VERSION ""

NS_ :

BS_:
BU_: Turbocharger OnBoardDataLogger OffBoardDiagnosticTool2 OffBoardDiagnosticTool1 FileServer ParkingBrakeController SeatControl2 FanDriveController SteeringColumnUnit CommunicationUnitRadio CommunicationUnitSatellite CommunicationUnitCellular PropulsionBatteryCharger ChassisController2 ChassisController1 EngineValveControl AuxiliaryHeater2 AuxiliaryHeater1 ClutchUnit RampControl InformationSystem1 SuspensionSystemController2 OilSensor VehicleDynamicStability ExhaustEmissionController TransmissionDisplay2 TransmissionDisplay1 ClimateControl2 WaterPumpController RearAxleSteeringController LightingOperatorControl SeatController1 IgnitionController2 IgnitionController1 TirePressureController CabController2 CabController1 PneumaticSystemController SuspensionSystemController1 HydraulicPumpController EnduranceBrakingSystem RetarderExhaustEngine2 OnBoardDiagnosticUnit HeadwayController RetarderExhaustEngine1 CabDisplay1 ManagementComputer VirtualTerminal OffVehicleGateway PowerTakeOffFront HitchControl AuxiliaryValveControl BodyController TractorTrailerBridge1 StarterSystem ElectricalSystem VehicleSecurity VehicleNavigation AerodynamicControl ElectricalChargingSystem ClimateControl1 TripRecorder InstrumentCluster SuspensionDriveAxle2 SuspensionDriveAxle1 SuspensionSteerAxle SteeringController FuelSystem CruiseControl RetarderDriveline RetarderEngine BrakesDriveAxle2 BrakesDriveAxle1 BrakesSystemController BrakesSteerAxle AxleDrive2 AxleDrive1 AxleSteering PowerTakeOff ShiftConsoleSecondary ShiftConsolePrimary Transmission2 Transmission1 Engine2 Engine1 Guidance Unnamed9933
BO_ 2566896298 SteerEngage: 0 Vector__XXX
   SG_ TrailerWeight : 0|16@1+ (2,0) [0|128510] "kg" Vector__XXX
   SG_ ReferenceTirePressSetting : 0|8@1+ (8,0) [0|2000] "kPa" Vector__XXX
   SG_ ReferenceTirePress : 0|8@1+ (8,0) [0|2000] "kPa" Vector__XXX
   SG_ TirePressThresholdDetection : 0|3@1+ (1,0) [0|7] "" Vector__XXX
   SG_ TireAirLeakageRate : 0|16@1+ (0.1,0) [0|6425.5] "Pa/s" Vector__XXX
   SG_ CTIWheelEndElectricalFault : 0|2@1+ (1,0) [0|3] "" Vector__XXX
   SG_ CTITireStatus : 0|2@1+ (1,0) [0|3] "" Vector__XXX
   SG_ CTIWheelSensorStatus : 0|2@1+ (1,0) [0|3] "" Vector__XXX
   SG_ TireTemp : 0|16@1+ (0.03125,-273) [-273|1734.97] "deg C" Vector__XXX
   SG_ TirePress : 0|8@1+ (4,0) [0|1000] "kPa" Vector__XXX
   SG_ SteerEngaged : 0|1@0+ (1,0) [0|1] "" Vector__XXX
   SG_ SteerEngage : 0|16@1+ (1,0) [0|1] "" Vector__XXX

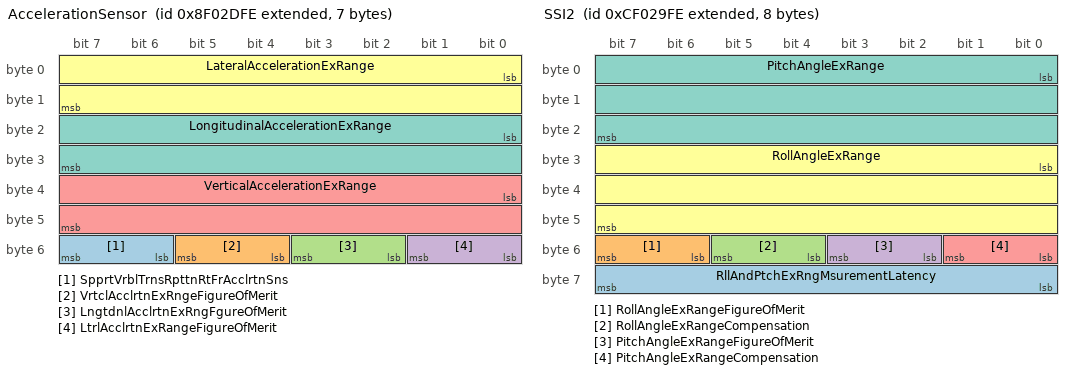
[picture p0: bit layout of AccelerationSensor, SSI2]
BO_ 2297441790 AccelerationSensor: 7 Vector__XXX
   SG_ SpprtVrblTrnsRpttnRtFrAcclrtnSns : 54|2@1+ (1,0) [0|3] "" Vector__XXX
   SG_ VrtclAcclrtnExRngeFigureOfMerit : 52|2@1+ (1,0) [0|3] "" Vector__XXX
   SG_ LngtdnlAcclrtnExRngFgureOfMerit : 50|2@1+ (1,0) [0|3] "" Vector__XXX
   SG_ LtrlAcclrtnExRangeFigureOfMerit : 48|2@1+ (1,0) [0|3] "" Vector__XXX
   SG_ VerticalAccelerationExRange : 32|16@1+ (0.01,-320) [-320|322.55] "m/s/s" Vector__XXX
   SG_ LateralAccelerationExRange : 0|16@1+ (0.01,-320) [-320|322.55] "m/s/s" Vector__XXX
   SG_ LongitudinalAccelerationExRange : 16|16@1+ (0.01,-320) [-320|322.55] "m/s/s" Vector__XXX

BO_ 2566712062 VEP4: 8 Vector__XXX
   SG_ HybrdBatteryPackRemainingCharge : 0|16@1+ (0.0025,0) [0|160.637] "%" Vector__XXX

BO_ 2364549630 SSI2: 8 Vector__XXX
   SG_ RllAndPtchExRngMsurementLatency : 56|8@1+ (0.5,0) [0|125] "ms" Vector__XXX
   SG_ RollAngleExRangeFigureOfMerit : 54|2@1+ (1,0) [0|3] "" Vector__XXX
   SG_ RollAngleExRangeCompensation : 52|2@1+ (1,0) [0|3] "" Vector__XXX
   SG_ PitchAngleExRangeFigureOfMerit : 50|2@1+ (1,0) [0|3] "" Vector__XXX
   SG_ PitchAngleExRangeCompensation : 48|2@1+ (1,0) [0|3] "" Vector__XXX
   SG_ RollAngleExRange : 24|24@1+ (3.05176e-05,-250) [-250|251] "deg" Vector__XXX
   SG_ PitchAngleExRange : 0|24@1+ (3.05176e-05,-250) [-250|251] "deg" Vector__XXX

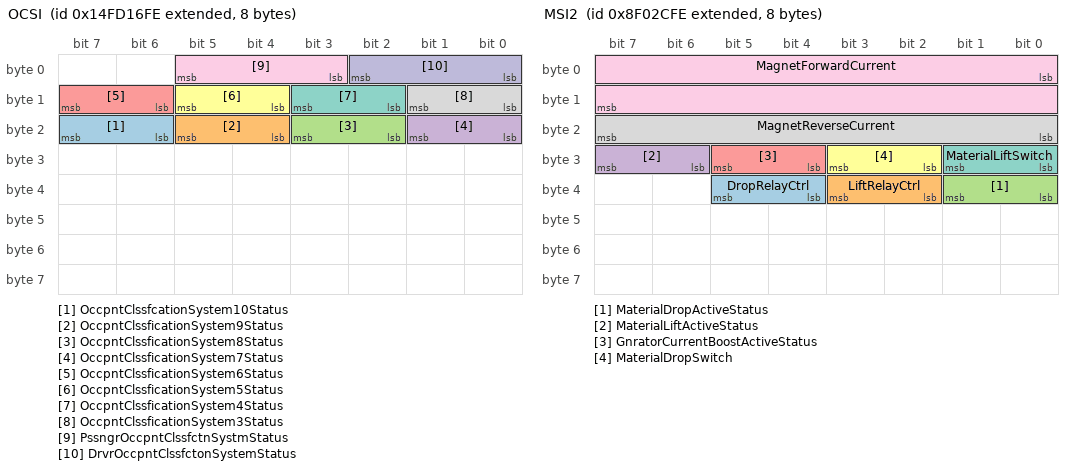
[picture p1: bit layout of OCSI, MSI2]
BO_ 2499614462 OCSI: 8 Vector__XXX
   SG_ OccpntClssfcationSystem10Status : 22|2@1+ (1,0) [0|3] "" Vector__XXX
   SG_ OccpntClssficationSystem9Status : 20|2@1+ (1,0) [0|3] "" Vector__XXX
   SG_ OccpntClssficationSystem8Status : 18|2@1+ (1,0) [0|3] "" Vector__XXX
   SG_ OccpntClssficationSystem7Status : 16|2@1+ (1,0) [0|3] "" Vector__XXX
   SG_ OccpntClssficationSystem6Status : 14|2@1+ (1,0) [0|3] "" Vector__XXX
   SG_ OccpntClssficationSystem5Status : 12|2@1+ (1,0) [0|3] "" Vector__XXX
   SG_ OccpntClssficationSystem4Status : 10|2@1+ (1,0) [0|3] "" Vector__XXX
   SG_ OccpntClssficationSystem3Status : 8|2@1+ (1,0) [0|3] "" Vector__XXX
   SG_ PssngrOccpntClssfctnSystmStatus : 3|3@1+ (1,0) [0|7] "" Vector__XXX
   SG_ DrvrOccpntClssfctonSystemStatus : 0|3@1+ (1,0) [0|7] "" Vector__XXX

BO_ 2560098046 NCS: 8 Vector__XXX
   SG_ CabNoiseCtrlTuningStatus : 2|4@1+ (1,0) [0|15] "" Vector__XXX
   SG_ CabNoiseCtrlStatus : 0|2@1+ (1,0) [0|3] "" Vector__XXX

BO_ 2560163582 NC1: 8 Vector__XXX
   SG_ CabNoiseCtrlTuningState : 2|3@1+ (1,0) [0|7] "" Vector__XXX
   SG_ CabNoiseCtrlState : 0|2@1+ (1,0) [0|3] "" Vector__XXX

BO_ 2297441534 MSI2: 8 Vector__XXX
   SG_ DropRelayCtrl : 36|2@1+ (1,0) [0|3] "" Vector__XXX
   SG_ LiftRelayCtrl : 34|2@1+ (1,0) [0|3] "" Vector__XXX
   SG_ MaterialDropActiveStatus : 32|2@1+ (1,0) [0|3] "" Vector__XXX
   SG_ MaterialLiftActiveStatus : 30|2@1+ (1,0) [0|3] "" Vector__XXX
   SG_ GnratorCurrentBoostActiveStatus : 28|2@1+ (1,0) [0|3] "" Vector__XXX
   SG_ MaterialDropSwitch : 26|2@1+ (1,0) [0|3] "" Vector__XXX
   SG_ MaterialLiftSwitch : 24|2@1+ (1,0) [0|3] "" Vector__XXX
   SG_ MagnetReverseCurrent : 16|8@1+ (1,0) [0|250] "A" Vector__XXX
   SG_ MagnetForwardCurrent : 0|16@1+ (1,0) [0|64255] "Amps" Vector__XXX

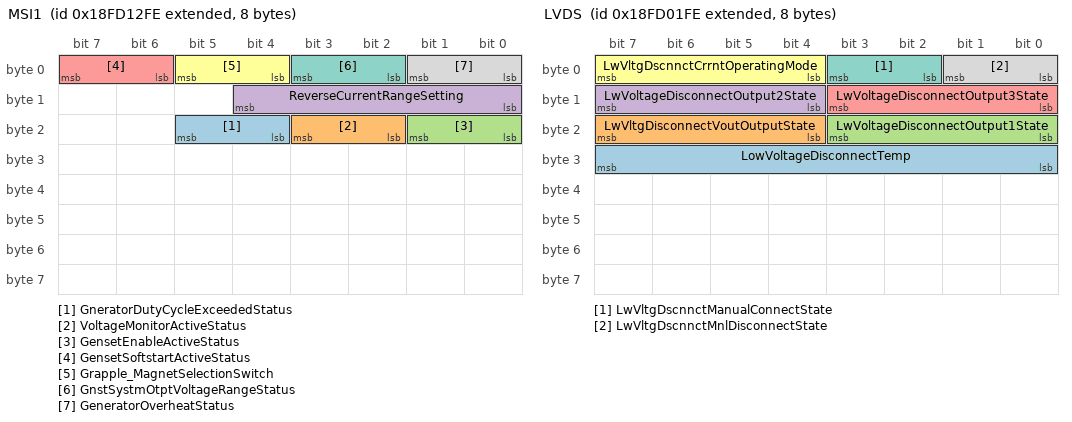
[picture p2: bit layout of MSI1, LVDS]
BO_ 2566722302 MSI1: 8 Vector__XXX
   SG_ GneratorDutyCycleExceededStatus : 20|2@1+ (1,0) [0|3] "" Vector__XXX
   SG_ VoltageMonitorActiveStatus : 18|2@1+ (1,0) [0|3] "" Vector__XXX
   SG_ GensetEnableActiveStatus : 16|2@1+ (1,0) [0|3] "" Vector__XXX
   SG_ ReverseCurrentRangeSetting : 8|5@1+ (1,0) [0|31] "" Vector__XXX
   SG_ GensetSoftstartActiveStatus : 6|2@1+ (1,0) [0|3] "" Vector__XXX
   SG_ Grapple_MagnetSelectionSwitch : 4|2@1+ (1,0) [0|3] "" Vector__XXX
   SG_ GnstSystmOtptVoltageRangeStatus : 2|2@1+ (1,0) [0|3] "" Vector__XXX
   SG_ GeneratorOverheatStatus : 0|2@1+ (1,0) [0|3] "" Vector__XXX

BO_ 2566722558 MSCI: 8 Vector__XXX
   SG_ MagnetRatedPower : 8|16@1+ (0.5,0) [0|32127.5] "kW" Vector__XXX
   SG_ MagnetBoostTime : 0|8@1+ (0.25,0) [0|62.5] "s" Vector__XXX

BO_ 2560032510 LVDSOM: 8 Vector__XXX
   SG_ LwVltgDscnnctDsredOperatingMode : 0|4@1+ (1,0) [0|15] "" Vector__XXX

BO_ 2566717950 LVDS: 8 Vector__XXX
   SG_ LowVoltageDisconnectTemp : 24|8@1+ (1,-40) [-40|210] "deg C" Vector__XXX
   SG_ LwVltgDisconnectVoutOutputState : 20|4@1+ (1,0) [0|15] "" Vector__XXX
   SG_ LwVoltageDisconnectOutput1State : 16|4@1+ (1,0) [0|15] "" Vector__XXX
   SG_ LwVoltageDisconnectOutput2State : 12|4@1+ (1,0) [0|15] "" Vector__XXX
   SG_ LwVoltageDisconnectOutput3State : 8|4@1+ (1,0) [0|15] "" Vector__XXX
   SG_ LwVltgDscnnctCrrntOperatingMode : 4|4@1+ (1,0) [0|15] "" Vector__XXX
   SG_ LwVltgDscnnctManualConnectState : 2|2@1+ (1,0) [0|3] "" Vector__XXX
   SG_ LwVltgDscnnctMnlDisconnectState : 0|2@1+ (1,0) [0|3] "" Vector__XXX

BO_ 2499604222 LLRE: 8 Vector__XXX
   SG_ BldRferenceElevationOffsetRight : 48|16@1+ (1,-32000) [-32000|32255] "mm" Vector__XXX
   SG_ BldReferenceElevationOffsetLeft : 32|16@1+ (1,-32000) [-32000|32255] "mm" Vector__XXX
   SG_ BladeElevationDeviationRight : 16|16@1+ (1,-32000) [-32000|32255] "mm" Vector__XXX
   SG_ BladeElevationDeviationLeft : 0|16@1+ (1,-32000) [-32000|32255] "mm" Vector__XXX

BO_ 2358902526 JLCM: 8 Vector__XXX
   SG_ Joystick3Lamp10Cmd : 58|2@1+ (1,0) [0|3] "" Vector__XXX
   SG_ Joystick3Lamp9Cmd : 56|2@1+ (1,0) [0|3] "" Vector__XXX
   SG_ Joystick3Lamp8Cmd : 54|2@1+ (1,0) [0|3] "" Vector__XXX
   SG_ Joystick3Lamp7Cmd : 52|2@1+ (1,0) [0|3] "" Vector__XXX
   SG_ Joystick3Lamp6Cmd : 50|2@1+ (1,0) [0|3] "" Vector__XXX
   SG_ Joystick3Lamp5Cmd : 48|2@1+ (1,0) [0|3] "" Vector__XXX
   SG_ Joystick3Lamp4Cmd : 46|2@1+ (1,0) [0|3] "" Vector__XXX
   SG_ Joystick3Lamp3Cmd : 44|2@1+ (1,0) [0|3] "" Vector__XXX
   SG_ Joystick3Lamp2Cmd : 42|2@1+ (1,0) [0|3] "" Vector__XXX
   SG_ Joystick3Lamp1Cmd : 40|2@1+ (1,0) [0|3] "" Vector__XXX
   SG_ Joystick2Lamp10Cmd : 38|2@1+ (1,0) [0|3] "" Vector__XXX
   SG_ Joystick2Lamp9Cmd : 36|2@1+ (1,0) [0|3] "" Vector__XXX
   SG_ Joystick2Lamp8Cmd : 34|2@1+ (1,0) [0|3] "" Vector__XXX
   SG_ Joystick2Lamp7Cmd : 32|2@1+ (1,0) [0|3] "" Vector__XXX
   SG_ Joystick2Lamp6Cmd : 30|2@1+ (1,0) [0|3] "" Vector__XXX
   SG_ Joystick2Lamp5Cmd : 28|2@1+ (1,0) [0|3] "" Vector__XXX
   SG_ Joystick2Lamp4Cmd : 26|2@1+ (1,0) [0|3] "" Vector__XXX
   SG_ Joystick2Lamp3Cmd : 24|2@1+ (1,0) [0|3] "" Vector__XXX
   SG_ Joystick2Lamp2Cmd : 22|2@1+ (1,0) [0|3] "" Vector__XXX
   SG_ Joystick2Lamp1Cmd : 20|2@1+ (1,0) [0|3] "" Vector__XXX
   SG_ Joystick1Lamp10Cmd : 18|2@1+ (1,0) [0|3] "" Vector__XXX
   SG_ Joystick1Lamp9Cmd : 16|2@1+ (1,0) [0|3] "" Vector__XXX
   SG_ Joystick1Lamp8Cmd : 14|2@1+ (1,0) [0|3] "" Vector__XXX
   SG_ Joystick1Lamp7Cmd : 12|2@1+ (1,0) [0|3] "" Vector__XXX
   SG_ Joystick1Lamp6Cmd : 10|2@1+ (1,0) [0|3] "" Vector__XXX
   SG_ Joystick1Lamp5Cmd : 8|2@1+ (1,0) [0|3] "" Vector__XXX
   SG_ Joystick1Lamp4Cmd : 6|2@1+ (1,0) [0|3] "" Vector__XXX
   SG_ Joystick1Lamp3Cmd : 4|2@1+ (1,0) [0|3] "" Vector__XXX
   SG_ Joystick1Lamp2Cmd : 2|2@1+ (1,0) [0|3] "" Vector__XXX
   SG_ Joystick1Lamp1Cmd : 0|2@1+ (1,0) [0|3] "" Vector__XXX

BO_ 2566711550 IVAC: 8 Vector__XXX
   SG_ IntkVlvActtnSystmOlPrss2SlndCtrl : 2|2@1+ (1,0) [0|3] "" Vector__XXX
   SG_ IntkVlvActtnSystmOlPrss1SlndCtrl : 0|2@1+ (1,0) [0|3] "" Vector__XXX

BO_ 2633832958 ILI: 200 Vector__XXX
   SG_ SpecialIgnitorLoop90Resistance : 1584|16@1+ (0.1,0) [0|6425.5] "ohm" Vector__XXX
   SG_ SpecialIgnitorLoop89Resistance : 1568|16@1+ (0.1,0) [0|6425.5] "ohm" Vector__XXX
   SG_ SpecialIgnitorLoop88Resistance : 1552|16@1+ (0.1,0) [0|6425.5] "ohm" Vector__XXX
   SG_ SpecialIgnitorLoop87Resistance : 1536|16@1+ (0.1,0) [0|6425.5] "ohm" Vector__XXX
   SG_ SpecialIgnitorLoop86Resistance : 1520|16@1+ (0.1,0) [0|6425.5] "ohm" Vector__XXX
   SG_ SpecialIgnitorLoop85Resistance : 1504|16@1+ (0.1,0) [0|6425.5] "ohm" Vector__XXX
   SG_ SpecialIgnitorLoop84Resistance : 1488|16@1+ (0.1,0) [0|6425.5] "ohm" Vector__XXX
   SG_ SpecialIgnitorLoop83Resistance : 1472|16@1+ (0.1,0) [0|6425.5] "ohm" Vector__XXX
   SG_ SpecialIgnitorLoop82Resistance : 1456|16@1+ (0.1,0) [0|6425.5] "ohm" Vector__XXX
   SG_ SpecialIgnitorLoop81Resistance : 1440|16@1+ (0.1,0) [0|6425.5] "ohm" Vector__XXX
   SG_ SpecialIgnitorLoop80Resistance : 1424|16@1+ (0.1,0) [0|6425.5] "ohm" Vector__XXX
   SG_ SpecialIgnitorLoop79Resistance : 1408|16@1+ (0.1,0) [0|6425.5] "ohm" Vector__XXX
   SG_ SpecialIgnitorLoop78Resistance : 1392|16@1+ (0.1,0) [0|6425.5] "ohm" Vector__XXX
   SG_ SpecialIgnitorLoop77Resistance : 1376|16@1+ (0.1,0) [0|6425.5] "ohm" Vector__XXX
   SG_ SpecialIgnitorLoop76Resistance : 1360|16@1+ (0.1,0) [0|6425.5] "ohm" Vector__XXX
   SG_ SpecialIgnitorLoop75Resistance : 1344|16@1+ (0.1,0) [0|6425.5] "ohm" Vector__XXX
   SG_ SpecialIgnitorLoop74Resistance : 1328|16@1+ (0.1,0) [0|6425.5] "ohm" Vector__XXX
   SG_ SpecialIgnitorLoop73Resistance : 1312|16@1+ (0.1,0) [0|6425.5] "ohm" Vector__XXX
   SG_ SpecialIgnitorLoop72Resistance : 1296|16@1+ (0.1,0) [0|6425.5] "ohm" Vector__XXX
   SG_ SpecialIgnitorLoop71Resistance : 1280|16@1+ (0.1,0) [0|6425.5] "ohm" Vector__XXX
   SG_ SpecialIgnitorLoop70Resistance : 1264|16@1+ (0.1,0) [0|6425.5] "ohm" Vector__XXX
   SG_ SpecialIgnitorLoop69Resistance : 1248|16@1+ (0.1,0) [0|6425.5] "ohm" Vector__XXX
   SG_ SpecialIgnitorLoop68Resistance : 1232|16@1+ (0.1,0) [0|6425.5] "ohm" Vector__XXX
   SG_ SpecialIgnitorLoop67Resistance : 1216|16@1+ (0.1,0) [0|6425.5] "ohm" Vector__XXX
   SG_ SpecialIgnitorLoop66Resistance : 1200|16@1+ (0.1,0) [0|6425.5] "ohm" Vector__XXX
   SG_ SpecialIgnitorLoop65Resistance : 1184|16@1+ (0.1,0) [0|6425.5] "ohm" Vector__XXX
   SG_ SpecialIgnitorLoop64Resistance : 1168|16@1+ (0.1,0) [0|6425.5] "ohm" Vector__XXX
   SG_ SpecialIgnitorLoop63Resistance : 1152|16@1+ (0.1,0) [0|6425.5] "ohm" Vector__XXX
   SG_ SpecialIgnitorLoop61Resistance : 1120|16@1+ (0.1,0) [0|6425.5] "ohm" Vector__XXX
   SG_ SpecialIgnitorLoop60Resistance : 1104|16@1+ (0.1,0) [0|6425.5] "ohm" Vector__XXX
   SG_ SpecialIgnitorLoop59Resistance : 1088|16@1+ (0.1,0) [0|6425.5] "ohm" Vector__XXX
   SG_ SpecialIgnitorLoop58Resistance : 1072|16@1+ (0.1,0) [0|6425.5] "ohm" Vector__XXX
   SG_ SpecialIgnitorLoop57Resistance : 1056|16@1+ (0.1,0) [0|6425.5] "ohm" Vector__XXX
   SG_ SpecialIgnitorLoop56Resistance : 1040|16@1+ (0.1,0) [0|6425.5] "ohm" Vector__XXX
   SG_ SpecialIgnitorLoop55Resistance : 1024|16@1+ (0.1,0) [0|6425.5] "ohm" Vector__XXX
   SG_ SpecialIgnitorLoop54Resistance : 1008|16@1+ (0.1,0) [0|6425.5] "ohm" Vector__XXX
   SG_ SpecialIgnitorLoop53Resistance : 992|16@1+ (0.1,0) [0|6425.5] "ohm" Vector__XXX
   SG_ SpecialIgnitorLoop52Resistance : 976|16@1+ (0.1,0) [0|6425.5] "ohm" Vector__XXX
   SG_ SpecialIgnitorLoop51Resistance : 960|16@1+ (0.1,0) [0|6425.5] "ohm" Vector__XXX
   SG_ SpecialIgnitorLoop50Resistance : 944|16@1+ (0.1,0) [0|6425.5] "ohm" Vector__XXX
   SG_ SpecialIgnitorLoop49Resistance : 928|16@1+ (0.1,0) [0|6425.5] "ohm" Vector__XXX
   SG_ SpecialIgnitorLoop48Resistance : 912|16@1+ (0.1,0) [0|6425.5] "ohm" Vector__XXX
   SG_ SpecialIgnitorLoop47Resistance : 896|16@1+ (0.1,0) [0|6425.5] "ohm" Vector__XXX
   SG_ SpecialIgnitorLoop46Resistance : 880|16@1+ (0.1,0) [0|6425.5] "ohm" Vector__XXX
   SG_ SpecialIgnitorLoop45Resistance : 864|16@1+ (0.1,0) [0|6425.5] "ohm" Vector__XXX
   SG_ SpecialIgnitorLoop44Resistance : 848|16@1+ (0.1,0) [0|6425.5] "ohm" Vector__XXX
   SG_ SpecialIgnitorLoop43Resistance : 832|16@1+ (0.1,0) [0|6425.5] "ohm" Vector__XXX
   SG_ SpecialIgnitorLoop42Resistance : 816|16@1+ (0.1,0) [0|6425.5] "ohm" Vector__XXX
   SG_ SpecialIgnitorLoop41Resistance : 800|16@1+ (0.1,0) [0|6425.5] "ohm" Vector__XXX
   SG_ SpecialIgnitorLoop40Resistance : 784|16@1+ (0.1,0) [0|6425.5] "ohm" Vector__XXX
   SG_ SpecialIgnitorLoop39Resistance : 768|16@1+ (0.1,0) [0|6425.5] "ohm" Vector__XXX
   SG_ SpecialIgnitorLoop38Resistance : 752|16@1+ (0.1,0) [0|6425.5] "ohm" Vector__XXX
   SG_ SpecialIgnitorLoop37Resistance : 736|16@1+ (0.1,0) [0|6425.5] "ohm" Vector__XXX
   SG_ SpecialIgnitorLoop36Resistance : 720|16@1+ (0.1,0) [0|6425.5] "ohm" Vector__XXX
   SG_ SpecialIgnitorLoop35Resistance : 704|16@1+ (0.1,0) [0|6425.5] "ohm" Vector__XXX
   SG_ SpecialIgnitorLoop34Resistance : 688|16@1+ (0.1,0) [0|6425.5] "ohm" Vector__XXX
   SG_ SpecialIgnitorLoop33Resistance : 672|16@1+ (0.1,0) [0|6425.5] "ohm" Vector__XXX
   SG_ SpecialIgnitorLoop32Resistance : 656|16@1+ (0.1,0) [0|6425.5] "ohm" Vector__XXX
   SG_ SpecialIgnitorLoop31Resistance : 640|16@1+ (0.1,0) [0|6425.5] "ohm" Vector__XXX
   SG_ SpecialIgnitorLoop30Resistance : 624|16@1+ (0.1,0) [0|6425.5] "ohm" Vector__XXX
   SG_ SpecialIgnitorLoop29Resistance : 608|16@1+ (0.1,0) [0|6425.5] "ohm" Vector__XXX
   SG_ SpecialIgnitorLoop28Resistance : 592|16@1+ (0.1,0) [0|6425.5] "ohm" Vector__XXX
   SG_ SpecialIgnitorLoop27Resistance : 576|16@1+ (0.1,0) [0|6425.5] "ohm" Vector__XXX
   SG_ SpecialIgnitorLoop26Resistance : 560|16@1+ (0.1,0) [0|6425.5] "ohm" Vector__XXX
   SG_ SpecialIgnitorLoop25Resistance : 544|16@1+ (0.1,0) [0|6425.5] "ohm" Vector__XXX
   SG_ SpecialIgnitorLoop24Resistance : 528|16@1+ (0.1,0) [0|6425.5] "ohm" Vector__XXX
   SG_ SpecialIgnitorLoop23Resistance : 512|16@1+ (0.1,0) [0|6425.5] "ohm" Vector__XXX
   SG_ SpecialIgnitorLoop22Resistance : 496|16@1+ (0.1,0) [0|6425.5] "ohm" Vector__XXX
   SG_ SpecialIgnitorLoop21Resistance : 480|16@1+ (0.1,0) [0|6425.5] "ohm" Vector__XXX
   SG_ SpecialIgnitorLoop20Resistance : 464|16@1+ (0.1,0) [0|6425.5] "ohm" Vector__XXX
   SG_ SpecialIgnitorLoop19Resistance : 448|16@1+ (0.1,0) [0|6425.5] "ohm" Vector__XXX
   SG_ SpecialIgnitorLoop18Resistance : 432|16@1+ (0.1,0) [0|6425.5] "ohm" Vector__XXX
   SG_ SpecialIgnitorLoop17Resistance : 416|16@1+ (0.1,0) [0|6425.5] "ohm" Vector__XXX
   SG_ SpecialIgnitorLoop16Resistance : 400|16@1+ (0.1,0) [0|6425.5] "ohm" Vector__XXX
   SG_ SpecialIgnitorLoop15Resistance : 384|16@1+ (0.1,0) [0|6425.5] "ohm" Vector__XXX
   SG_ SpecialIgnitorLoop14Resistance : 368|16@1+ (0.1,0) [0|6425.5] "ohm" Vector__XXX
   SG_ SpecialIgnitorLoop13Resistance : 352|16@1+ (0.1,0) [0|6425.5] "ohm" Vector__XXX
   SG_ SpecialIgnitorLoop12Resistance : 336|16@1+ (0.1,0) [0|6425.5] "ohm" Vector__XXX
   SG_ SpecialIgnitorLoop11Resistance : 320|16@1+ (0.1,0) [0|6425.5] "ohm" Vector__XXX
   SG_ SpecialIgnitorLoop10Resistance : 304|16@1+ (0.1,0) [0|6425.5] "ohm" Vector__XXX
   SG_ SpecialIgnitorLoop9Resistance : 288|16@1+ (0.1,0) [0|6425.5] "ohm" Vector__XXX
   SG_ SpecialIgnitorLoop8Resistance : 272|16@1+ (0.1,0) [0|6425.5] "ohm" Vector__XXX
   SG_ SpecialIgnitorLoop7Resistance : 256|16@1+ (0.1,0) [0|6425.5] "ohm" Vector__XXX
   SG_ SpecialIgnitorLoop6Resistance : 240|16@1+ (0.1,0) [0|6425.5] "ohm" Vector__XXX
   SG_ SpecialIgnitorLoop5Resistance : 224|16@1+ (0.1,0) [0|6425.5] "ohm" Vector__XXX
   SG_ SpecialIgnitorLoop4Resistance : 208|16@1+ (0.1,0) [0|6425.5] "ohm" Vector__XXX
   SG_ SpecialIgnitorLoop3Resistance : 192|16@1+ (0.1,0) [0|6425.5] "ohm" Vector__XXX
   SG_ SpecialIgnitorLoop2Resistance : 176|16@1+ (0.1,0) [0|6425.5] "ohm" Vector__XXX
   SG_ SpecialIgnitorLoop1Resistance : 160|16@1+ (0.1,0) [0|6425.5] "ohm" Vector__XXX
   SG_ SdBgIgnitorLoop2RightResistance : 144|16@1+ (0.1,0) [0|6425.5] "ohm" Vector__XXX
   SG_ SdBgIgnitorLoop1RightResistance : 128|16@1+ (0.1,0) [0|6425.5] "ohm" Vector__XXX
   SG_ SdBagIgnitorLoop2LeftResistance : 112|16@1+ (0.1,0) [0|6425.5] "ohm" Vector__XXX
   SG_ SdBagIgnitorLoop1LeftResistance : 96|16@1+ (0.1,0) [0|6425.5] "ohm" Vector__XXX
   SG_ PssngrBltTnsnrIgntrLpResistance : 80|16@1+ (0.1,0) [0|6425.5] "ohm" Vector__XXX
   SG_ DrvrBltTnsnrIgntrLoopResistance : 64|16@1+ (0.1,0) [0|6425.5] "ohm" Vector__XXX
   SG_ PssngrArbgIgntrLp2ndStgRsstance : 48|16@1+ (0.1,0) [0|6425.5] "ohm" Vector__XXX
   SG_ DrvrArbgIgntrLp2ndStgResistance : 32|16@1+ (0.1,0) [0|6425.5] "ohm" Vector__XXX
   SG_ PssngrArbgIgntrLp1stStgRsstance : 16|16@1+ (0.1,0) [0|6425.5] "ohm" Vector__XXX
   SG_ DrvrArbgIgntrLp1stStgResistance : 0|16@1+ (0.1,0) [0|6425.5] "ohm" Vector__XXX

BO_ 2566719998 HRLFC: 8 Vector__XXX
   SG_ HighResolutionEngTotalFuelUsed : 32|32@1+ (0.001,0) [0|4.21108e+06] "L" Vector__XXX
   SG_ HighResolutionEngTripFuel : 0|32@1+ (0.001,0) [0|4.21108e+06] "L" Vector__XXX

BO_ 2565877502 EngTrboWastegateActuatorCtrlCmd: 8 Vector__XXX
   SG_ EngTurboWastegateActuator2Cmd : 16|16@1+ (0.0025,0) [0|160.637] "%" Vector__XXX
   SG_ EngTurboWastegateActuator1Cmd : 0|16@1+ (0.0025,0) [0|160.637] "%" Vector__XXX

BO_ 2566713854 EngTrbWstgteActuatorInformation: 8 Vector__XXX
   SG_ EngTrbWstgtActtr2OprationStatus : 12|4@1+ (1,0) [0|15] "" Vector__XXX
   SG_ EngTrbWstgtActtr1OprationStatus : 8|4@1+ (1,0) [0|15] "" Vector__XXX
   SG_ EngTrbWstgteActuator2TempStatus : 5|3@1+ (1,0) [0|7] "" Vector__XXX
   SG_ EngTrbWstgtActtr2PreliminaryFMI : 0|5@1+ (1,0) [0|31] "" Vector__XXX

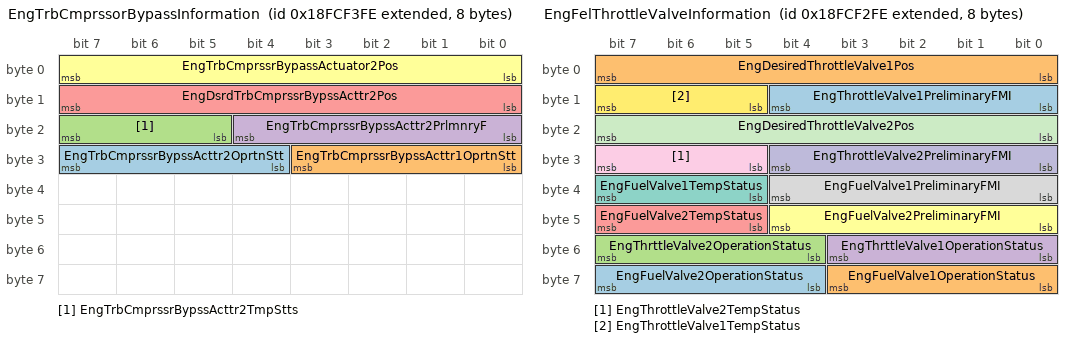
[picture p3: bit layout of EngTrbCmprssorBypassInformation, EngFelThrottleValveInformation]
BO_ 2566714366 EngTrbCmprssorBypassInformation: 8 Vector__XXX
   SG_ EngTrbCmprssrBypssActtr2OprtnStt : 28|4@1+ (1,0) [0|15] "" Vector__XXX
   SG_ EngTrbCmprssrBypssActtr1OprtnStt : 24|4@1+ (1,0) [0|15] "" Vector__XXX
   SG_ EngTrbCmprssrBypssActtr2TmpStts : 21|3@1+ (1,0) [0|7] "" Vector__XXX
   SG_ EngTrbCmprssrBypssActtr2PrlmnryF : 16|5@1+ (1,0) [0|31] "" Vector__XXX
   SG_ EngDsrdTrbCmprssrBypssActtr2Pos : 8|8@1+ (0.4,0) [0|100] "%" Vector__XXX
   SG_ EngTrbCmprssrBypassActuator2Pos : 0|8@1+ (0.4,0) [0|100] "%" Vector__XXX

BO_ 2566714110 EngFelThrottleValveInformation: 8 Vector__XXX
   SG_ EngFuelValve2OperationStatus : 60|4@1+ (1,0) [0|15] "" Vector__XXX
   SG_ EngFuelValve1OperationStatus : 56|4@1+ (1,0) [0|15] "" Vector__XXX
   SG_ EngThrttleValve2OperationStatus : 52|4@1+ (1,0) [0|15] "" Vector__XXX
   SG_ EngThrttleValve1OperationStatus : 48|4@1+ (1,0) [0|15] "" Vector__XXX
   SG_ EngFuelValve2TempStatus : 45|3@1+ (1,0) [0|7] "" Vector__XXX
   SG_ EngFuelValve2PreliminaryFMI : 40|5@1+ (1,0) [0|31] "" Vector__XXX
   SG_ EngFuelValve1TempStatus : 37|3@1+ (1,0) [0|7] "" Vector__XXX
   SG_ EngFuelValve1PreliminaryFMI : 32|5@1+ (1,0) [0|31] "" Vector__XXX
   SG_ EngThrottleValve2TempStatus : 29|3@1+ (1,0) [0|7] "" Vector__XXX
   SG_ EngThrottleValve2PreliminaryFMI : 24|5@1+ (1,0) [0|31] "" Vector__XXX
   SG_ EngDesiredThrottleValve2Pos : 16|8@1+ (0.4,0) [0|100] "%" Vector__XXX
   SG_ EngThrottleValve1TempStatus : 13|3@1+ (1,0) [0|7] "" Vector__XXX
   SG_ EngThrottleValve1PreliminaryFMI : 8|5@1+ (1,0) [0|31] "" Vector__XXX
   SG_ EngDesiredThrottleValve1Pos : 0|8@1+ (0.4,0) [0|100] "%" Vector__XXX

BO_ 2566717438 ET5: 8 Vector__XXX
   SG_ EngExhstGsRcrcltn2MxrIntakeTemp : 16|16@1+ (0.03125,-273) [-273|1734.97] "deg C" Vector__XXX
   SG_ EngExhaustGasRecirculation2Temp : 0|16@1+ (0.03125,-273) [-273|1734.97] "deg C" Vector__XXX

BO_ 2633828606 EOM: 8 Vector__XXX
   SG_ EngOilRelativeDielectricity : 32|16@1+ (0.00012207,0) [0|7.844] "" Vector__XXX
   SG_ EngOilDensity : 16|16@1+ (3.052e-05,0) [0|1.961] "g/cc" Vector__XXX
   SG_ EngOilViscosity : 0|16@1+ (0.015625,0) [0|1003.98] "Cp" Vector__XXX

BO_ 2499607550 EMAP: 8 Vector__XXX
   SG_ EngExhstMnfldBnk2FlwBlncVlvActtr : 16|16@1+ (0.0025,0) [0|160.637] "%" Vector__XXX
   SG_ EngExhstMnfldBnk1FlwBlncVlvActtr : 0|16@1+ (0.0025,0) [0|160.637] "%" Vector__XXX

BO_ 2633825534 EMAC: 8 Vector__XXX
   SG_ EngExhstMnfldBnk2FlwBlncVlv_0000 : 16|16@1+ (0.0025,0) [0|160.637] "%" Vector__XXX
   SG_ EngExhstMnfldBnk1FlwBlncVlv_0000 : 0|16@1+ (0.0025,0) [0|160.637] "%" Vector__XXX

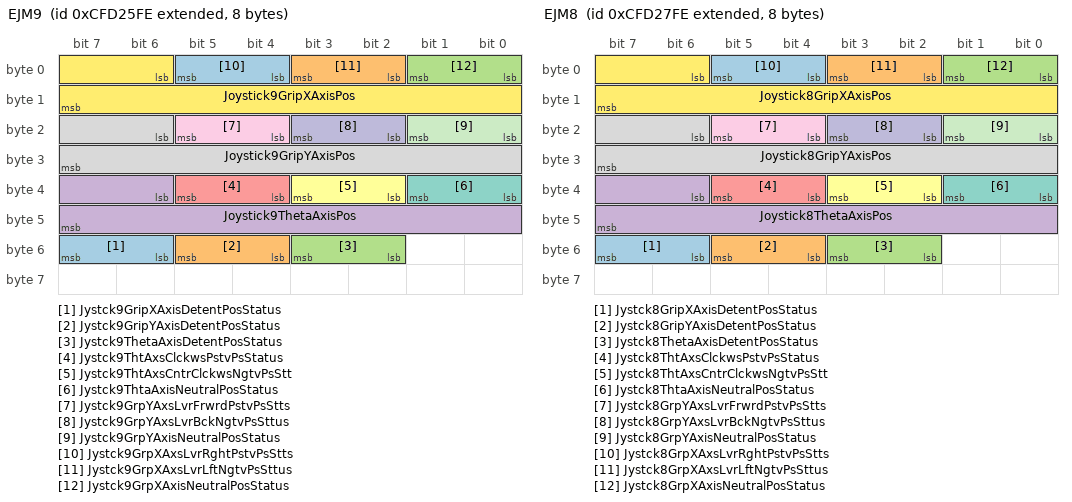
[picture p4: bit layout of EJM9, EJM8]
BO_ 2365400574 EJM9: 8 Vector__XXX
   SG_ Jystck9GripXAxisDetentPosStatus : 54|2@1+ (1,0) [0|3] "" Vector__XXX
   SG_ Jystck9GripYAxisDetentPosStatus : 52|2@1+ (1,0) [0|3] "" Vector__XXX
   SG_ Jystck9ThetaAxisDetentPosStatus : 50|2@1+ (1,0) [0|3] "" Vector__XXX
   SG_ Joystick9ThetaAxisPos : 38|10@1+ (0.1,0) [0|102] "%" Vector__XXX
   SG_ Jystck9ThtAxsClckwsPstvPsStatus : 36|2@1+ (1,0) [0|3] "" Vector__XXX
   SG_ Jystck9ThtAxsCntrClckwsNgtvPsStt : 34|2@1+ (1,0) [0|3] "" Vector__XXX
   SG_ Jystck9ThtaAxisNeutralPosStatus : 32|2@1+ (1,0) [0|3] "" Vector__XXX
   SG_ Joystick9GripYAxisPos : 22|10@1+ (0.1,0) [0|102] "%" Vector__XXX
   SG_ Jystck9GrpYAxsLvrFrwrdPstvPsStts : 20|2@1+ (1,0) [0|3] "" Vector__XXX
   SG_ Jystck9GrpYAxsLvrBckNgtvPsSttus : 18|2@1+ (1,0) [0|3] "" Vector__XXX
   SG_ Jystck9GrpYAxisNeutralPosStatus : 16|2@1+ (1,0) [0|3] "" Vector__XXX
   SG_ Joystick9GripXAxisPos : 6|10@1+ (0.1,0) [0|102] "%" Vector__XXX
   SG_ Jystck9GrpXAxsLvrRghtPstvPsStts : 4|2@1+ (1,0) [0|3] "" Vector__XXX
   SG_ Jystck9GrpXAxsLvrLftNgtvPsSttus : 2|2@1+ (1,0) [0|3] "" Vector__XXX
   SG_ Jystck9GrpXAxisNeutralPosStatus : 0|2@1+ (1,0) [0|3] "" Vector__XXX

BO_ 2365401086 EJM8: 8 Vector__XXX
   SG_ Jystck8GripXAxisDetentPosStatus : 54|2@1+ (1,0) [0|3] "" Vector__XXX
   SG_ Jystck8GripYAxisDetentPosStatus : 52|2@1+ (1,0) [0|3] "" Vector__XXX
   SG_ Jystck8ThetaAxisDetentPosStatus : 50|2@1+ (1,0) [0|3] "" Vector__XXX
   SG_ Joystick8ThetaAxisPos : 38|10@1+ (0.1,0) [0|102] "%" Vector__XXX
   SG_ Jystck8ThtAxsClckwsPstvPsStatus : 36|2@1+ (1,0) [0|3] "" Vector__XXX
   SG_ Jystck8ThtAxsCntrClckwsNgtvPsStt : 34|2@1+ (1,0) [0|3] "" Vector__XXX
   SG_ Jystck8ThtaAxisNeutralPosStatus : 32|2@1+ (1,0) [0|3] "" Vector__XXX
   SG_ Joystick8GripYAxisPos : 22|10@1+ (0.1,0) [0|102] "%" Vector__XXX
   SG_ Jystck8GrpYAxsLvrFrwrdPstvPsStts : 20|2@1+ (1,0) [0|3] "" Vector__XXX
   SG_ Jystck8GrpYAxsLvrBckNgtvPsSttus : 18|2@1+ (1,0) [0|3] "" Vector__XXX
   SG_ Jystck8GrpYAxisNeutralPosStatus : 16|2@1+ (1,0) [0|3] "" Vector__XXX
   SG_ Joystick8GripXAxisPos : 6|10@1+ (0.1,0) [0|102] "%" Vector__XXX
   SG_ Jystck8GrpXAxsLvrRghtPstvPsStts : 4|2@1+ (1,0) [0|3] "" Vector__XXX
   SG_ Jystck8GrpXAxsLvrLftNgtvPsSttus : 2|2@1+ (1,0) [0|3] "" Vector__XXX
   SG_ Jystck8GrpXAxisNeutralPosStatus : 0|2@1+ (1,0) [0|3] "" Vector__XXX

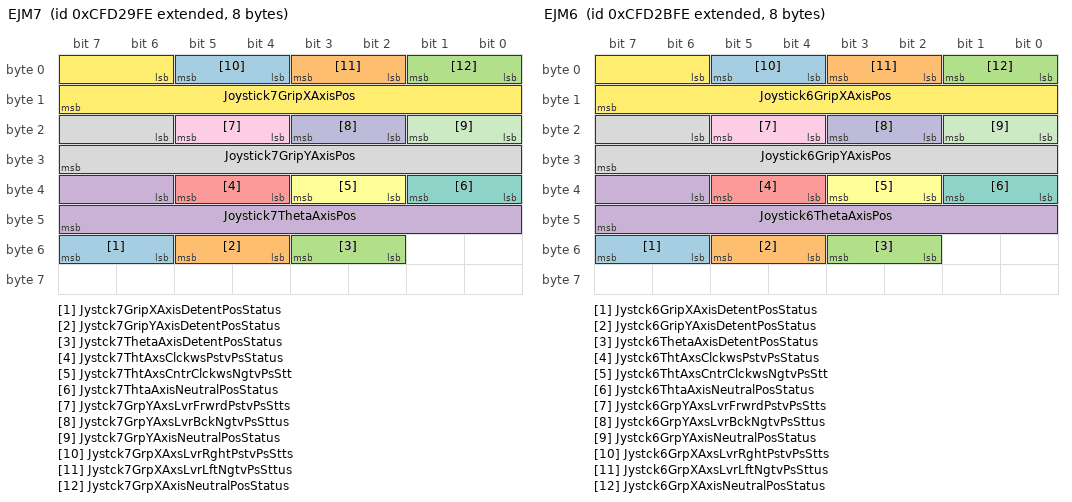
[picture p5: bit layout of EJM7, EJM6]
BO_ 2365401598 EJM7: 8 Vector__XXX
   SG_ Jystck7GripXAxisDetentPosStatus : 54|2@1+ (1,0) [0|3] "" Vector__XXX
   SG_ Jystck7GripYAxisDetentPosStatus : 52|2@1+ (1,0) [0|3] "" Vector__XXX
   SG_ Jystck7ThetaAxisDetentPosStatus : 50|2@1+ (1,0) [0|3] "" Vector__XXX
   SG_ Joystick7ThetaAxisPos : 38|10@1+ (0.1,0) [0|102] "%" Vector__XXX
   SG_ Jystck7ThtAxsClckwsPstvPsStatus : 36|2@1+ (1,0) [0|3] "" Vector__XXX
   SG_ Jystck7ThtAxsCntrClckwsNgtvPsStt : 34|2@1+ (1,0) [0|3] "" Vector__XXX
   SG_ Jystck7ThtaAxisNeutralPosStatus : 32|2@1+ (1,0) [0|3] "" Vector__XXX
   SG_ Joystick7GripYAxisPos : 22|10@1+ (0.1,0) [0|102] "%" Vector__XXX
   SG_ Jystck7GrpYAxsLvrFrwrdPstvPsStts : 20|2@1+ (1,0) [0|3] "" Vector__XXX
   SG_ Jystck7GrpYAxsLvrBckNgtvPsSttus : 18|2@1+ (1,0) [0|3] "" Vector__XXX
   SG_ Jystck7GrpYAxisNeutralPosStatus : 16|2@1+ (1,0) [0|3] "" Vector__XXX
   SG_ Joystick7GripXAxisPos : 6|10@1+ (0.1,0) [0|102] "%" Vector__XXX
   SG_ Jystck7GrpXAxsLvrRghtPstvPsStts : 4|2@1+ (1,0) [0|3] "" Vector__XXX
   SG_ Jystck7GrpXAxsLvrLftNgtvPsSttus : 2|2@1+ (1,0) [0|3] "" Vector__XXX
   SG_ Jystck7GrpXAxisNeutralPosStatus : 0|2@1+ (1,0) [0|3] "" Vector__XXX

BO_ 2365402110 EJM6: 8 Vector__XXX
   SG_ Jystck6GripXAxisDetentPosStatus : 54|2@1+ (1,0) [0|3] "" Vector__XXX
   SG_ Jystck6GripYAxisDetentPosStatus : 52|2@1+ (1,0) [0|3] "" Vector__XXX
   SG_ Jystck6ThetaAxisDetentPosStatus : 50|2@1+ (1,0) [0|3] "" Vector__XXX
   SG_ Joystick6ThetaAxisPos : 38|10@1+ (0.1,0) [0|102] "%" Vector__XXX
   SG_ Jystck6ThtAxsClckwsPstvPsStatus : 36|2@1+ (1,0) [0|3] "" Vector__XXX
   SG_ Jystck6ThtAxsCntrClckwsNgtvPsStt : 34|2@1+ (1,0) [0|3] "" Vector__XXX
   SG_ Jystck6ThtaAxisNeutralPosStatus : 32|2@1+ (1,0) [0|3] "" Vector__XXX
   SG_ Joystick6GripYAxisPos : 22|10@1+ (0.1,0) [0|102] "%" Vector__XXX
   SG_ Jystck6GrpYAxsLvrFrwrdPstvPsStts : 20|2@1+ (1,0) [0|3] "" Vector__XXX
   SG_ Jystck6GrpYAxsLvrBckNgtvPsSttus : 18|2@1+ (1,0) [0|3] "" Vector__XXX
   SG_ Jystck6GrpYAxisNeutralPosStatus : 16|2@1+ (1,0) [0|3] "" Vector__XXX
   SG_ Joystick6GripXAxisPos : 6|10@1+ (0.1,0) [0|102] "%" Vector__XXX
   SG_ Jystck6GrpXAxsLvrRghtPstvPsStts : 4|2@1+ (1,0) [0|3] "" Vector__XXX
   SG_ Jystck6GrpXAxsLvrLftNgtvPsSttus : 2|2@1+ (1,0) [0|3] "" Vector__XXX
   SG_ Jystck6GrpXAxisNeutralPosStatus : 0|2@1+ (1,0) [0|3] "" Vector__XXX

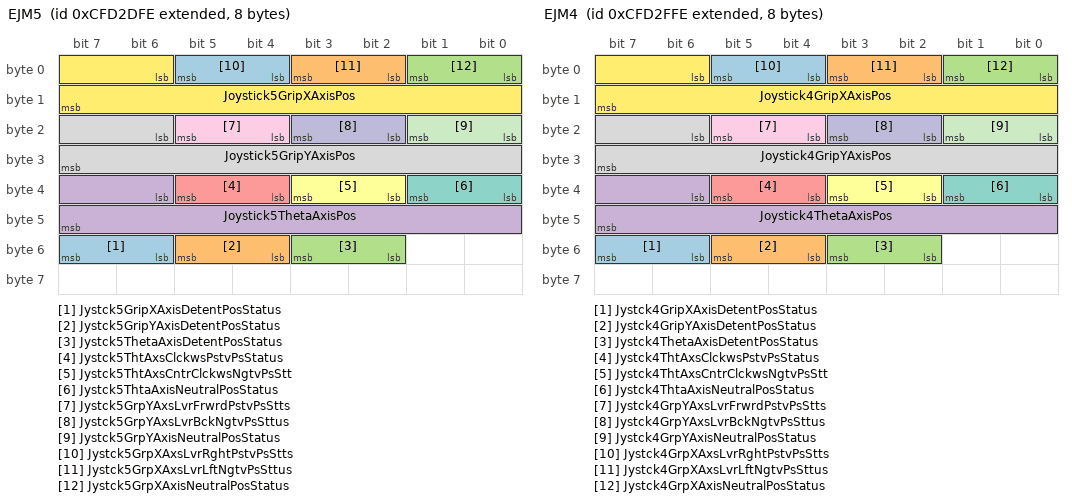
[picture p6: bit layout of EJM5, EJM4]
BO_ 2365402622 EJM5: 8 Vector__XXX
   SG_ Jystck5GripXAxisDetentPosStatus : 54|2@1+ (1,0) [0|3] "" Vector__XXX
   SG_ Jystck5GripYAxisDetentPosStatus : 52|2@1+ (1,0) [0|3] "" Vector__XXX
   SG_ Jystck5ThetaAxisDetentPosStatus : 50|2@1+ (1,0) [0|3] "" Vector__XXX
   SG_ Joystick5ThetaAxisPos : 38|10@1+ (0.1,0) [0|102] "%" Vector__XXX
   SG_ Jystck5ThtAxsClckwsPstvPsStatus : 36|2@1+ (1,0) [0|3] "" Vector__XXX
   SG_ Jystck5ThtAxsCntrClckwsNgtvPsStt : 34|2@1+ (1,0) [0|3] "" Vector__XXX
   SG_ Jystck5ThtaAxisNeutralPosStatus : 32|2@1+ (1,0) [0|3] "" Vector__XXX
   SG_ Joystick5GripYAxisPos : 22|10@1+ (0.1,0) [0|102] "%" Vector__XXX
   SG_ Jystck5GrpYAxsLvrFrwrdPstvPsStts : 20|2@1+ (1,0) [0|3] "" Vector__XXX
   SG_ Jystck5GrpYAxsLvrBckNgtvPsSttus : 18|2@1+ (1,0) [0|3] "" Vector__XXX
   SG_ Jystck5GrpYAxisNeutralPosStatus : 16|2@1+ (1,0) [0|3] "" Vector__XXX
   SG_ Joystick5GripXAxisPos : 6|10@1+ (0.1,0) [0|102] "%" Vector__XXX
   SG_ Jystck5GrpXAxsLvrRghtPstvPsStts : 4|2@1+ (1,0) [0|3] "" Vector__XXX
   SG_ Jystck5GrpXAxsLvrLftNgtvPsSttus : 2|2@1+ (1,0) [0|3] "" Vector__XXX
   SG_ Jystck5GrpXAxisNeutralPosStatus : 0|2@1+ (1,0) [0|3] "" Vector__XXX

BO_ 2365403134 EJM4: 8 Vector__XXX
   SG_ Jystck4GripXAxisDetentPosStatus : 54|2@1+ (1,0) [0|3] "" Vector__XXX
   SG_ Jystck4GripYAxisDetentPosStatus : 52|2@1+ (1,0) [0|3] "" Vector__XXX
   SG_ Jystck4ThetaAxisDetentPosStatus : 50|2@1+ (1,0) [0|3] "" Vector__XXX
   SG_ Joystick4ThetaAxisPos : 38|10@1+ (0.1,0) [0|102] "%" Vector__XXX
   SG_ Jystck4ThtAxsClckwsPstvPsStatus : 36|2@1+ (1,0) [0|3] "" Vector__XXX
   SG_ Jystck4ThtAxsCntrClckwsNgtvPsStt : 34|2@1+ (1,0) [0|3] "" Vector__XXX
   SG_ Jystck4ThtaAxisNeutralPosStatus : 32|2@1+ (1,0) [0|3] "" Vector__XXX
   SG_ Joystick4GripYAxisPos : 22|10@1+ (0.1,0) [0|102] "%" Vector__XXX
   SG_ Jystck4GrpYAxsLvrFrwrdPstvPsStts : 20|2@1+ (1,0) [0|3] "" Vector__XXX
   SG_ Jystck4GrpYAxsLvrBckNgtvPsSttus : 18|2@1+ (1,0) [0|3] "" Vector__XXX
   SG_ Jystck4GrpYAxisNeutralPosStatus : 16|2@1+ (1,0) [0|3] "" Vector__XXX
   SG_ Joystick4GripXAxisPos : 6|10@1+ (0.1,0) [0|102] "%" Vector__XXX
   SG_ Jystck4GrpXAxsLvrRghtPstvPsStts : 4|2@1+ (1,0) [0|3] "" Vector__XXX
   SG_ Jystck4GrpXAxsLvrLftNgtvPsSttus : 2|2@1+ (1,0) [0|3] "" Vector__XXX
   SG_ Jystck4GrpXAxisNeutralPosStatus : 0|2@1+ (1,0) [0|3] "" Vector__XXX

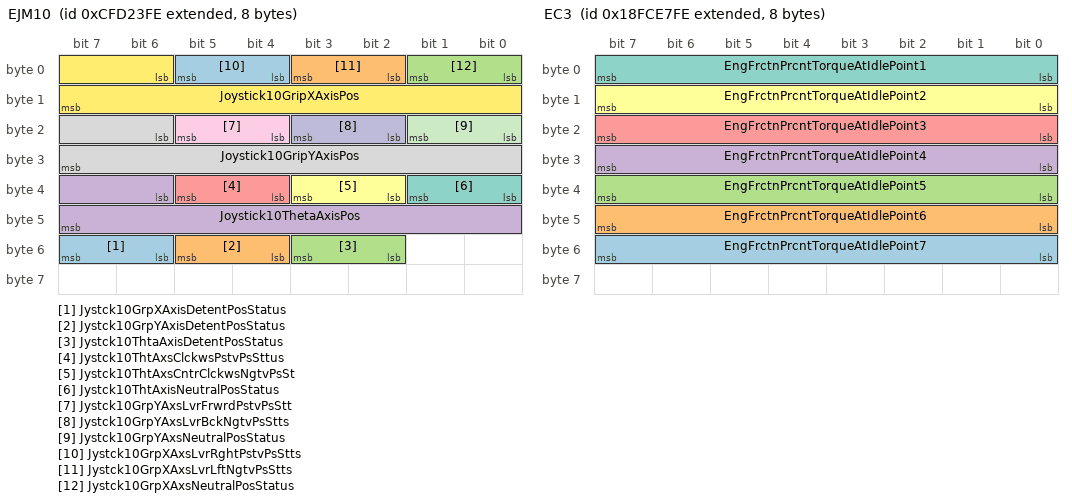
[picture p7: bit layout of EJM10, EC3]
BO_ 2365400062 EJM10: 8 Vector__XXX
   SG_ Jystck10GrpXAxisDetentPosStatus : 54|2@1+ (1,0) [0|3] "" Vector__XXX
   SG_ Jystck10GrpYAxisDetentPosStatus : 52|2@1+ (1,0) [0|3] "" Vector__XXX
   SG_ Jystck10ThtaAxisDetentPosStatus : 50|2@1+ (1,0) [0|3] "" Vector__XXX
   SG_ Joystick10ThetaAxisPos : 38|10@1+ (0.1,0) [0|102] "%" Vector__XXX
   SG_ Jystck10ThtAxsClckwsPstvPsSttus : 36|2@1+ (1,0) [0|3] "" Vector__XXX
   SG_ Jystck10ThtAxsCntrClckwsNgtvPsSt : 34|2@1+ (1,0) [0|3] "" Vector__XXX
   SG_ Jystck10ThtAxisNeutralPosStatus : 32|2@1+ (1,0) [0|3] "" Vector__XXX
   SG_ Joystick10GripYAxisPos : 22|10@1+ (0.1,0) [0|102] "%" Vector__XXX
   SG_ Jystck10GrpYAxsLvrFrwrdPstvPsStt : 20|2@1+ (1,0) [0|3] "" Vector__XXX
   SG_ Jystck10GrpYAxsLvrBckNgtvPsStts : 18|2@1+ (1,0) [0|3] "" Vector__XXX
   SG_ Jystck10GrpYAxsNeutralPosStatus : 16|2@1+ (1,0) [0|3] "" Vector__XXX
   SG_ Joystick10GripXAxisPos : 6|10@1+ (0.1,0) [0|102] "%" Vector__XXX
   SG_ Jystck10GrpXAxsLvrRghtPstvPsStts : 4|2@1+ (1,0) [0|3] "" Vector__XXX
   SG_ Jystck10GrpXAxsLvrLftNgtvPsStts : 2|2@1+ (1,0) [0|3] "" Vector__XXX
   SG_ Jystck10GrpXAxsNeutralPosStatus : 0|2@1+ (1,0) [0|3] "" Vector__XXX

BO_ 2566713598 EFS2: 8 Vector__XXX
   SG_ EngFuelFilterIntakeAbsPress : 0|8@1+ (2,0) [0|500] "kPa" Vector__XXX

BO_ 2499604478 EFL_P11: 8 Vector__XXX
   SG_ EngExhstGsRcrcltn1IntkeAbsPress : 0|16@1+ (0.1,0) [0|6425.5] "kPa" Vector__XXX

BO_ 2499608830 EFL_P10: 8 Vector__XXX
   SG_ EngExhstGsRcrcltn2IntkeAbsPress : 40|16@1+ (0.1,0) [0|6425.5] "kPa" Vector__XXX
   SG_ EngExhstGsRcrcltn2OtletAbsPress : 24|16@1+ (0.1,0) [0|6425.5] "kPa" Vector__XXX
   SG_ EngExhstGsRcrcltion2IntakePress : 16|8@1+ (2,0) [0|500] "kPa" Vector__XXX
   SG_ EngExhstGsRcrculation2DiffPress : 0|16@1+ (0.0078125,-250) [-250|251.99] "kPa" Vector__XXX

BO_ 2432499198 EEC9: 8 Vector__XXX
   SG_ CmdedEngFuelInjectionCtrlPress : 48|16@1+ (0.00390625,0) [0|251] "MPa" Vector__XXX
   SG_ CmdedEngFuelRailPress : 32|16@1+ (0.00390625,0) [0|251] "MPa" Vector__XXX
   SG_ EngExhstGsRcrculation2Valve2Pos : 16|16@1+ (0.0025,0) [0|160.637] "%" Vector__XXX
   SG_ EngExhstGsRcirculation2ValvePos : 0|16@1+ (0.0025,0) [0|160.637] "%" Vector__XXX

BO_ 2633825022 EEC11: 8 Vector__XXX
   SG_ EngExhstGsRcrclation2Valve2Ctrl : 16|16@1+ (0.0025,0) [0|160.637] "%" Vector__XXX
   SG_ EngExhstGsRcrculation2ValveCtrl : 0|16@1+ (0.0025,0) [0|160.637] "%" Vector__XXX

BO_ 2633826046 EEC10: 8 Vector__XXX
   SG_ EGR2CoolerBypassActuatorPos : 40|8@1+ (0.4,0) [0|100] "%" Vector__XXX
   SG_ EngExhstGsRcrcltn2ClrEfficiency : 32|8@1+ (0.4,0) [0|100] "%" Vector__XXX
   SG_ EngExhstGsRcrcltn2ClrIntkGsAbsPr : 16|16@1+ (0.5,0) [0|32127.5] "kPa" Vector__XXX
   SG_ EngExhstGsRcrcltn2ClrIntakeTemp : 0|16@1+ (0.03125,-273) [-273|1734.97] "deg C" Vector__XXX

BO_ 2566711294 EC3: 8 Vector__XXX
   SG_ EngFrctnPrcntTorqueAtIdlePoint7 : 48|8@1+ (1,-125) [-125|125] "%" Vector__XXX
   SG_ EngFrctnPrcntTorqueAtIdlePoint6 : 40|8@1+ (1,-125) [-125|125] "%" Vector__XXX
   SG_ EngFrctnPrcntTorqueAtIdlePoint5 : 32|8@1+ (1,-125) [-125|125] "%" Vector__XXX
   SG_ EngFrctnPrcntTorqueAtIdlePoint4 : 24|8@1+ (1,-125) [-125|125] "%" Vector__XXX
   SG_ EngFrctnPrcntTorqueAtIdlePoint3 : 16|8@1+ (1,-125) [-125|125] "%" Vector__XXX
   SG_ EngFrctnPrcntTorqueAtIdlePoint2 : 8|8@1+ (1,-125) [-125|125] "%" Vector__XXX
   SG_ EngFrctnPrcntTorqueAtIdlePoint1 : 0|8@1+ (1,-125) [-125|125] "%" Vector__XXX

BO_ 2566749438 DPFC1: 8 Vector__XXX
   SG_ DslPrtcltFltrActvRgnrtnFrcdStts : 53|3@1+ (1,0) [0|7] "" Vector__XXX
   SG_ ExhaustSystemHighTempLampCmd : 50|3@1+ (1,0) [0|7] "" Vector__XXX
   SG_ DslPrtcltFltrAtmtcActvRgnrtnIntt : 48|2@1+ (1,0) [0|3] "" Vector__XXX
   SG_ DslPrtcltFltrActvRgnrtnInhbtdDTV : 46|2@1+ (1,0) [0|3] "" Vector__XXX
   SG_ DslPrtcltFltrActvRgnrtnInhbtdDTE : 44|2@1+ (1,0) [0|3] "" Vector__XXX
   SG_ DslPrtcltFltrActvRgnrtnInhbtdDTP : 42|2@1+ (1,0) [0|3] "" Vector__XXX
   SG_ DslPrtcltFltrActvRgnrtnInhbtdDTT : 40|2@1+ (1,0) [0|3] "" Vector__XXX
   SG_ DslPrtcltFltrActvRgnrtnInhbtdDTS : 38|2@1+ (1,0) [0|3] "" Vector__XXX
   SG_ DslPrtcltFltrActvRgnrtnInhb_0000 : 36|2@1+ (1,0) [0|3] "" Vector__XXX
   SG_ DslPrtcltFltrActvRgnrtnInhbtdDTL : 34|2@1+ (1,0) [0|3] "" Vector__XXX
   SG_ DslPrtcltFltrActvRgnrtnInhb_0001 : 32|2@1+ (1,0) [0|3] "" Vector__XXX
   SG_ DslPrtcltFltrActvRgnrtnInhb_0002 : 30|2@1+ (1,0) [0|3] "" Vector__XXX
   SG_ DslPrtcltFltrActvRgnrtnInhbtdDTO : 28|2@1+ (1,0) [0|3] "" Vector__XXX
   SG_ DslPrtcltFltrActvRgnrtnInhbtdDTA : 26|2@1+ (1,0) [0|3] "" Vector__XXX
   SG_ DslPrtcltFltrActvRgnrtnInhb_0003 : 24|2@1+ (1,0) [0|3] "" Vector__XXX
   SG_ DslPrtcltFltrActvRgnrtnInhb_0004 : 22|2@1+ (1,0) [0|3] "" Vector__XXX
   SG_ DslPrtcltFltrActvRgnrtnInhbtdDTC : 20|2@1+ (1,0) [0|3] "" Vector__XXX
   SG_ DslPrtcltFltrActvRgnrtnInhbtdDTI : 18|2@1+ (1,0) [0|3] "" Vector__XXX
   SG_ DslPrtcltFltrActvRgnrtnInhbtdStt : 16|2@1+ (1,0) [0|3] "" Vector__XXX
   SG_ DieselParticulateFilterStatus : 12|3@1+ (1,0) [0|7] "" Vector__XXX
   SG_ DslPrtcltFltrActvRgnrtionStatus : 10|2@1+ (1,0) [0|3] "" Vector__XXX
   SG_ DslPrtcltFltrPssvRgnrtionStatus : 8|2@1+ (1,0) [0|3] "" Vector__XXX
   SG_ DieselParticulateFilterLampCmd : 0|3@1+ (1,0) [0|7] "" Vector__XXX

BO_ 2566715646 DPF2S2: 8 Vector__XXX
   SG_ DslPrtclateFilter2SootSignalMin : 32|16@1+ (0.0025,0) [0|160.637] "%" Vector__XXX
   SG_ DslPrtclateFilter2SootSignalMax : 16|16@1+ (0.0025,0) [0|160.637] "%" Vector__XXX
   SG_ DslPrtcltFltr2StSgnlStndrdDvton : 0|16@1+ (0.0025,0) [0|160.637] "%" Vector__XXX

BO_ 2566724606 DPF2S: 8 Vector__XXX
   SG_ DslPrtcltFltr2StSnsrPrlmnaryFMI : 48|5@1+ (1,0) [0|31] "" Vector__XXX
   SG_ DslPrtcltFlter2MedianSootSignal : 32|16@1+ (0.0025,0) [0|160.637] "%" Vector__XXX
   SG_ DslPrtclteFilter2MeanSootSignal : 16|16@1+ (0.0025,0) [0|160.637] "%" Vector__XXX
   SG_ DslPrticulateFilter2SootDensity : 8|8@1+ (0.08,0) [0|20] "g/L" Vector__XXX
   SG_ DeselParticulateFilter2SootMass : 0|8@1+ (4,0) [0|1000] "g" Vector__XXX

BO_ 2566715902 DPF1S2: 8 Vector__XXX
   SG_ DslPrtclateFilter1SootSignalMin : 32|16@1+ (0.0025,0) [0|160.637] "%" Vector__XXX
   SG_ DslPrtclateFilter1SootSignalMax : 16|16@1+ (0.0025,0) [0|160.637] "%" Vector__XXX
   SG_ DslPrtcltFltr1StSgnlStndrdDvton : 0|16@1+ (0.0025,0) [0|160.637] "%" Vector__XXX

BO_ 2566724862 DPF1S: 8 Vector__XXX
   SG_ DslPrtcltFltr1StSnsrPrlmnaryFMI : 48|5@1+ (1,0) [0|31] "" Vector__XXX
   SG_ DslPrtcltFlter1MedianSootSignal : 32|16@1+ (0.0025,0) [0|160.637] "%" Vector__XXX
   SG_ DslPrtclteFilter1MeanSootSignal : 16|16@1+ (0.0025,0) [0|160.637] "%" Vector__XXX
   SG_ DslPrticulateFilter1SootDensity : 8|8@1+ (0.08,0) [0|20] "g/L" Vector__XXX
   SG_ DeselParticulateFilter1SootMass : 0|8@1+ (4,0) [0|1000] "g" Vector__XXX

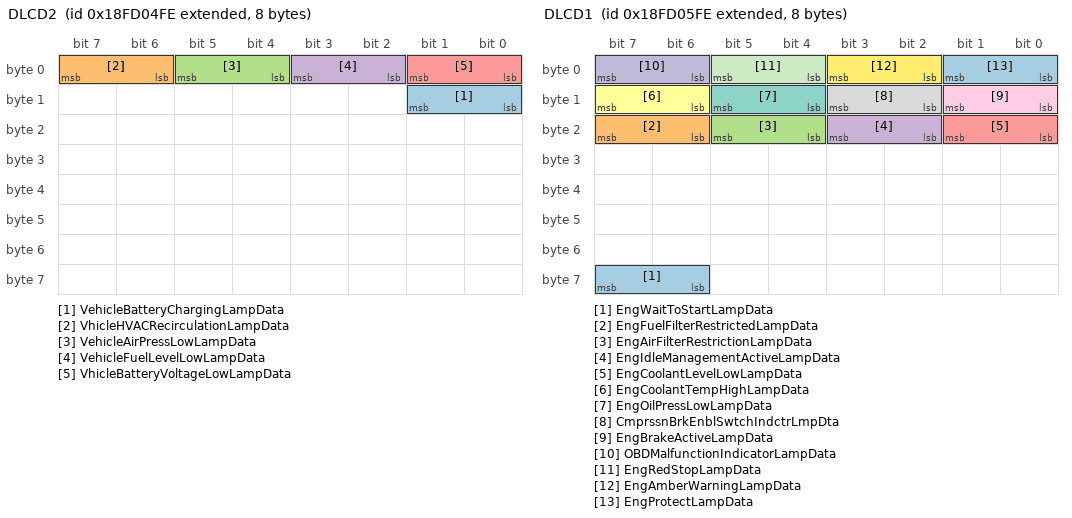
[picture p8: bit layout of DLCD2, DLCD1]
BO_ 2566718718 DLCD2: 8 Vector__XXX
   SG_ VehicleBatteryChargingLampData : 8|2@1+ (1,0) [0|3] "" Vector__XXX
   SG_ VhicleHVACRecirculationLampData : 6|2@1+ (1,0) [0|3] "" Vector__XXX
   SG_ VehicleAirPressLowLampData : 4|2@1+ (1,0) [0|3] "" Vector__XXX
   SG_ VehicleFuelLevelLowLampData : 2|2@1+ (1,0) [0|3] "" Vector__XXX
   SG_ VhicleBatteryVoltageLowLampData : 0|2@1+ (1,0) [0|3] "" Vector__XXX

BO_ 2566718974 DLCD1: 8 Vector__XXX
   SG_ EngWaitToStartLampData : 62|2@1+ (1,0) [0|3] "" Vector__XXX
   SG_ EngFuelFilterRestrictedLampData : 22|2@1+ (1,0) [0|3] "" Vector__XXX
   SG_ EngAirFilterRestrictionLampData : 20|2@1+ (1,0) [0|3] "" Vector__XXX
   SG_ EngIdleManagementActiveLampData : 18|2@1+ (1,0) [0|3] "" Vector__XXX
   SG_ EngCoolantLevelLowLampData : 16|2@1+ (1,0) [0|3] "" Vector__XXX
   SG_ EngCoolantTempHighLampData : 14|2@1+ (1,0) [0|3] "" Vector__XXX
   SG_ EngOilPressLowLampData : 12|2@1+ (1,0) [0|3] "" Vector__XXX
   SG_ CmprssnBrkEnblSwtchIndctrLmpDta : 10|2@1+ (1,0) [0|3] "" Vector__XXX
   SG_ EngBrakeActiveLampData : 8|2@1+ (1,0) [0|3] "" Vector__XXX
   SG_ OBDMalfunctionIndicatorLampData : 6|2@1+ (1,0) [0|3] "" Vector__XXX
   SG_ EngRedStopLampData : 4|2@1+ (1,0) [0|3] "" Vector__XXX
   SG_ EngAmberWarningLampData : 2|2@1+ (1,0) [0|3] "" Vector__XXX
   SG_ EngProtectLampData : 0|2@1+ (1,0) [0|3] "" Vector__XXX

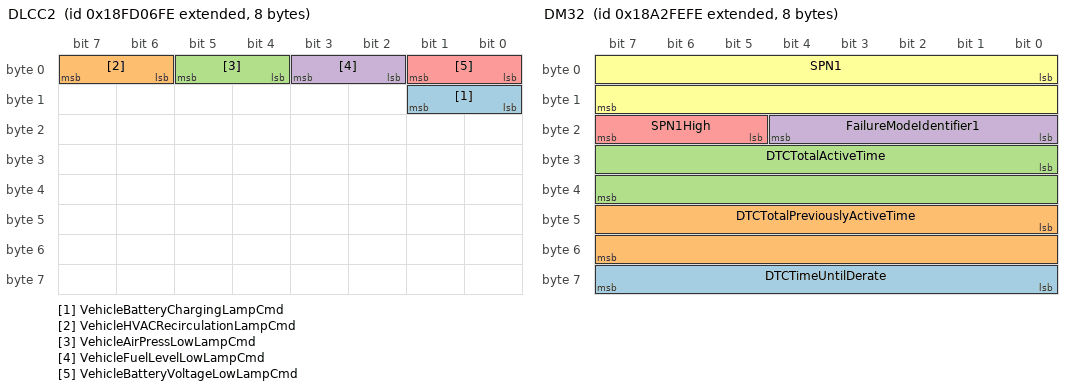
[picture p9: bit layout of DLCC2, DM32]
BO_ 2566719230 DLCC2: 8 Vector__XXX
   SG_ VehicleBatteryChargingLampCmd : 8|2@1+ (1,0) [0|3] "" Vector__XXX
   SG_ VehicleHVACRecirculationLampCmd : 6|2@1+ (1,0) [0|3] "" Vector__XXX
   SG_ VehicleAirPressLowLampCmd : 4|2@1+ (1,0) [0|3] "" Vector__XXX
   SG_ VehicleFuelLevelLowLampCmd : 2|2@1+ (1,0) [0|3] "" Vector__XXX
   SG_ VehicleBatteryVoltageLowLampCmd : 0|2@1+ (1,0) [0|3] "" Vector__XXX

BO_ 2560818942 DM32: 8 Vector__XXX
   SG_ DTCTimeUntilDerate : 56|8@1+ (0.25,0) [0|62.5] "hr" Vector__XXX
   SG_ DTCTotalPreviouslyActiveTime : 40|16@1+ (0.2,0) [0|12851] "hr" Vector__XXX
   SG_ DTCTotalActiveTime : 24|16@1+ (0.2,0) [0|12851] "hr" Vector__XXX
   SG_ FailureModeIdentifier1 : 16|5@1+ (1,0) [0|0] "" Vector__XXX
   SG_ SPN1High : 21|3@1+ (1,0) [0|7] "" Vector__XXX
   SG_ SPN1 : 0|16@1+ (1,0) [0|65536] "" Vector__XXX

BO_ 2561212158 DISP1: 8 Vector__XXX
   SG_ TextDisplayIndex : 16|8@1+ (1,0) [0|250] "" Vector__XXX
   SG_ TextDisplayInstructions : 0|4@1+ (1,0) [0|15] "" Vector__XXX

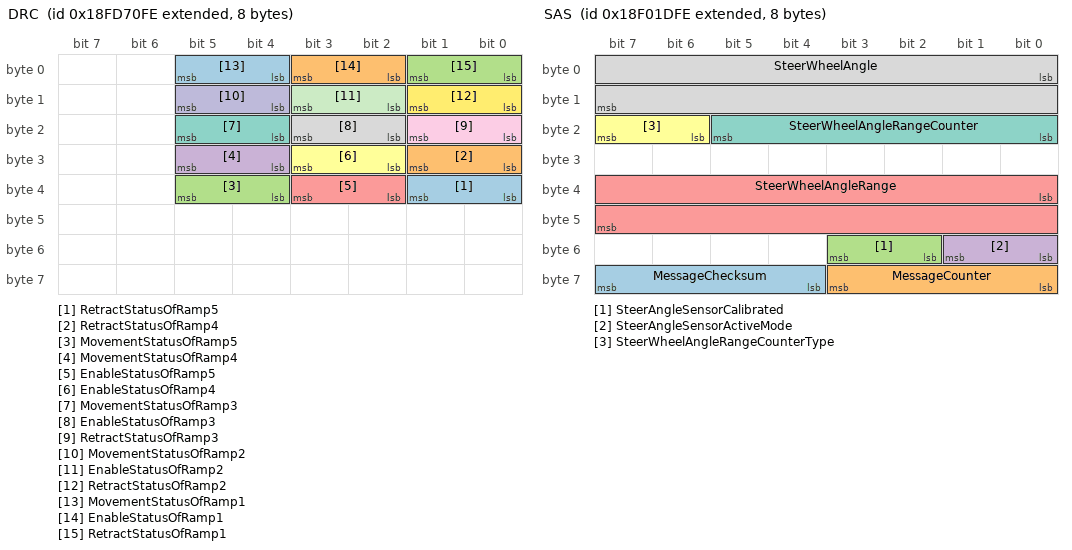
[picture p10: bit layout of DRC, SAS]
BO_ 2566746366 DRC: 8 Vector__XXX
   SG_ RetractStatusOfRamp5 : 32|2@1+ (1,0) [0|3] "" Vector__XXX
   SG_ RetractStatusOfRamp4 : 24|2@1+ (1,0) [0|3] "" Vector__XXX
   SG_ MovementStatusOfRamp5 : 36|2@1+ (1,0) [0|3] "" Vector__XXX
   SG_ MovementStatusOfRamp4 : 28|2@1+ (1,0) [0|3] "" Vector__XXX
   SG_ EnableStatusOfRamp5 : 34|2@1+ (1,0) [0|3] "" Vector__XXX
   SG_ EnableStatusOfRamp4 : 26|2@1+ (1,0) [0|3] "" Vector__XXX
   SG_ MovementStatusOfRamp3 : 20|2@1+ (1,0) [0|3] "" Vector__XXX
   SG_ EnableStatusOfRamp3 : 18|2@1+ (1,0) [0|3] "" Vector__XXX
   SG_ RetractStatusOfRamp3 : 16|2@1+ (1,0) [0|3] "" Vector__XXX
   SG_ MovementStatusOfRamp2 : 12|2@1+ (1,0) [0|3] "" Vector__XXX
   SG_ EnableStatusOfRamp2 : 10|2@1+ (1,0) [0|3] "" Vector__XXX
   SG_ RetractStatusOfRamp2 : 8|2@1+ (1,0) [0|3] "" Vector__XXX
   SG_ MovementStatusOfRamp1 : 4|2@1+ (1,0) [0|3] "" Vector__XXX
   SG_ EnableStatusOfRamp1 : 2|2@1+ (1,0) [0|3] "" Vector__XXX
   SG_ RetractStatusOfRamp1 : 0|2@1+ (1,0) [0|3] "" Vector__XXX

BO_ 2566750206 EC2: 8 Vector__XXX
   SG_ MaxCrankAttemptsPerStartAttempt : 0|8@1+ (1,0) [0|250] "" Vector__XXX

BO_ 2566755582 EEC7: 8 Vector__XXX
   SG_ EngExhstGsRcrculation1Valve2Pos : 16|16@1+ (0.0025,0) [0|160.637] "%" Vector__XXX
   SG_ EngExhstGsRcirculation1ValvePos : 0|16@1+ (0.0025,0) [0|160.637] "%" Vector__XXX
   SG_ EngCrnkcsBrthrOilSeparatorSpeed : 32|16@1+ (1,0) [0|64255] "rpm" Vector__XXX
   SG_ CmdedEngIntakeManifoldPress : 48|16@1+ (0.125,0) [0|8031.88] "kPa" Vector__XXX

BO_ 2566746110 EEC8: 8 Vector__XXX
   SG_ EngExhstGsRcrcltn1ClrIntkGsAbsPr : 32|16@1+ (0.5,0) [0|32127.5] "kPa" Vector__XXX
   SG_ EngExhstGsRcrcltn1ClrIntakeTemp : 16|16@1+ (0.03125,-273) [-273|1734.97] "deg C" Vector__XXX
   SG_ EngExhstGsRcrcltn1ClrEfficiency : 48|8@1+ (0.4,0) [0|100] "%" Vector__XXX
   SG_ EngExhstGsRcrclation1Valve2Ctrl : 0|16@1+ (0.0025,0) [0|160.637] "%" Vector__XXX

BO_ 2566752510 EFL_P5: 8 Vector__XXX
   SG_ EngIntkVlvActtonOilPressForCyl4 : 48|16@1+ (0.1,0) [0|6425.5] "kPa" Vector__XXX
   SG_ EngIntkVlvActtonOilPressForCyl3 : 32|16@1+ (0.1,0) [0|6425.5] "kPa" Vector__XXX
   SG_ EngIntkVlvActtonOilPressForCyl2 : 16|16@1+ (0.1,0) [0|6425.5] "kPa" Vector__XXX
   SG_ EngIntkVlvActtonOilPressForCyl1 : 0|16@1+ (0.1,0) [0|6425.5] "kPa" Vector__XXX

BO_ 2566752254 EFL_P6: 8 Vector__XXX
   SG_ EngIntkVlvActtonOilPressForCyl8 : 48|16@1+ (0.1,0) [0|6425.5] "kPa" Vector__XXX
   SG_ EngIntkVlvActtonOilPressForCyl7 : 32|16@1+ (0.1,0) [0|6425.5] "kPa" Vector__XXX
   SG_ EngIntkVlvActtonOilPressForCyl6 : 16|16@1+ (0.1,0) [0|6425.5] "kPa" Vector__XXX
   SG_ EngIntkVlvActtonOilPressForCyl5 : 0|16@1+ (0.1,0) [0|6425.5] "kPa" Vector__XXX

BO_ 2566751998 EFL_P7: 8 Vector__XXX
   SG_ EngIntkVlvActtnOilPressForCyl12 : 48|16@1+ (0.1,0) [0|6425.5] "kPa" Vector__XXX
   SG_ EngIntkVlvActtnOilPressForCyl11 : 32|16@1+ (0.1,0) [0|6425.5] "kPa" Vector__XXX
   SG_ EngIntkVlvActtnOilPressForCyl10 : 16|16@1+ (0.1,0) [0|6425.5] "kPa" Vector__XXX
   SG_ EngIntkVlvActtonOilPressForCyl9 : 0|16@1+ (0.1,0) [0|6425.5] "kPa" Vector__XXX

BO_ 2566751742 EFL_P8: 8 Vector__XXX
   SG_ EngIntkVlvActtnOilPressForCyl16 : 48|16@1+ (0.1,0) [0|6425.5] "kPa" Vector__XXX
   SG_ EngIntkVlvActtnOilPressForCyl15 : 32|16@1+ (0.1,0) [0|6425.5] "kPa" Vector__XXX
   SG_ EngIntkVlvActtnOilPressForCyl14 : 16|16@1+ (0.1,0) [0|6425.5] "kPa" Vector__XXX
   SG_ EngIntkVlvActtnOilPressForCyl13 : 0|16@1+ (0.1,0) [0|6425.5] "kPa" Vector__XXX

BO_ 2566751486 EFL_P9: 8 Vector__XXX
   SG_ EngIntkVlvActtnOilPressForCyl20 : 48|16@1+ (0.1,0) [0|6425.5] "kPa" Vector__XXX
   SG_ EngIntkVlvActtnOilPressForCyl19 : 32|16@1+ (0.1,0) [0|6425.5] "kPa" Vector__XXX
   SG_ EngIntkVlvActtnOilPressForCyl18 : 16|16@1+ (0.1,0) [0|6425.5] "kPa" Vector__XXX
   SG_ EngIntkVlvActtnOilPressForCyl17 : 0|16@1+ (0.1,0) [0|6425.5] "kPa" Vector__XXX

BO_ 2499641854 EGRBV: 8 Vector__XXX
   SG_ EGR1CoolerBypassActuatorPostion : 0|8@1+ (0.4,0) [0|100] "%" Vector__XXX

BO_ 2566748158 ESV1: 8 Vector__XXX
   SG_ EngSparkPlug4 : 48|16@1+ (1,0) [0|64255] "Volts" Vector__XXX
   SG_ EngSparkPlug3 : 32|16@1+ (1,0) [0|64255] "Volts" Vector__XXX
   SG_ EngSparkPlug2 : 16|16@1+ (1,0) [0|64255] "Volts" Vector__XXX
   SG_ EngSparkPlug1 : 0|16@1+ (1,0) [0|64255] "Volts" Vector__XXX

BO_ 2566747902 ESV2: 8 Vector__XXX
   SG_ EngSparkPlug8 : 48|16@1+ (1,0) [0|64255] "Volts" Vector__XXX
   SG_ EngSparkPlug7 : 32|16@1+ (1,0) [0|64255] "Volts" Vector__XXX
   SG_ EngSparkPlug6 : 16|16@1+ (1,0) [0|64255] "Volts" Vector__XXX
   SG_ EngSparkPlug5 : 0|16@1+ (1,0) [0|64255] "Volts" Vector__XXX

BO_ 2566747646 ESV3: 8 Vector__XXX
   SG_ EngSparkPlug12 : 48|16@1+ (1,0) [0|64255] "Volts" Vector__XXX
   SG_ EngSparkPlug11 : 32|16@1+ (1,0) [0|64255] "Volts" Vector__XXX
   SG_ EngSparkPlug10 : 16|16@1+ (1,0) [0|64255] "Volts" Vector__XXX
   SG_ EngSparkPlug9 : 0|16@1+ (1,0) [0|64255] "Volts" Vector__XXX

BO_ 2566747390 ESV4: 8 Vector__XXX
   SG_ EngSparkPlug16 : 48|16@1+ (1,0) [0|64255] "Volts" Vector__XXX
   SG_ EngSparkPlug15 : 32|16@1+ (1,0) [0|64255] "Volts" Vector__XXX
   SG_ EngSparkPlug14 : 16|16@1+ (1,0) [0|64255] "Volts" Vector__XXX
   SG_ EngSparkPlug13 : 0|16@1+ (1,0) [0|64255] "Volts" Vector__XXX

BO_ 2566747134 ESV5: 8 Vector__XXX
   SG_ EngSparkPlug20 : 48|16@1+ (1,0) [0|64255] "Volts" Vector__XXX
   SG_ EngSparkPlug19 : 32|16@1+ (1,0) [0|64255] "Volts" Vector__XXX
   SG_ EngSparkPlug18 : 16|16@1+ (1,0) [0|64255] "Volts" Vector__XXX
   SG_ EngSparkPlug17 : 0|16@1+ (1,0) [0|64255] "Volts" Vector__XXX

BO_ 2566746878 ESV6: 8 Vector__XXX
   SG_ EngSparkPlug24 : 48|16@1+ (1,0) [0|64255] "Volts" Vector__XXX
   SG_ EngSparkPlug23 : 32|16@1+ (1,0) [0|64255] "Volts" Vector__XXX
   SG_ EngSparkPlug22 : 16|16@1+ (1,0) [0|64255] "Volts" Vector__XXX
   SG_ EngSparkPlug21 : 0|16@1+ (1,0) [0|64255] "Volts" Vector__XXX

BO_ 2561277694 FLIC: 8 Vector__XXX
   SG_ LaneDepartureWarningEnableCmd : 0|2@1+ (1,0) [0|3] "" Vector__XXX

BO_ 2633861886 J2012: 8 Vector__XXX
   SG_ J2012DTCOccurrenceCount : 49|7@1+ (1,0) [0|127] "" Vector__XXX
   SG_ J2012DTCStatus : 48|1@1+ (1,0) [0|1] "" Vector__XXX
   SG_ NumberOfJ2012DTCs : 0|8@1+ (1,0) [0|250] "" Vector__XXX

BO_ 2565873150 SAS: 8 Vector__XXX
   SG_ MessageChecksum : 60|4@1+ (1,0) [0|15] "" Vector__XXX
   SG_ MessageCounter : 56|4@1+ (1,0) [0|15] "" Vector__XXX
   SG_ SteerAngleSensorCalibrated : 50|2@1+ (1,0) [0|3] "" Vector__XXX
   SG_ SteerAngleSensorActiveMode : 48|2@1+ (1,0) [0|3] "" Vector__XXX
   SG_ SteerWheelAngleRange : 32|16@1+ (0.000976563,-31.374) [-31.374|31.374] "rad" Vector__XXX
   SG_ SteerWheelAngleRangeCounterType : 22|2@1+ (1,0) [0|3] "" Vector__XXX
   SG_ SteerWheelAngleRangeCounter : 16|6@1+ (1,-32) [-32|29] "ranges" Vector__XXX
   SG_ SteerWheelAngle : 0|16@1+ (0.000976563,-31.374) [-31.374|31.374] "rad" Vector__XXX

BO_ 2566745854 SCR1: 8 Vector__XXX
   SG_ Aftrtrtmnt1SCRCtlystCnvrsnEffcnc : 32|8@1+ (0.4,0) [0|100] "%" Vector__XXX
   SG_ Aftrtrtmnt1SCRCmddCtlystRgntCnsm : 16|16@1+ (0.05,0) [0|3212.75] "L/h" Vector__XXX
   SG_ Aftrtrtmnt1SCRAvrgCtlystRgntCnsm : 0|16@1+ (0.05,0) [0|3212.75] "L/h" Vector__XXX
   SG_ Aftrtrtmnt1DslExhstFldTnkLwLvlIn : 40|16@1+ (1,0) [0|64255] "km" Vector__XXX

BO_ 2566751230 TCI: 8 Vector__XXX
   SG_ TransferCaseStatus : 0|3@1+ (1,0) [0|7] "" Vector__XXX

BO_ 2566755838 TRF2: 8 Vector__XXX
   SG_ TrnsTrqueConverterOilOutletTemp : 8|16@1+ (0.03125,-273) [-273|1734.97] "deg C" Vector__XXX
   SG_ TransOverheatIndicator : 4|2@1+ (1,0) [0|3] "" Vector__XXX
   SG_ TransOilLifeRemaining : 24|8@1+ (0.4,0) [0|100] "%" Vector__XXX
   SG_ TransOilLevelSwitch : 2|2@1+ (1,0) [0|3] "" Vector__XXX
   SG_ TransOilFilterRestrictionSwitch : 0|2@1+ (1,0) [0|3] "" Vector__XXX

BO_ 2566752766 VDS2: 8 Vector__XXX
   SG_ VehicleRoll : 0|16@1+ (0.0078125,-200) [-200|301.99] "deg" Vector__XXX

BO_ 2633938942 LF: 10 Vector__XXX
   SG_ TotalEngCruiseTime : 48|32@1+ (0.05,0) [0|2.10554e+08] "hr" Vector__XXX
   SG_ TotalDriveAverageLoadFactor : 40|8@1+ (0.4,0) [0|100] "%" Vector__XXX
   SG_ TripDriveAverageLoadFactor : 32|8@1+ (0.4,0) [0|100] "%" Vector__XXX
   SG_ TripAverageEngSpeed : 16|16@1+ (0.125,0) [0|8031.88] "rpm" Vector__XXX
   SG_ TripMaxEngSpeed : 0|16@1+ (0.125,0) [0|8031.88] "rpm" Vector__XXX

BO_ 2566799614 LD: 8 Vector__XXX
   SG_ ImplementRearWorkLight : 62|2@1+ (1,0) [0|3] "" Vector__XXX
   SG_ ImplementLeftForwardWorkLight : 60|2@1+ (1,0) [0|3] "" Vector__XXX
   SG_ ImplementRightForwardWorkLight : 58|2@1+ (1,0) [0|3] "" Vector__XXX
   SG_ ImplementLeftFacingWorkLight : 54|2@1+ (1,0) [0|3] "" Vector__XXX
   SG_ ImplementRightFacingWorkLight : 52|2@1+ (1,0) [0|3] "" Vector__XXX
   SG_ ImplementOEMOption1Light : 50|2@1+ (1,0) [0|3] "" Vector__XXX
   SG_ ImplementOEMOption2Light : 48|2@1+ (1,0) [0|3] "" Vector__XXX
   SG_ TrctrFrontHighMountedWorkLights : 46|2@1+ (1,0) [0|3] "" Vector__XXX
   SG_ TrctorFrontLowMountedWorkLights : 44|2@1+ (1,0) [0|3] "" Vector__XXX
   SG_ TrctorSideHighMountedWorkLights : 42|2@1+ (1,0) [0|3] "" Vector__XXX
   SG_ TractorSideLowMountedWorkLights : 40|2@1+ (1,0) [0|3] "" Vector__XXX
   SG_ TrctorRearHighMountedWorkLights : 38|2@1+ (1,0) [0|3] "" Vector__XXX
   SG_ TractorRearLowMountedWorkLights : 36|2@1+ (1,0) [0|3] "" Vector__XXX
   SG_ TrctrUndersideMountedWorkLights : 34|2@1+ (1,0) [0|3] "" Vector__XXX
   SG_ RearFogLights : 32|2@1+ (1,0) [0|3] "" Vector__XXX
   SG_ TractorMarkerLight : 30|2@1+ (1,0) [0|3] "" Vector__XXX
   SG_ ImplementMarkerLight : 28|2@1+ (1,0) [0|3] "" Vector__XXX
   SG_ TractorClearanceLight : 26|2@1+ (1,0) [0|3] "" Vector__XXX
   SG_ ImplementClearanceLight : 24|2@1+ (1,0) [0|3] "" Vector__XXX
   SG_ LeftStopLight : 22|2@1+ (1,0) [0|3] "" Vector__XXX
   SG_ RightStopLight : 20|2@1+ (1,0) [0|3] "" Vector__XXX
   SG_ CenterStopLight : 18|2@1+ (1,0) [0|3] "" Vector__XXX
   SG_ BackUpLightAndAlarmHorn : 16|2@1+ (1,0) [0|3] "" Vector__XXX
   SG_ LeftTurnSignalLights : 14|2@1+ (1,0) [0|3] "" Vector__XXX
   SG_ RightTurnSignalLights : 12|2@1+ (1,0) [0|3] "" Vector__XXX
   SG_ RotatingBeaconLight : 10|2@1+ (1,0) [0|3] "" Vector__XXX
   SG_ TractorFrontFogLights : 8|2@1+ (1,0) [0|3] "" Vector__XXX
   SG_ HighBeamHeadLightData : 6|2@1+ (1,0) [0|3] "" Vector__XXX
   SG_ LowBeamHeadLightData : 4|2@1+ (1,0) [0|3] "" Vector__XXX
   SG_ AltBeamHeadLightData : 2|2@1+ (1,0) [0|3] "" Vector__XXX
   SG_ RunningLight : 0|2@1+ (1,0) [0|3] "" Vector__XXX

BO_ 2365473278 LC: 8 Vector__XXX
   SG_ ImplementRearWorkLightCmd : 62|2@1+ (1,0) [0|3] "" Vector__XXX
   SG_ ImplmentLeftForwardWorkLightCmd : 60|2@1+ (1,0) [0|3] "" Vector__XXX
   SG_ ImplmntRightForwardWorkLightCmd : 58|2@1+ (1,0) [0|3] "" Vector__XXX
   SG_ LightingDataRqCmd : 56|2@1+ (1,0) [0|3] "" Vector__XXX
   SG_ ImplementLeftFacingWorkLightCmd : 54|2@1+ (1,0) [0|3] "" Vector__XXX
   SG_ ImplmentRightFacingWorkLightCmd : 52|2@1+ (1,0) [0|3] "" Vector__XXX
   SG_ ImplementOEMOption1LightCmd : 50|2@1+ (1,0) [0|3] "" Vector__XXX
   SG_ ImplementOEMOption2LightCmd : 48|2@1+ (1,0) [0|3] "" Vector__XXX
   SG_ TrctrFrntHghMuntedWorkLightsCmd : 46|2@1+ (1,0) [0|3] "" Vector__XXX
   SG_ TrctrFrntLwMountedWorkLightsCmd : 44|2@1+ (1,0) [0|3] "" Vector__XXX
   SG_ TrctrSdHighMountedWorkLightsCmd : 42|2@1+ (1,0) [0|3] "" Vector__XXX
   SG_ TrctrSdeLowMountedWorkLightsCmd : 40|2@1+ (1,0) [0|3] "" Vector__XXX
   SG_ TrctrRrHighMountedWorkLightsCmd : 38|2@1+ (1,0) [0|3] "" Vector__XXX
   SG_ TrctrRarLowMountedWorkLightsCmd : 36|2@1+ (1,0) [0|3] "" Vector__XXX
   SG_ TrctrUndrsdMountedWorkLightsCmd : 34|2@1+ (1,0) [0|3] "" Vector__XXX
   SG_ RearFogLightCmd : 32|2@1+ (1,0) [0|3] "" Vector__XXX
   SG_ TractorMarkerLightCmd : 30|2@1+ (1,0) [0|3] "" Vector__XXX
   SG_ ImplementMarkerLightCmd : 28|2@1+ (1,0) [0|3] "" Vector__XXX
   SG_ TractorClearanceLightCmd : 26|2@1+ (1,0) [0|3] "" Vector__XXX
   SG_ ImplementClearanceLightCmd : 24|2@1+ (1,0) [0|3] "" Vector__XXX
   SG_ LeftStopLightCmd : 22|2@1+ (1,0) [0|3] "" Vector__XXX
   SG_ RightStopLightCmd : 20|2@1+ (1,0) [0|3] "" Vector__XXX
   SG_ CenterStopLightCmd : 18|2@1+ (1,0) [0|3] "" Vector__XXX
   SG_ BackUpLightAndAlarmHornCmd : 16|2@1+ (1,0) [0|3] "" Vector__XXX
   SG_ LeftTurnSignalLightsCmd : 14|2@1+ (1,0) [0|3] "" Vector__XXX
   SG_ RightTurnSignalLightsCmd : 12|2@1+ (1,0) [0|3] "" Vector__XXX
   SG_ RotatingBeaconLightCmd : 10|2@1+ (1,0) [0|3] "" Vector__XXX
   SG_ TractorFrontFogLightsCmd : 8|2@1+ (1,0) [0|3] "" Vector__XXX
   SG_ HighBeamHeadLightCmd : 6|2@1+ (1,0) [0|3] "" Vector__XXX
   SG_ LowBeamHeadLightCmd : 4|2@1+ (1,0) [0|3] "" Vector__XXX
   SG_ AltBeamHeadLightCmd : 2|2@1+ (1,0) [0|3] "" Vector__XXX
   SG_ RunningLightCmd : 0|2@1+ (1,0) [0|3] "" Vector__XXX

BO_ 2365485822 LBC: 8 Vector__XXX
   SG_ BladeCtrlMode : 16|8@1+ (1,0) [0|255] "" Vector__XXX
   SG_ BladeDurationAndDirection : 0|16@1+ (0.1,-3276.8) [-3276.8|3148.7] "sec" Vector__XXX
   SG_ LandLevelingSystemEnableStatus : 32|2@1+ (1,0) [0|3] "" Vector__XXX
   SG_ BladeCtrlModeRight : 28|4@1+ (1,0) [0|15] "" Vector__XXX
   SG_ BladeCtrlModeLeft : 24|4@1+ (1,0) [0|15] "" Vector__XXX

BO_ 2633926654 IT6: 8 Vector__XXX
   SG_ EngActualIgntTiming : 48|16@1+ (0.0078125,-200) [-200|301.99] "deg" Vector__XXX
   SG_ EngDesiredIgntTiming3 : 32|16@1+ (0.0078125,-200) [-200|301.99] "deg" Vector__XXX
   SG_ EngDesiredIgntTiming2 : 16|16@1+ (0.0078125,-200) [-200|301.99] "deg" Vector__XXX
   SG_ EngDesiredIgntTiming1 : 0|16@1+ (0.0078125,-200) [-200|301.99] "deg" Vector__XXX

BO_ 2633926398 IT5: 8 Vector__XXX
   SG_ EngCyl20IgntTiming : 48|16@1+ (0.0078125,-200) [-200|301.99] "deg" Vector__XXX
   SG_ EngCyl19IgntTiming : 32|16@1+ (0.0078125,-200) [-200|301.99] "deg" Vector__XXX
   SG_ EngCyl18IgntTiming : 16|16@1+ (0.0078125,-200) [-200|301.99] "deg" Vector__XXX
   SG_ EngCyl17IgntTiming : 0|16@1+ (0.0078125,-200) [-200|301.99] "deg" Vector__XXX

BO_ 2633926142 IT4: 8 Vector__XXX
   SG_ EngCyl16IgntTiming : 48|16@1+ (0.0078125,-200) [-200|301.99] "deg" Vector__XXX
   SG_ EngCyl15IgntTiming : 32|16@1+ (0.0078125,-200) [-200|301.99] "deg" Vector__XXX
   SG_ EngCyl14IgntTiming : 16|16@1+ (0.0078125,-200) [-200|301.99] "deg" Vector__XXX
   SG_ EngCyl13IgntTiming : 0|16@1+ (0.0078125,-200) [-200|301.99] "deg" Vector__XXX

BO_ 2633925886 IT3: 8 Vector__XXX
   SG_ EngCyl12IgntTiming : 48|16@1+ (0.0078125,-200) [-200|301.99] "deg" Vector__XXX
   SG_ EngCyl11IgntTiming : 32|16@1+ (0.0078125,-200) [-200|301.99] "deg" Vector__XXX
   SG_ EngCyl10IgntTiming : 16|16@1+ (0.0078125,-200) [-200|301.99] "deg" Vector__XXX
   SG_ EngCyl9IgntTiming : 0|16@1+ (0.0078125,-200) [-200|301.99] "deg" Vector__XXX

BO_ 2633925630 IT2: 8 Vector__XXX
   SG_ EngCyl8IgntTiming : 48|16@1+ (0.0078125,-200) [-200|301.99] "deg" Vector__XXX
   SG_ EngCyl7IgntTiming : 32|16@1+ (0.0078125,-200) [-200|301.99] "deg" Vector__XXX
   SG_ EngCyl6IgntTiming : 16|16@1+ (0.0078125,-200) [-200|301.99] "deg" Vector__XXX
   SG_ EngCyl5IgntTiming : 0|16@1+ (0.0078125,-200) [-200|301.99] "deg" Vector__XXX

BO_ 2633925374 IT1: 8 Vector__XXX
   SG_ EngCyl4IgntTiming : 48|16@1+ (0.0078125,-200) [-200|301.99] "deg" Vector__XXX
   SG_ EngCyl3IgntTiming : 32|16@1+ (0.0078125,-200) [-200|301.99] "deg" Vector__XXX
   SG_ EngCyl2IgntTiming : 16|16@1+ (0.0078125,-200) [-200|301.99] "deg" Vector__XXX
   SG_ EngCyl1IgntTiming : 0|16@1+ (0.0078125,-200) [-200|301.99] "deg" Vector__XXX

BO_ 2633927422 ISO3: 8 Vector__XXX
   SG_ EngCyl20IgntTransSecondOutput : 24|8@1+ (1,-125) [-125|125] "%" Vector__XXX
   SG_ EngCyl19IgntTransSecondOutput : 16|8@1+ (1,-125) [-125|125] "%" Vector__XXX
   SG_ EngCyl18IgntTransSecondOutput : 8|8@1+ (1,-125) [-125|125] "%" Vector__XXX
   SG_ EngCyl17IgntTransSecondOutput : 0|8@1+ (1,-125) [-125|125] "%" Vector__XXX

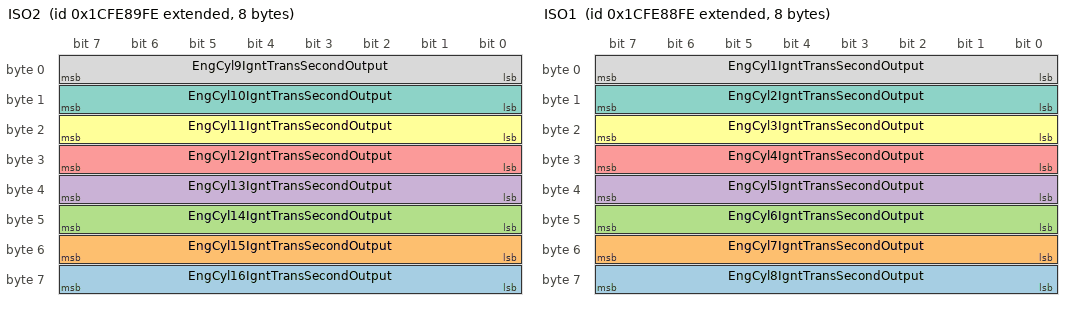
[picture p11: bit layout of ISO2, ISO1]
BO_ 2633927166 ISO2: 8 Vector__XXX
   SG_ EngCyl16IgntTransSecondOutput : 56|8@1+ (1,-125) [-125|125] "%" Vector__XXX
   SG_ EngCyl15IgntTransSecondOutput : 48|8@1+ (1,-125) [-125|125] "%" Vector__XXX
   SG_ EngCyl14IgntTransSecondOutput : 40|8@1+ (1,-125) [-125|125] "%" Vector__XXX
   SG_ EngCyl13IgntTransSecondOutput : 32|8@1+ (1,-125) [-125|125] "%" Vector__XXX
   SG_ EngCyl12IgntTransSecondOutput : 24|8@1+ (1,-125) [-125|125] "%" Vector__XXX
   SG_ EngCyl11IgntTransSecondOutput : 16|8@1+ (1,-125) [-125|125] "%" Vector__XXX
   SG_ EngCyl10IgntTransSecondOutput : 8|8@1+ (1,-125) [-125|125] "%" Vector__XXX
   SG_ EngCyl9IgntTransSecondOutput : 0|8@1+ (1,-125) [-125|125] "%" Vector__XXX

BO_ 2633926910 ISO1: 8 Vector__XXX
   SG_ EngCyl8IgntTransSecondOutput : 56|8@1+ (1,-125) [-125|125] "%" Vector__XXX
   SG_ EngCyl7IgntTransSecondOutput : 48|8@1+ (1,-125) [-125|125] "%" Vector__XXX
   SG_ EngCyl6IgntTransSecondOutput : 40|8@1+ (1,-125) [-125|125] "%" Vector__XXX
   SG_ EngCyl5IgntTransSecondOutput : 32|8@1+ (1,-125) [-125|125] "%" Vector__XXX
   SG_ EngCyl4IgntTransSecondOutput : 24|8@1+ (1,-125) [-125|125] "%" Vector__XXX
   SG_ EngCyl3IgntTransSecondOutput : 16|8@1+ (1,-125) [-125|125] "%" Vector__XXX
   SG_ EngCyl2IgntTransSecondOutput : 8|8@1+ (1,-125) [-125|125] "%" Vector__XXX
   SG_ EngCyl1IgntTransSecondOutput : 0|8@1+ (1,-125) [-125|125] "%" Vector__XXX

BO_ 2566768894 ISCS: 8 Vector__XXX
   SG_ EngOprtrPrmryIntrmdtSpdSlctStte : 0|4@1+ (1,0) [0|15] "" Vector__XXX

BO_ 2566769406 ISC: 8 Vector__XXX
   SG_ EngOprtrPrmryIntrmdtSpeedSelect : 0|4@1+ (1,0) [0|15] "" Vector__XXX

BO_ 2566839550 IO: 8 Vector__XXX
   SG_ EngTotalIdleHours : 32|32@1+ (0.05,0) [0|2.10554e+08] "hr" Vector__XXX
   SG_ EngTotalIdleFuelUsed : 0|32@1+ (0.5,0) [0|2.10554e+09] "L" Vector__XXX

BO_ 2633934334 IMT2: 8 Vector__XXX
   SG_ EngIntakeManifold6Temp : 32|8@1+ (1,-40) [-40|210] "deg C" Vector__XXX
   SG_ EngIntakeManifold5Temp : 24|8@1+ (1,-40) [-40|210] "deg C" Vector__XXX
   SG_ EngIntakeManifold4Temp : 16|8@1+ (1,-40) [-40|210] "deg C" Vector__XXX
   SG_ EngIntakeManifold3Temp : 8|8@1+ (1,-40) [-40|210] "deg C" Vector__XXX
   SG_ EngIntakeManifold2Temp : 0|8@1+ (1,-40) [-40|210] "deg C" Vector__XXX

BO_ 2566825726 IMT1: 8 Vector__XXX
   SG_ EngTurbo4BoostPress : 48|16@1+ (0.125,0) [0|8031.88] "kPa" Vector__XXX
   SG_ EngTurbo3BoostPress : 32|16@1+ (0.125,0) [0|8031.88] "kPa" Vector__XXX
   SG_ EngTurbo2BoostPress : 16|16@1+ (0.125,0) [0|8031.88] "kPa" Vector__XXX
   SG_ EngTurbo1BoostPress : 0|16@1+ (0.125,0) [0|8031.88] "kPa" Vector__XXX

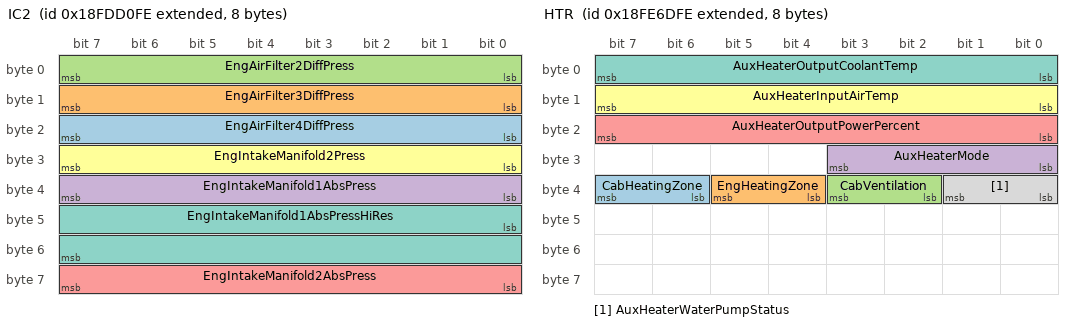
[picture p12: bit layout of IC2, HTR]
BO_ 2566770942 IC2: 8 Vector__XXX
   SG_ EngAirFilter4DiffPress : 16|8@1+ (0.05,0) [0|12.5] "kPa" Vector__XXX
   SG_ EngAirFilter3DiffPress : 8|8@1+ (0.05,0) [0|12.5] "kPa" Vector__XXX
   SG_ EngAirFilter2DiffPress : 0|8@1+ (0.05,0) [0|12.5] "kPa" Vector__XXX
   SG_ EngIntakeManifold1AbsPress : 32|8@1+ (0.1,0) [0|25.5] "kPa" Vector__XXX
   SG_ EngIntakeManifold2AbsPress : 56|8@1+ (2,0) [0|500] "kPa" Vector__XXX
   SG_ EngIntakeManifold2Press : 24|8@1+ (2,0) [0|500] "kPa" Vector__XXX
   SG_ EngIntakeManifold1AbsPressHiRes : 40|16@1+ (0.1,0) [0|6425.5] "kPa" Vector__XXX

BO_ 2566846206 IC1: 8 Vector__XXX
   SG_ EngCoolantFilterDiffPress : 56|8@1+ (0.5,0) [0|125] "kPa" Vector__XXX
   SG_ EngExhaustGasTemp : 40|16@1+ (0.03125,-273) [-273|1734.97] "deg C" Vector__XXX
   SG_ EngAirFilter1DiffPress : 32|8@1+ (0.05,0) [0|12.5] "kPa" Vector__XXX
   SG_ EngIntakeManifold1Temp : 16|8@1+ (1,-40) [-40|210] "deg C" Vector__XXX
   SG_ EngIntakeManifold1Press : 8|8@1+ (2,0) [0|500] "kPa" Vector__XXX
   SG_ EngDslPrtclateFilterIntakePress : 0|8@1+ (0.5,0) [0|125] "kPa" Vector__XXX
   SG_ EngAirIntakePress : 24|8@1+ (2,0) [0|500] "kPa" Vector__XXX

BO_ 2566811134 HTR: 8 Vector__XXX
   SG_ CabHeatingZone : 38|2@1+ (1,0) [0|3] "" Vector__XXX
   SG_ EngHeatingZone : 36|2@1+ (1,0) [0|3] "" Vector__XXX
   SG_ CabVentilation : 34|2@1+ (1,0) [0|3] "" Vector__XXX
   SG_ AuxHeaterMode : 24|4@1+ (1,0) [0|15] "" Vector__XXX
   SG_ AuxHeaterOutputPowerPercent : 16|8@1+ (0.4,0) [0|100] "%" Vector__XXX
   SG_ AuxHeaterInputAirTemp : 8|8@1+ (1,-40) [-40|210] "deg C" Vector__XXX
   SG_ AuxHeaterOutputCoolantTemp : 0|8@1+ (1,-40) [-40|210] "deg C" Vector__XXX
   SG_ AuxHeaterWaterPumpStatus : 32|2@1+ (1,0) [0|3] "" Vector__XXX

BO_ 2298375934 HRW: 8 Vector__XXX
   SG_ RearAxleRightWheelSpeed : 48|16@1+ (0.00390625,0) [0|250.996] "km/h" Vector__XXX
   SG_ RearAxleLeftWheelSpeed : 32|16@1+ (0.00390625,0) [0|250.996] "km/h" Vector__XXX
   SG_ FrontAxleRightWheelSpeed : 16|16@1+ (0.00390625,0) [0|250.996] "km/h" Vector__XXX
   SG_ FrontAxleLeftWheelSpeed : 0|16@1+ (0.00390625,0) [0|250.996] "km/h" Vector__XXX

BO_ 2565867774 HPG: 8 Vector__XXX
   SG_ FireApparatusPumpEngagement : 20|2@1+ (1,0) [0|3] "" Vector__XXX
   SG_ EngHydPressGovernorSwitch : 18|2@1+ (1,0) [0|3] "" Vector__XXX
   SG_ EngHydPrssGovernorModeIndicator : 16|2@1+ (1,0) [0|3] "" Vector__XXX
   SG_ HydPress : 0|16@1+ (2,0) [0|128510] "kPa" Vector__XXX

BO_ 2566841854 HOURS: 8 Vector__XXX
   SG_ EngTotalRevolutions : 32|32@1+ (1000,0) [0|4.21108e+12] "r" Vector__XXX
   SG_ EngTotalHoursOfOperation : 0|32@1+ (0.05,0) [0|2.10554e+08] "hr" Vector__XXX

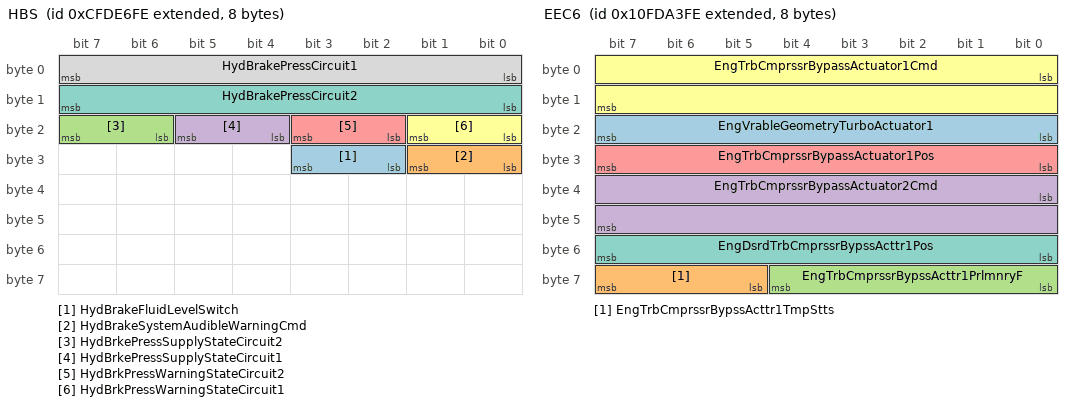
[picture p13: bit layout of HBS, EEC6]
BO_ 2365449982 HBS: 8 Vector__XXX
   SG_ HydBrakeFluidLevelSwitch : 26|2@1+ (1,0) [0|3] "" Vector__XXX
   SG_ HydBrakeSystemAudibleWarningCmd : 24|2@1+ (1,0) [0|3] "" Vector__XXX
   SG_ HydBrkePressSupplyStateCircuit2 : 22|2@1+ (1,0) [0|3] "" Vector__XXX
   SG_ HydBrkePressSupplyStateCircuit1 : 20|2@1+ (1,0) [0|3] "" Vector__XXX
   SG_ HydBrkPressWarningStateCircuit2 : 18|2@1+ (1,0) [0|3] "" Vector__XXX
   SG_ HydBrkPressWarningStateCircuit1 : 16|2@1+ (1,0) [0|3] "" Vector__XXX
   SG_ HydBrakePressCircuit2 : 8|8@1+ (100,0) [0|25] "MPa" Vector__XXX
   SG_ HydBrakePressCircuit1 : 0|8@1+ (100,0) [0|25] "MPa" Vector__XXX

BO_ 2633939198 GTFI: 22 Vector__XXX
   SG_ TripDriveFuelEconomy : 160|16@1+ (0.00195313,0) [0|125.5] "km/kg" Vector__XXX
   SG_ TrpPTOGovernorNonmovingFuelUsed : 64|32@1+ (0.5,0) [0|2.10554e+09] "kg" Vector__XXX
   SG_ TripVehicleIdleFuelUsed : 96|32@1+ (0.5,0) [0|2.10554e+09] "kg" Vector__XXX
   SG_ TripCruiseFuelUsed : 128|32@1+ (0.5,0) [0|2.10554e+09] "kg" Vector__XXX
   SG_ TripDriveFuelUsed : 0|32@1+ (0.5,0) [0|2.10554e+09] "kg" Vector__XXX
   SG_ TripPTOGovernorMovingFuelUsed : 32|32@1+ (0.5,0) [0|2.10554e+09] "kg" Vector__XXX

BO_ 2633927678 GFP: 8 Vector__XXX
   SG_ EngFuelValve1OutletAbsPress : 48|16@1+ (0.1,0) [0|6425.5] "kPa" Vector__XXX
   SG_ EngAirToFuelDiffPress : 32|16@1+ (0.1,0) [0|6425.5] "kPa" Vector__XXX
   SG_ EngFuelValveDiffPress : 16|16@1+ (0.1,0) [0|6425.5] "kPa" Vector__XXX
   SG_ EngFuelValve1IntakeAbsPress : 0|16@1+ (0.1,0) [0|6425.5] "kPa" Vector__XXX

BO_ 2633925118 GFI2: 8 Vector__XXX
   SG_ EngFuelFlowRate2 : 16|16@1+ (0.1,0) [0|6425.5] "(m*m*m)/h" Vector__XXX
   SG_ EngFuelFlowRate1 : 0|16@1+ (0.1,0) [0|6425.5] "(m*m*m)/h" Vector__XXX
   SG_ EngRqedFuelValve2Pos : 56|8@1+ (0.4,0) [0|100] "%" Vector__XXX
   SG_ EngRqedFuelValve1Pos : 48|8@1+ (0.4,0) [0|100] "%" Vector__XXX
   SG_ EngFuelValve2Pos : 40|8@1+ (0.4,0) [0|100] "%" Vector__XXX
   SG_ EngFuelValve1Pos : 32|8@1+ (0.4,0) [0|100] "%" Vector__XXX

BO_ 2633937662 GFI1: 8 Vector__XXX
   SG_ TotalEngPTOGovernorFuelUsed : 0|32@1+ (0.5,0) [0|2.10554e+09] "kg" Vector__XXX
   SG_ TripAverageFuelRate : 32|16@1+ (0.05,0) [0|3212.75] "kg/h" Vector__XXX
   SG_ EngFuelSpecificGravity : 48|16@1+ (0.0001,0) [0|6.4255] "" Vector__XXX

BO_ 2566804990 GFD: 8 Vector__XXX
   SG_ SpecificHeatRatio : 0|16@1+ (0.001,0) [0|64.255] "" Vector__XXX

BO_ 2633936894 GFC: 8 Vector__XXX
   SG_ TotalFuelUsed : 32|32@1+ (0.5,0) [0|2.10554e+09] "kg" Vector__XXX
   SG_ TripFuel : 0|32@1+ (0.5,0) [0|2.10554e+09] "kg" Vector__XXX

BO_ 2566757630 SEP2: 8 Vector__XXX
   SG_ SensorSupplyVoltage6 : 16|16@1+ (0.05,0) [0|3212.75] "V" Vector__XXX
   SG_ SensorSupplyVoltage5 : 0|16@1+ (0.05,0) [0|3212.75] "V" Vector__XXX
   SG_ SensorSupplyVoltage8 : 48|16@1+ (0.05,0) [0|3212.75] "V" Vector__XXX
   SG_ SensorSupplyVoltage7 : 32|16@1+ (0.05,0) [0|3212.75] "V" Vector__XXX

BO_ 2566757886 SEP1: 8 Vector__XXX
   SG_ SensorSupplyVoltage4 : 48|16@1+ (0.05,0) [0|3212.75] "V" Vector__XXX
   SG_ SensorSupplyVoltage3 : 32|16@1+ (0.05,0) [0|3212.75] "V" Vector__XXX
   SG_ SensorSupplyVoltage2 : 16|16@1+ (0.05,0) [0|3212.75] "V" Vector__XXX
   SG_ SensorSupplyVoltage1 : 0|16@1+ (0.05,0) [0|3212.75] "V" Vector__XXX

BO_ 2566759678 PTODE: 8 Vector__XXX
   SG_ EnggmntSttusTransInputShaftPTO1 : 38|2@1+ (1,0) [0|3] "" Vector__XXX
   SG_ EnggmntSttusTransInputShaftPTO2 : 36|2@1+ (1,0) [0|3] "" Vector__XXX
   SG_ EnggmntSttusTransOutputShaftPTO : 34|2@1+ (1,0) [0|3] "" Vector__XXX
   SG_ EnggmntSttsTrnsfrCsOtptShaftPTO : 32|2@1+ (1,0) [0|3] "" Vector__XXX
   SG_ EnggmntCnsntTransInputShaftPTO1 : 22|2@1+ (1,0) [0|3] "" Vector__XXX
   SG_ EnggmntCnsntTransInputShaftPTO2 : 20|2@1+ (1,0) [0|3] "" Vector__XXX
   SG_ EnggmntCnsntTransOutputShaftPTO : 18|2@1+ (1,0) [0|3] "" Vector__XXX
   SG_ EnggmntCnsntTrnsfrCsOtptShftPTO : 16|2@1+ (1,0) [0|3] "" Vector__XXX
   SG_ EnableSwitchTransInputShaftPTO1 : 6|2@1+ (1,0) [0|3] "" Vector__XXX
   SG_ EnableSwitchTransInputShaftPTO2 : 4|2@1+ (1,0) [0|3] "" Vector__XXX
   SG_ EnableSwitchTransOutputShaftPTO : 2|2@1+ (1,0) [0|3] "" Vector__XXX
   SG_ EnblSwtchTrnsfrCsOutputShaftPTO : 0|2@1+ (1,0) [0|3] "" Vector__XXX
   SG_ EnggmntSttsPTOEngAccssoryDrive2 : 44|2@1+ (1,0) [0|3] "" Vector__XXX
   SG_ EnggmntSttsPTOEngAccssoryDrive1 : 42|2@1+ (1,0) [0|3] "" Vector__XXX
   SG_ EnggmntCnsntPTOEngAccssryDrive2 : 28|2@1+ (1,0) [0|3] "" Vector__XXX
   SG_ EnggmntCnsntPTOEngAccssryDrive1 : 26|2@1+ (1,0) [0|3] "" Vector__XXX
   SG_ EngagementStatusPTOEngFlywheel : 40|2@1+ (1,0) [0|3] "" Vector__XXX
   SG_ EngagementConsentPTOEngFlywheel : 24|2@1+ (1,0) [0|3] "" Vector__XXX
   SG_ EnblSwitchPTOEngAccessoryDrive2 : 12|2@1+ (1,0) [0|3] "" Vector__XXX
   SG_ EnblSwitchPTOEngAccessoryDrive1 : 10|2@1+ (1,0) [0|3] "" Vector__XXX
   SG_ EnableSwitchPTOEngFlywheel : 8|2@1+ (1,0) [0|3] "" Vector__XXX
   SG_ AtLeastOnePTOEngaged : 48|2@1+ (1,0) [0|3] "" Vector__XXX

BO_ 2432541438 GFI3: 8 Vector__XXX
   SG_ EngFuelValve2OutletAbsPress : 48|16@1+ (0.1,0) [0|6425.5] "kPa" Vector__XXX
   SG_ EngFuelTemp2 : 32|8@1+ (1,-40) [-40|210] "deg C" Vector__XXX
   SG_ EngGas2MassFlowRate : 16|16@1+ (0.05,0) [0|3212.75] "kg/h" Vector__XXX
   SG_ EngFuelValve2IntakeAbsPress : 0|16@1+ (0.1,0) [0|6425.5] "kPa" Vector__XXX

BO_ 2566761214 EFL_P4: 8 Vector__XXX
   SG_ EngCentrifugalOilFilterSpeed : 24|16@1+ (4,0) [0|257020] "rpm" Vector__XXX
   SG_ EngCoolantPumpDiffPress : 16|8@1+ (1.64,-7) [-7|403] "kPa" Vector__XXX
   SG_ EngChargeAirCooler2IntakePress : 8|8@1+ (2,0) [0|500] "kPa" Vector__XXX
   SG_ EngChargeAirCooler1IntakePress : 0|8@1+ (2,0) [0|500] "kPa" Vector__XXX
   SG_ EngIntercoolerCoolantLevel : 40|8@1+ (0.4,0) [0|100] "%" Vector__XXX
   SG_ EngChargeAirCoolerOutletPress : 56|8@1+ (2,0) [0|500] "kPa" Vector__XXX
   SG_ EngAftercoolerCoolantLevel : 48|8@1+ (0.4,0) [0|100] "%" Vector__XXX

BO_ 2432541694 EEC6: 8 Vector__XXX
   SG_ EngVrableGeometryTurboActuator1 : 16|8@1+ (0.4,0) [0|100] "%" Vector__XXX
   SG_ EngTrbCmprssrBypssActtr1TmpStts : 61|3@1+ (1,0) [0|7] "" Vector__XXX
   SG_ EngTrbCmprssrBypssActtr1PrlmnryF : 56|5@1+ (1,0) [0|31] "" Vector__XXX
   SG_ EngTrbCmprssrBypassActuator2Cmd : 32|16@1+ (0.0025,0) [0|160.637] "%" Vector__XXX
   SG_ EngTrbCmprssrBypassActuator1Pos : 24|8@1+ (0.4,0) [0|100] "%" Vector__XXX
   SG_ EngTrbCmprssrBypassActuator1Cmd : 0|16@1+ (0.0025,0) [0|160.637] "%" Vector__XXX
   SG_ EngDsrdTrbCmprssrBypssActtr1Pos : 48|8@1+ (0.4,0) [0|100] "%" Vector__XXX

BO_ 2566759934 DC2: 8 Vector__XXX
   SG_ EnableStatusOfDoor10 : 58|2@1+ (1,0) [0|3] "" Vector__XXX
   SG_ OpenStatusOfDoor10 : 56|2@1+ (1,0) [0|3] "" Vector__XXX
   SG_ LockStatusOfDoor10 : 54|2@1+ (1,0) [0|3] "" Vector__XXX
   SG_ EnableStatusOfDoor9 : 52|2@1+ (1,0) [0|3] "" Vector__XXX
   SG_ OpenStatusOfDoor9 : 50|2@1+ (1,0) [0|3] "" Vector__XXX
   SG_ LockStatusOfDoor9 : 48|2@1+ (1,0) [0|3] "" Vector__XXX
   SG_ EnableStatusOfDoor8 : 46|2@1+ (1,0) [0|3] "" Vector__XXX
   SG_ OpenStatusOfDoor8 : 44|2@1+ (1,0) [0|3] "" Vector__XXX
   SG_ LockStatusOfDoor8 : 42|2@1+ (1,0) [0|3] "" Vector__XXX
   SG_ EnableStatusOfDoor7 : 40|2@1+ (1,0) [0|3] "" Vector__XXX
   SG_ OpenStatusOfDoor7 : 38|2@1+ (1,0) [0|3] "" Vector__XXX
   SG_ LockStatusOfDoor7 : 36|2@1+ (1,0) [0|3] "" Vector__XXX
   SG_ EnableStatusOfDoor6 : 34|2@1+ (1,0) [0|3] "" Vector__XXX
   SG_ OpenStatusOfDoor6 : 32|2@1+ (1,0) [0|3] "" Vector__XXX
   SG_ LockStatusOfDoor6 : 30|2@1+ (1,0) [0|3] "" Vector__XXX
   SG_ EnableStatusOfDoor5 : 28|2@1+ (1,0) [0|3] "" Vector__XXX
   SG_ OpenStatusOfDoor5 : 26|2@1+ (1,0) [0|3] "" Vector__XXX
   SG_ LockStatusOfDoor5 : 24|2@1+ (1,0) [0|3] "" Vector__XXX
   SG_ EnableStatusOfDoor4 : 22|2@1+ (1,0) [0|3] "" Vector__XXX
   SG_ OpenStatusOfDoor4 : 20|2@1+ (1,0) [0|3] "" Vector__XXX
   SG_ LockStatusOfDoor4 : 18|2@1+ (1,0) [0|3] "" Vector__XXX
   SG_ EnableStatusOfDoor3 : 16|2@1+ (1,0) [0|3] "" Vector__XXX
   SG_ OpenStatusOfDoor3 : 14|2@1+ (1,0) [0|3] "" Vector__XXX
   SG_ LockStatusOfDoor3 : 12|2@1+ (1,0) [0|3] "" Vector__XXX
   SG_ EnableStatusOfDoor2 : 10|2@1+ (1,0) [0|3] "" Vector__XXX
   SG_ OpenStatusOfDoor2 : 8|2@1+ (1,0) [0|3] "" Vector__XXX
   SG_ LockStatusOfDoor2 : 6|2@1+ (1,0) [0|3] "" Vector__XXX
   SG_ EnableStatusOfDoor1 : 4|2@1+ (1,0) [0|3] "" Vector__XXX
   SG_ OpenStatusOfDoor1 : 2|2@1+ (1,0) [0|3] "" Vector__XXX
   SG_ LockStatusOfDoor1 : 0|2@1+ (1,0) [0|3] "" Vector__XXX

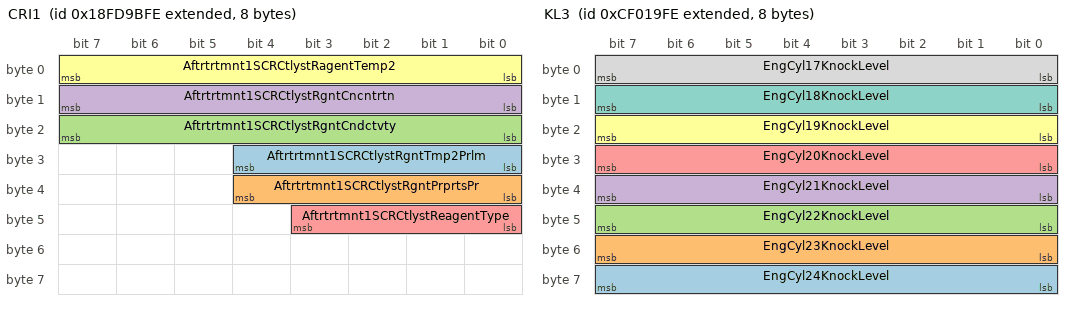
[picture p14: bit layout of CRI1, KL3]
BO_ 2566757374 CRI1: 8 Vector__XXX
   SG_ Aftrtrtmnt1SCRCtlystRgntTmp2Prlm : 24|5@1+ (1,0) [0|31] "" Vector__XXX
   SG_ Aftrtrtmnt1SCRCtlystRgntPrprtsPr : 32|5@1+ (1,0) [0|31] "" Vector__XXX
   SG_ Aftrtrtmnt1SCRCtlystRgntCndctvty : 16|8@1+ (5,0) [0|1250] "microSiemens/mm" Vector__XXX
   SG_ Aftrtrtmnt1SCRCtlystRgntCncntrtn : 8|8@1+ (0.25,0) [0|62.5] "%" Vector__XXX
   SG_ Aftrtrtmnt1SCRCtlystReagentType : 40|4@1+ (1,0) [0|15] "" Vector__XXX
   SG_ Aftrtrtmnt1SCRCtlystRagentTemp2 : 0|8@1+ (1,-40) [-40|210] "deg C" Vector__XXX

BO_ 2364546302 RGAAQ: 8 Vector__XXX
   SG_ RqdGnrtrAvrgLneLineACRMSVoltage : 0|32@1+ (0.0078125,0) [0|3.28991e+07] "V" Vector__XXX

BO_ 2431654654 TFAC: 8 Vector__XXX
   SG_ EngThrottleActuator2CtrlCmd : 16|16@1+ (0.0025,0) [0|160.637] "%" Vector__XXX
   SG_ EngThrottleActuator1CtrlCmd : 0|16@1+ (0.0025,0) [0|160.637] "%" Vector__XXX
   SG_ EngFuelActuator2CtrlCmd : 48|16@1+ (0.0025,0) [0|160.637] "%" Vector__XXX
   SG_ EngFuelActuator1CtrlCmd : 32|16@1+ (0.0025,0) [0|160.637] "%" Vector__XXX

BO_ 2364545534 KL3: 8 Vector__XXX
   SG_ EngCyl24KnockLevel : 56|8@1+ (1,0) [0|250] "%" Vector__XXX
   SG_ EngCyl23KnockLevel : 48|8@1+ (1,0) [0|250] "%" Vector__XXX
   SG_ EngCyl22KnockLevel : 40|8@1+ (1,0) [0|250] "%" Vector__XXX
   SG_ EngCyl21KnockLevel : 32|8@1+ (1,0) [0|250] "%" Vector__XXX
   SG_ EngCyl20KnockLevel : 24|8@1+ (1,0) [0|250] "%" Vector__XXX
   SG_ EngCyl19KnockLevel : 16|8@1+ (1,0) [0|250] "%" Vector__XXX
   SG_ EngCyl18KnockLevel : 8|8@1+ (1,0) [0|250] "%" Vector__XXX
   SG_ EngCyl17KnockLevel : 0|8@1+ (1,0) [0|250] "%" Vector__XXX

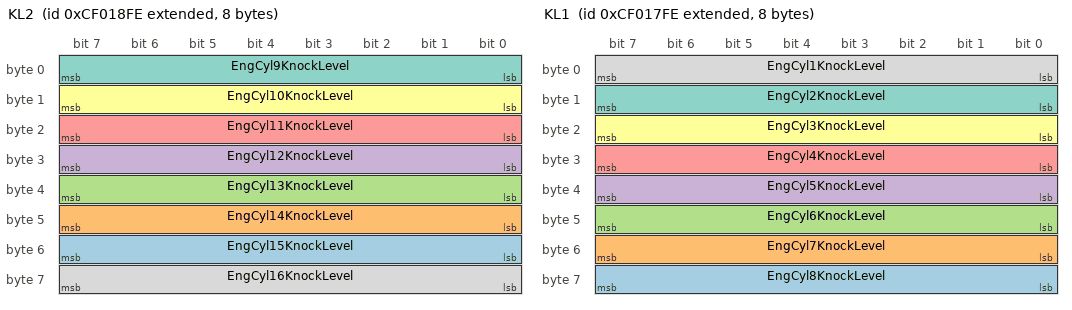
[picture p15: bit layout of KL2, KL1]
BO_ 2364545278 KL2: 8 Vector__XXX
   SG_ EngCyl15KnockLevel : 48|8@1+ (1,0) [0|250] "%" Vector__XXX
   SG_ EngCyl14KnockLevel : 40|8@1+ (1,0) [0|250] "%" Vector__XXX
   SG_ EngCyl13KnockLevel : 32|8@1+ (1,0) [0|250] "%" Vector__XXX
   SG_ EngCyl12KnockLevel : 24|8@1+ (1,0) [0|250] "%" Vector__XXX
   SG_ EngCyl11KnockLevel : 16|8@1+ (1,0) [0|250] "%" Vector__XXX
   SG_ EngCyl10KnockLevel : 8|8@1+ (1,0) [0|250] "%" Vector__XXX
   SG_ EngCyl9KnockLevel : 0|8@1+ (1,0) [0|250] "%" Vector__XXX
   SG_ EngCyl16KnockLevel : 56|8@1+ (1,0) [0|250] "%" Vector__XXX

BO_ 2364545022 KL1: 8 Vector__XXX
   SG_ EngCyl8KnockLevel : 56|8@1+ (1,0) [0|250] "%" Vector__XXX
   SG_ EngCyl7KnockLevel : 48|8@1+ (1,0) [0|250] "%" Vector__XXX
   SG_ EngCyl6KnockLevel : 40|8@1+ (1,0) [0|250] "%" Vector__XXX
   SG_ EngCyl5KnockLevel : 32|8@1+ (1,0) [0|250] "%" Vector__XXX
   SG_ EngCyl4KnockLevel : 24|8@1+ (1,0) [0|250] "%" Vector__XXX
   SG_ EngCyl3KnockLevel : 16|8@1+ (1,0) [0|250] "%" Vector__XXX
   SG_ EngCyl2KnockLevel : 8|8@1+ (1,0) [0|250] "%" Vector__XXX
   SG_ EngCyl1KnockLevel : 0|8@1+ (1,0) [0|250] "%" Vector__XXX

BO_ 2364544766 CCS: 8 Vector__XXX
   SG_ EngCyl9CombustionStatus : 16|2@1+ (1,0) [0|3] "" Vector__XXX
   SG_ EngCyl8CombustionStatus : 14|2@1+ (1,0) [0|3] "" Vector__XXX
   SG_ EngCyl7CombustionStatus : 12|2@1+ (1,0) [0|3] "" Vector__XXX
   SG_ EngCyl6CombustionStatus : 10|2@1+ (1,0) [0|3] "" Vector__XXX
   SG_ EngCyl5CombustionStatus : 8|2@1+ (1,0) [0|3] "" Vector__XXX
   SG_ EngCyl4CombustionStatus : 6|2@1+ (1,0) [0|3] "" Vector__XXX
   SG_ EngCyl3CombustionStatus : 4|2@1+ (1,0) [0|3] "" Vector__XXX
   SG_ EngCyl2CombustionStatus : 2|2@1+ (1,0) [0|3] "" Vector__XXX
   SG_ EngCyl24CombustionStatus : 46|2@1+ (1,0) [0|3] "" Vector__XXX
   SG_ EngCyl23CombustionStatus : 44|2@1+ (1,0) [0|3] "" Vector__XXX
   SG_ EngCyl22CombustionStatus : 42|2@1+ (1,0) [0|3] "" Vector__XXX
   SG_ EngCyl21CombustionStatus : 40|2@1+ (1,0) [0|3] "" Vector__XXX
   SG_ EngCyl20CombustionStatus : 38|2@1+ (1,0) [0|3] "" Vector__XXX
   SG_ EngCyl1CombustionStatus : 0|2@1+ (1,0) [0|3] "" Vector__XXX
   SG_ EngCyl19CombustionStatus : 36|2@1+ (1,0) [0|3] "" Vector__XXX
   SG_ EngCyl18CombustionStatus : 34|2@1+ (1,0) [0|3] "" Vector__XXX
   SG_ EngCyl17CombustionStatus : 32|2@1+ (1,0) [0|3] "" Vector__XXX
   SG_ EngCyl16CombustionStatus : 30|2@1+ (1,0) [0|3] "" Vector__XXX
   SG_ EngCyl15CombustionStatus : 28|2@1+ (1,0) [0|3] "" Vector__XXX
   SG_ EngCyl14CombustionStatus : 26|2@1+ (1,0) [0|3] "" Vector__XXX
   SG_ EngCyl13CombustionStatus : 24|2@1+ (1,0) [0|3] "" Vector__XXX
   SG_ EngCyl12CombustionStatus : 22|2@1+ (1,0) [0|3] "" Vector__XXX
   SG_ EngCyl11CombustionStatus : 20|2@1+ (1,0) [0|3] "" Vector__XXX
   SG_ EngCyl10CombustionStatus : 18|2@1+ (1,0) [0|3] "" Vector__XXX

BO_ 2364544510 RGTARP: 8 Vector__XXX
   SG_ RqGenOverallPowerFactorLagging : 48|2@1+ (1,0) [0|4] "" Vector__XXX
   SG_ RqGeneratorOverallPowerFactor : 32|16@1+ (6.10352e-05,-1) [-1|2.92181] "" Vector__XXX
   SG_ RqGeneratorTotalACReactivePower : 0|32@1+ (1,-2e+09) [-2e+09|2e+09] "VA" Vector__XXX

BO_ 2364544254 BI: 8 Vector__XXX
   SG_ RltvBldHghtAndBldRttnAnglMsrmntL : 32|8@1+ (0.5,0) [0|125] "ms" Vector__XXX
   SG_ RlativeBladeHeightFigureOfMerit : 40|2@1+ (1,0) [0|3] "" Vector__XXX
   SG_ BladeRotationAngleFigureOfMerit : 42|2@1+ (1,0) [0|3] "" Vector__XXX
   SG_ BladeRotationAngle : 16|16@1+ (0.0078125,-200) [-200|301.99] "deg" Vector__XXX
   SG_ RelativeBladeHeight : 0|16@1+ (0.1,-3200) [-3200|3225.5] "mm" Vector__XXX

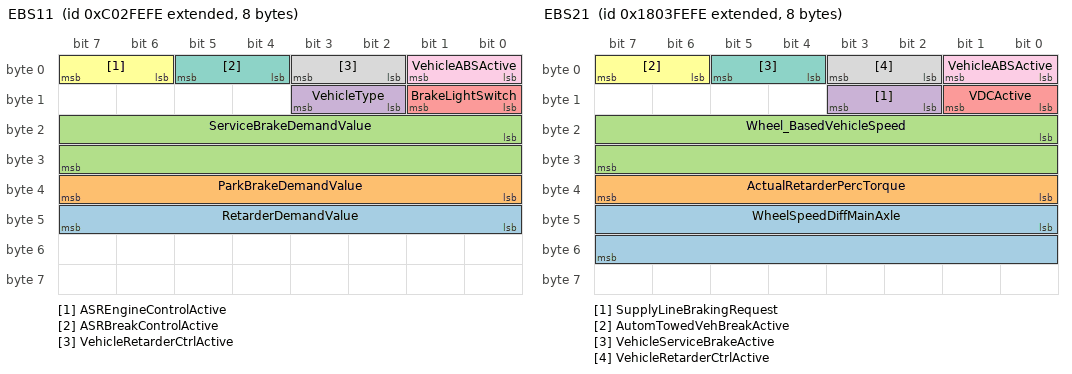
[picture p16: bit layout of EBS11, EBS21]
BO_ 2349006590 EBS11: 8 Vector__XXX
   SG_ RetarderDemandValue : 40|8@1+ (1,-125) [-125|125] "%" Vector__XXX
   SG_ ParkBrakeDemandValue : 32|8@1+ (0.4,0) [0|100] "%" Vector__XXX
   SG_ ServiceBrakeDemandValue : 16|16@1+ (0.0195313,0) [0|1255] "kPa" Vector__XXX
   SG_ VehicleType : 10|2@1+ (1,0) [0|3] "" Vector__XXX
   SG_ BrakeLightSwitch : 8|2@1+ (1,0) [0|3] "" Vector__XXX
   SG_ ASREngineControlActive : 6|2@1+ (1,0) [0|3] "" Vector__XXX
   SG_ ASRBreakControlActive : 4|2@1+ (1,0) [0|3] "" Vector__XXX
   SG_ VehicleRetarderCtrlActive : 2|2@1+ (1,0) [0|3] "" Vector__XXX
   SG_ VehicleABSActive : 0|2@1+ (1,0) [0|1] "" Vector__XXX

BO_ 2566834686 EBS12: 8 Vector__XXX
   SG_ RoadCurvature : 32|16@1+ (0.0078125,-250) [-250|251.992] "1/km" Vector__XXX
   SG_ PneumaticControlLine : 20|2@1+ (1,0) [0|1] "" Vector__XXX
   SG_ ABSOffroadRequest : 18|2@1+ (1,0) [0|1] "" Vector__XXX
   SG_ TwoElCircuitsBrakeDemand : 16|2@1+ (1,0) [0|1] "" Vector__XXX
   SG_ VehicleRetarderCtrlActive : 0|2@1+ (1,0) [0|3] "" Vector__XXX

BO_ 2550398718 EBS21: 8 Vector__XXX
   SG_ WheelSpeedDiffMainAxle : 40|16@1+ (0.00390625,-125) [-125|125] "km/hr" Vector__XXX
   SG_ ActualRetarderPercTorque : 32|8@1+ (1,-125) [-125|125] "%" Vector__XXX
   SG_ Wheel_BasedVehicleSpeed : 16|16@1+ (0.00390625,0) [0|251] "km/hr" Vector__XXX
   SG_ SupplyLineBrakingRequest : 10|2@1+ (1,0) [0|1] "" Vector__XXX
   SG_ VDCActive : 8|2@1+ (1,0) [0|1] "" Vector__XXX
   SG_ AutomTowedVehBreakActive : 6|2@1+ (1,0) [0|1] "" Vector__XXX
   SG_ VehicleServiceBrakeActive : 4|2@1+ (1,0) [0|1] "" Vector__XXX
   SG_ VehicleRetarderCtrlActive : 2|2@1+ (1,0) [0|3] "" Vector__XXX
   SG_ VehicleABSActive : 0|2@1+ (1,0) [0|1] "" Vector__XXX

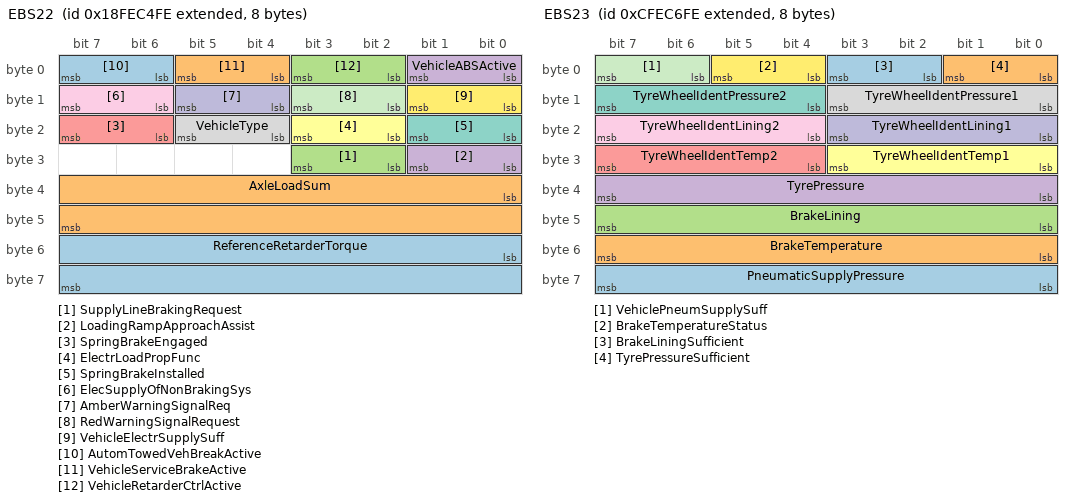
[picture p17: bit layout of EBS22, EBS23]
BO_ 2566833406 EBS22: 8 Vector__XXX
   SG_ ReferenceRetarderTorque : 48|16@1+ (1,0) [0|64255] "Nm" Vector__XXX
   SG_ AxleLoadSum : 32|16@1+ (2,0) [0|128510] "kg" Vector__XXX
   SG_ SupplyLineBrakingRequest : 26|2@1+ (1,0) [0|1] "" Vector__XXX
   SG_ LoadingRampApproachAssist : 24|2@1+ (1,0) [0|1] "" Vector__XXX
   SG_ SpringBrakeEngaged : 22|2@1+ (1,0) [0|1] "" Vector__XXX
   SG_ ElectrLoadPropFunc : 18|2@1+ (1,0) [0|1] "" Vector__XXX
   SG_ SpringBrakeInstalled : 16|2@1+ (1,0) [0|1] "" Vector__XXX
   SG_ VehicleType : 20|2@1+ (1,0) [0|3] "" Vector__XXX
   SG_ ElecSupplyOfNonBrakingSys : 14|2@1+ (1,0) [0|1] "" Vector__XXX
   SG_ AmberWarningSignalReq : 12|2@1+ (1,0) [0|1] "" Vector__XXX
   SG_ RedWarningSignalRequest : 10|2@1+ (1,0) [0|1] "" Vector__XXX
   SG_ VehicleElectrSupplySuff : 8|2@1+ (1,0) [0|1] "" Vector__XXX
   SG_ AutomTowedVehBreakActive : 6|2@1+ (1,0) [0|1] "" Vector__XXX
   SG_ VehicleServiceBrakeActive : 4|2@1+ (1,0) [0|1] "" Vector__XXX
   SG_ VehicleRetarderCtrlActive : 2|2@1+ (1,0) [0|3] "" Vector__XXX
   SG_ VehicleABSActive : 0|2@1+ (1,0) [0|1] "" Vector__XXX

BO_ 2365507326 EBS23: 8 Vector__XXX
   SG_ PneumaticSupplyPressure : 56|8@1+ (5,0) [0|1250] "kPa" Vector__XXX
   SG_ BrakeTemperature : 48|8@1+ (10,0) [0|2500] "deg C" Vector__XXX
   SG_ BrakeLining : 40|8@1+ (0.4,0) [0|100] "%" Vector__XXX
   SG_ TyrePressure : 32|8@1+ (10,0) [0|2500] "kPa" Vector__XXX
   SG_ TyreWheelIdentTemp2 : 28|4@1+ (1,0) [0|15] "" Vector__XXX
   SG_ TyreWheelIdentTemp1 : 24|4@1+ (1,0) [0|15] "" Vector__XXX
   SG_ TyreWheelIdentPressure2 : 12|4@1+ (1,0) [0|15] "" Vector__XXX
   SG_ TyreWheelIdentPressure1 : 8|4@1+ (1,0) [0|15] "" Vector__XXX
   SG_ TyreWheelIdentLining2 : 20|4@1+ (1,0) [0|15] "" Vector__XXX
   SG_ TyreWheelIdentLining1 : 16|4@1+ (1,0) [0|15] "" Vector__XXX
   SG_ VehiclePneumSupplySuff : 6|2@1+ (1,0) [0|1] "" Vector__XXX
   SG_ BrakeTemperatureStatus : 4|2@1+ (1,0) [0|1] "" Vector__XXX
   SG_ BrakeLiningSufficient : 2|2@1+ (1,0) [0|1] "" Vector__XXX
   SG_ TyrePressureSufficient : 0|2@1+ (1,0) [0|1] "" Vector__XXX

BO_ 2565013246 GPM11: 8 Vector__XXX
   SG_ ODDRequest : 10|2@1+ (1,0) [0|3] "" Vector__XXX
   SG_ AntiTheftDeviceReq : 8|2@1+ (1,0) [0|3] "" Vector__XXX
   SG_ VehicleType : 0|2@1+ (1,0) [0|3] "" Vector__XXX

BO_ 2566807038 GPM12: 8 Vector__XXX
   SG_ MaxVehicleSpeedLimit : 32|8@1+ (1,0) [0|250] "km/h" Vector__XXX
   SG_ EngineSpeedUpperLimit : 0|16@1+ (0.125,0) [0|8031.88] "rpm" Vector__XXX
   SG_ EngineSpeedLowerLimit : 16|16@1+ (0.125,0) [0|8191.88] "rpm" Vector__XXX

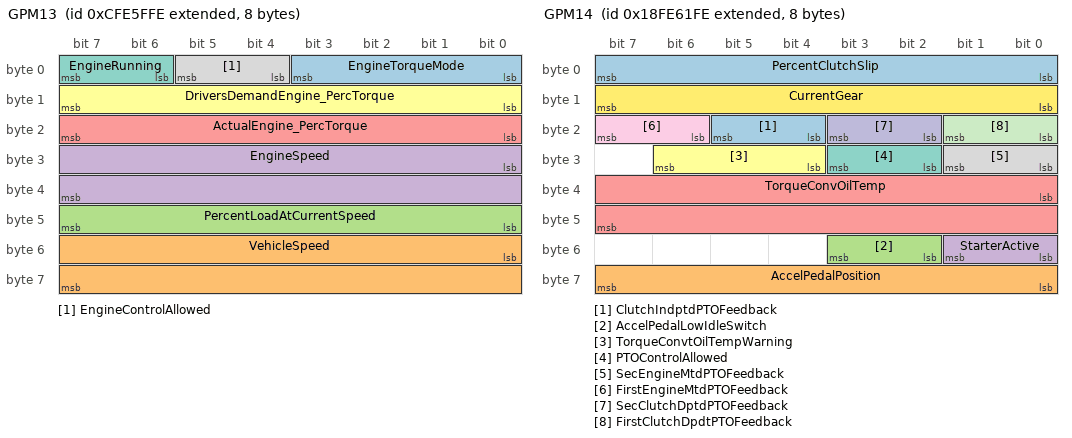
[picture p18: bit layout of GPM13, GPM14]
BO_ 2365480958 GPM13: 8 Vector__XXX
   SG_ EngineTorqueMode : 0|4@1+ (1,0) [0|15] "" Vector__XXX
   SG_ VehicleSpeed : 48|16@1+ (0.00390625,0) [0|250.996] "km/hr" Vector__XXX
   SG_ PercentLoadAtCurrentSpeed : 40|8@1+ (1,0) [0|125] "%" Vector__XXX
   SG_ EngineSpeed : 24|16@1+ (0.125,0) [0|8031.88] "rpm" Vector__XXX
   SG_ ActualEngine_PercTorque : 16|8@1+ (1,-125) [-125|125] "%" Vector__XXX
   SG_ DriversDemandEngine_PercTorque : 8|8@1+ (1,-125) [-125|125] "%" Vector__XXX
   SG_ EngineRunning : 6|2@1+ (1,0) [0|1] "" Vector__XXX
   SG_ EngineControlAllowed : 4|2@1+ (1,0) [0|1] "" Vector__XXX

BO_ 2566808062 GPM14: 8 Vector__XXX
   SG_ ClutchIndptdPTOFeedback : 20|2@1+ (1,0) [0|1] "" Vector__XXX
   SG_ AccelPedalPosition : 56|8@1+ (0.4,0) [0|100] "%" Vector__XXX
   SG_ AccelPedalLowIdleSwitch : 50|2@1+ (1,0) [0|1] "" Vector__XXX
   SG_ StarterActive : 48|2@1+ (1,0) [0|1] "" Vector__XXX
   SG_ TorqueConvOilTemp : 32|16@1+ (0.03125,-273) [-273|1735] "deg C" Vector__XXX
   SG_ TorqueConvtOilTempWarning : 28|3@1+ (1,0) [0|2] "" Vector__XXX
   SG_ PTOControlAllowed : 26|2@1+ (1,0) [0|1] "" Vector__XXX
   SG_ SecEngineMtdPTOFeedback : 24|2@1+ (1,0) [0|1] "" Vector__XXX
   SG_ FirstEngineMtdPTOFeedback : 22|2@1+ (1,0) [0|1] "" Vector__XXX
   SG_ SecClutchDptdPTOFeedback : 18|2@1+ (1,0) [0|1] "" Vector__XXX
   SG_ FirstClutchDpdtPTOFeedback : 16|2@1+ (1,0) [0|1] "" Vector__XXX
   SG_ CurrentGear : 8|8@1+ (1,-125) [-125|125] "" Vector__XXX
   SG_ PercentClutchSlip : 0|8@1+ (0.4,0) [0|100] "%" Vector__XXX

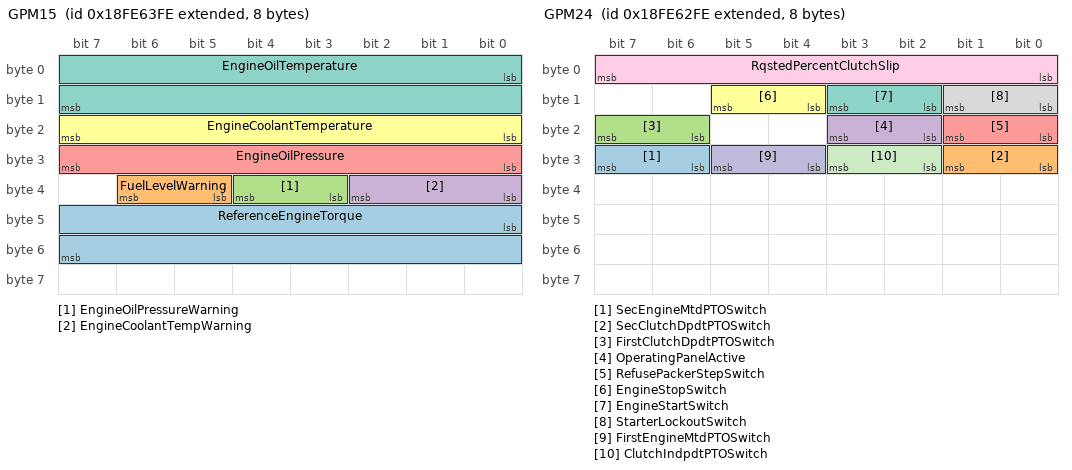
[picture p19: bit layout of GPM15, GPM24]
BO_ 2566808574 GPM15: 8 Vector__XXX
   SG_ ReferenceEngineTorque : 40|16@1+ (1,0) [0|64255] "Nm" Vector__XXX
   SG_ FuelLevelWarning : 37|2@1+ (1,0) [0|1] "" Vector__XXX
   SG_ EngineOilPressureWarning : 35|2@1+ (1,0) [0|1] "" Vector__XXX
   SG_ EngineCoolantTempWarning : 32|3@1+ (1,0) [0|2] "" Vector__XXX
   SG_ EngineOilPressure : 24|8@1+ (4,0) [0|1000] "kPa" Vector__XXX
   SG_ EngineCoolantTemperature : 16|8@1+ (1,-40) [-40|210] "deg C" Vector__XXX
   SG_ EngineOilTemperature : 0|16@1+ (0.03125,-273) [-273|1735] "deg C" Vector__XXX

BO_ 2566809086 GPM16: 8 Vector__XXX
   SG_ AmbientAirTemperature : 0|16@1+ (0.03125,-273) [-273|1735] "deg C" Vector__XXX

BO_ 2564947710 GPM21: 8 Vector__XXX
   SG_ VehicleType : 0|2@1+ (1,0) [0|3] "" Vector__XXX

BO_ 2566834430 GPM22: 8 Vector__XXX
   SG_ BodyPressure : 48|8@1+ (0.1,0) [0|25] "bar" Vector__XXX
   SG_ BodyFluidLevel : 32|16@1+ (2,0) [0|128510] "L" Vector__XXX
   SG_ ThermalBodyTemperature : 24|8@1+ (1,-125) [-125|125] "deg C" Vector__XXX
   SG_ RearObstacleDistance : 16|8@1+ (2,0) [0|500] "cm" Vector__XXX
   SG_ AntiTheftDeviceStatus : 2|2@1+ (1,0) [0|1] "" Vector__XXX
   SG_ ODDStatus : 0|2@1+ (1,0) [0|1] "" Vector__XXX

BO_ 2365481214 GPM23: 8 Vector__XXX
   SG_ ReqEngineSpeedUpperLim : 16|16@1+ (0.125,0) [0|8031.88] "rpm" Vector__XXX
   SG_ ReqEngineSpeedLowerLim : 32|16@1+ (0.125,0) [0|8031.88] "rpm" Vector__XXX
   SG_ ReqEngineTorqueLimit : 48|8@1+ (1,-125) [-125|125] "%" Vector__XXX
   SG_ ReqEngineSpeedLimit : 56|8@1+ (1,0) [0|250] "km/hr" Vector__XXX
   SG_ ReqEngineSpeed : 0|16@1+ (0.125,0) [0|8031.88] "rpm" Vector__XXX

BO_ 2566808318 GPM24: 8 Vector__XXX
   SG_ SecEngineMtdPTOSwitch : 30|2@1+ (1,0) [0|1] "" Vector__XXX
   SG_ SecClutchDpdtPTOSwitch : 24|2@1+ (1,0) [0|1] "" Vector__XXX
   SG_ FirstClutchDpdtPTOSwitch : 22|2@1+ (1,0) [0|1] "" Vector__XXX
   SG_ OperatingPanelActive : 18|2@1+ (1,0) [0|1] "" Vector__XXX
   SG_ RefusePackerStepSwitch : 16|2@1+ (1,0) [0|1] "" Vector__XXX
   SG_ EngineStopSwitch : 12|2@1+ (1,0) [0|1] "" Vector__XXX
   SG_ EngineStartSwitch : 10|2@1+ (1,0) [0|3] "" Vector__XXX
   SG_ StarterLockoutSwitch : 8|2@1+ (1,0) [0|1] "" Vector__XXX
   SG_ RqstedPercentClutchSlip : 0|8@1+ (0.4,0) [0|100] "%" Vector__XXX
   SG_ FirstEngineMtdPTOSwitch : 28|2@1+ (1,0) [0|1] "" Vector__XXX
   SG_ ClutchIndpdtPTOSwitch : 26|2@1+ (1,0) [0|1] "" Vector__XXX

BO_ 2566808830 GPM25: 8 Vector__XXX
   SG_ TrailerLeftSideMarkerLight : 20|2@1+ (1,0) [0|3] "" Vector__XXX
   SG_ TrailerLeftReversingLight : 16|2@1+ (1,0) [0|3] "" Vector__XXX
   SG_ TrailerLeftRearWidIndLight : 24|2@1+ (1,0) [0|3] "" Vector__XXX
   SG_ TrailerLeftRearRegPltLight : 32|2@1+ (1,0) [0|3] "" Vector__XXX
   SG_ TrailerLeftRearLight : 8|2@1+ (1,0) [0|3] "" Vector__XXX
   SG_ TrailerLeftRearFogLight : 12|2@1+ (1,0) [0|3] "" Vector__XXX
   SG_ TrailerLeftDirIndLight : 4|2@1+ (1,0) [0|3] "" Vector__XXX
   SG_ TrailerLeftCrnMarkerLight : 28|2@1+ (1,0) [0|3] "" Vector__XXX
   SG_ TrailerInteriorLight : 40|2@1+ (1,0) [0|3] "" Vector__XXX
   SG_ TrailerWorkLamp : 42|2@1+ (1,0) [0|3] "" Vector__XXX
   SG_ TrailerRotatingIdentLight : 38|2@1+ (1,0) [0|3] "" Vector__XXX
   SG_ TrailerRightStopLight : 2|2@1+ (1,0) [0|3] "" Vector__XXX
   SG_ TrailerRightSideMrkLight : 22|2@1+ (1,0) [0|3] "" Vector__XXX
   SG_ TrailerRightReversingLight : 18|2@1+ (1,0) [0|3] "" Vector__XXX
   SG_ TrailRightRearWidIndLight : 26|2@1+ (1,0) [0|3] "" Vector__XXX
   SG_ TrailerRightRearRegPltLight : 34|2@1+ (1,0) [0|3] "" Vector__XXX
   SG_ TrailerRightRearLight : 10|2@1+ (1,0) [0|3] "" Vector__XXX
   SG_ TrailerRightRearFogLight : 14|2@1+ (1,0) [0|3] "" Vector__XXX
   SG_ TrailerRightDirIndLight : 6|2@1+ (1,0) [0|3] "" Vector__XXX
   SG_ TrailerRightCrnMarkerLight : 30|2@1+ (1,0) [0|3] "" Vector__XXX
   SG_ TrailerRearWarningLight : 36|2@1+ (1,0) [0|3] "" Vector__XXX
   SG_ TrailerLeftStopLight : 0|2@1+ (1,0) [0|3] "" Vector__XXX

BO_ 2564554494 ISO15765_Funct: 8 Vector__XXX
   SG_ SN m2 : 0|4@1+ (1,0) [0|15] "" Vector__XXX
   SG_ SeparationTime m3 : 16|8@1+ (1,0) [0|255] "ms" Vector__XXX
   SG_ BlockSize m3 : 8|8@1+ (1,0) [0|255] "" Vector__XXX
   SG_ FlowStatus m3 : 0|4@1+ (1,0) [0|3] "" Vector__XXX
   SG_ FirstFrameDataLength m1 : 3|12@0+ (1,0) [0|4095] "Byte" Vector__XXX
   SG_ SingleFrameDataLength m0 : 0|4@1+ (1,0) [0|7] "Byte" Vector__XXX
   SG_ ProtocolCtrlInformation M : 4|4@1+ (1,0) [0|3] "" Vector__XXX

BO_ 2564488958 ISO15765_Phys: 8 Vector__XXX
   SG_ SN m2 : 0|4@1+ (1,0) [0|15] "" Vector__XXX
   SG_ SeparationTime m3 : 16|8@1+ (1,0) [0|255] "ms" Vector__XXX
   SG_ BlockSize m3 : 8|8@1+ (1,0) [0|255] "" Vector__XXX
   SG_ FlowStatus m3 : 0|4@1+ (1,0) [0|3] "" Vector__XXX
   SG_ FirstFrameDataLength m1 : 3|12@0+ (1,0) [0|4095] "Byte" Vector__XXX
   SG_ SingleFrameDataLength m0 : 0|4@1+ (1,0) [0|7] "Byte" Vector__XXX
   SG_ ProtocolCtrlInformation M : 4|4@1+ (1,0) [0|3] "" Vector__XXX

BO_ 2565734142 Network: 8 Vector__XXX
   SG_ ControlByte : 0|8@1+ (1,0) [0|255] "" Vector__XXX
   SG_ FilterMode : 16|8@1+ (1,0) [0|255] "" Vector__XXX
   SG_ ToPort : 8|4@1+ (1,0) [0|15] "" Vector__XXX
   SG_ FromPort : 12|4@1+ (1,0) [0|15] "" Vector__XXX

BO_ 2566896298 AerodynamicControlMsg278: 1 AerodynamicControl

BO_ 2566896298 SteerEngage: 0 Guidance

BA_DEF_ SG_ "SigType" ENUM "Default","Range","RangeSigned","ASCII","Discrete","Control","ReferencePGN","DTC","StringDelimiter","StringLength","StringLengthControl";
BA_DEF_ SG_ "GenSigStartValue" INT 0 10000;
BA_DEF_ SG_ "GenSigSendType" ENUM "Default","Range","RangeSigned","ASCII","Discrete","Control","ReferencePGN","DTC","StringDelimiter","StringLength","StringLengthControl","Default","Range","RangeSigned","ASCII","Discrete","Control","ReferencePGN","DTC","StringDelimiter","StringLength","StringLengthControl","Cyclic","OnWrite","reserved","OnChange","reserved","reserved","reserved","NoSigSendType";
BA_DEF_ SG_ "GenSigILSupport" ENUM "Default","Range","RangeSigned","ASCII","Discrete","Control","ReferencePGN","DTC","StringDelimiter","StringLength","StringLengthControl","Default","Range","RangeSigned","ASCII","Discrete","Control","ReferencePGN","DTC","StringDelimiter","StringLength","StringLengthControl","Cyclic","OnWrite","reserved","OnChange","reserved","reserved","reserved","NoSigSendType","Default","Range","RangeSigned","ASCII","Discrete","Control","ReferencePGN","DTC","StringDelimiter","StringLength","StringLengthControl","Cyclic","OnWrite","reserved","OnChange","reserved","reserved","reserved","NoSigSendType","Yes","No";
BA_DEF_ SG_ "GenSigEVName" STRING ;
BA_DEF_ SG_ "SPN" INT 0 524287;
BA_DEF_ BO_ "GenMsgStartDelayTime" INT 0 100000;
BA_DEF_ BO_ "GenMsgILSupport" ENUM "Default","Range","RangeSigned","ASCII","Discrete","Control","ReferencePGN","DTC","StringDelimiter","StringLength","StringLengthControl","Default","Range","RangeSigned","ASCII","Discrete","Control","ReferencePGN","DTC","StringDelimiter","StringLength","StringLengthControl","Cyclic","OnWrite","reserved","OnChange","reserved","reserved","reserved","NoSigSendType","Default","Range","RangeSigned","ASCII","Discrete","Control","ReferencePGN","DTC","StringDelimiter","StringLength","StringLengthControl","Cyclic","OnWrite","reserved","OnChange","reserved","reserved","reserved","NoSigSendType","Yes","No","Default","Range","RangeSigned","ASCII","Discrete","Control","ReferencePGN","DTC","StringDelimiter","StringLength","StringLengthControl","Cyclic","OnWrite","reserved","OnChange","reserved","reserved","reserved","NoSigSendType","Yes","No","Yes","No";
BA_DEF_ BO_ "GenMsgRequestable" INT 0 1;
BA_DEF_ BO_ "GenMsgSendType" ENUM "Default","Range","RangeSigned","ASCII","Discrete","Control","ReferencePGN","DTC","StringDelimiter","StringLength","StringLengthControl","Default","Range","RangeSigned","ASCII","Discrete","Control","ReferencePGN","DTC","StringDelimiter","StringLength","StringLengthControl","Cyclic","OnWrite","reserved","OnChange","reserved","reserved","reserved","NoSigSendType","Default","Range","RangeSigned","ASCII","Discrete","Control","ReferencePGN","DTC","StringDelimiter","StringLength","StringLengthControl","Cyclic","OnWrite","reserved","OnChange","reserved","reserved","reserved","NoSigSendType","Yes","No","Default","Range","RangeSigned","ASCII","Discrete","Control","ReferencePGN","DTC","StringDelimiter","StringLength","StringLengthControl","Cyclic","OnWrite","reserved","OnChange","reserved","reserved","reserved","NoSigSendType","Yes","No","Yes","No","Default","Range","RangeSigned","ASCII","Discrete","Control","ReferencePGN","DTC","StringDelimiter","StringLength","StringLengthControl","Cyclic","OnWrite","reserved","OnChange","reserved","reserved","reserved","NoSigSendType","Yes","No","Yes","No","cyclic","reserved","cyclicIfActive","reserved","reserved","reserved","reserved","reserved","noMsgSendType";
BA_DEF_ BO_ "VFrameFormat" ENUM "Default","Range","RangeSigned","ASCII","Discrete","Control","ReferencePGN","DTC","StringDelimiter","StringLength","StringLengthControl","Default","Range","RangeSigned","ASCII","Discrete","Control","ReferencePGN","DTC","StringDelimiter","StringLength","StringLengthControl","Cyclic","OnWrite","reserved","OnChange","reserved","reserved","reserved","NoSigSendType","Default","Range","RangeSigned","ASCII","Discrete","Control","ReferencePGN","DTC","StringDelimiter","StringLength","StringLengthControl","Cyclic","OnWrite","reserved","OnChange","reserved","reserved","reserved","NoSigSendType","Yes","No","Default","Range","RangeSigned","ASCII","Discrete","Control","ReferencePGN","DTC","StringDelimiter","StringLength","StringLengthControl","Cyclic","OnWrite","reserved","OnChange","reserved","reserved","reserved","NoSigSendType","Yes","No","Yes","No","Default","Range","RangeSigned","ASCII","Discrete","Control","ReferencePGN","DTC","StringDelimiter","StringLength","StringLengthControl","Cyclic","OnWrite","reserved","OnChange","reserved","reserved","reserved","NoSigSendType","Yes","No","Yes","No","cyclic","reserved","cyclicIfActive","reserved","reserved","reserved","reserved","reserved","noMsgSendType","Default","Range","RangeSigned","ASCII","Discrete","Control","ReferencePGN","DTC","StringDelimiter","StringLength","StringLengthControl","Cyclic","OnWrite","reserved","OnChange","reserved","reserved","reserved","NoSigSendType","Yes","No","Yes","No","cyclic","reserved","cyclicIfActive","reserved","reserved","reserved","reserved","reserved","noMsgSendType","StandardCAN","ExtendedCAN","reserved","J1939PG";
BA_DEF_ BO_ "GenMsgCycleTime" INT 0 3;
BA_DEF_ BU_ "NmStationAddress" INT 0 255;
BA_DEF_ SG_ "SystemSignalLongSymbol" STRING ;
BA_DEF_ BO_ "GenMsgBackgroundColor" STRING ;
BA_DEF_ BO_ "GenMsgForegroundColor" STRING ;
BA_DEF_ BO_ "matchingcriteria" INT 0 0;
BA_DEF_ BO_ "filterlabeling" INT 0 0;
BA_DEF_ BO_ "matchingcriteria" INT 0 0;
BA_DEF_ BO_ "filterlabeling" INT 0 0;
BA_DEF_DEF_ "SigType" "Default";
BA_DEF_DEF_ "GenSigStartValue" 0;
BA_DEF_DEF_ "GenSigSendType" "NoSigSendType";
BA_DEF_DEF_ "GenSigILSupport" "Yes";
BA_DEF_DEF_ "GenSigEVName" "Env";
BA_DEF_DEF_ "SPN" 0;
BA_DEF_DEF_ "GenMsgStartDelayTime" 0;
BA_DEF_DEF_ "GenMsgILSupport" "Yes";
BA_DEF_DEF_ "GenMsgRequestable" 1;
BA_DEF_DEF_ "GenMsgSendType" "noMsgSendType";
BA_DEF_DEF_ "VFrameFormat" "J1939PG";
BA_DEF_DEF_ "GenMsgCycleTime" 0;
BA_DEF_DEF_ "NmStationAddress" 254;
BA_DEF_DEF_ "SystemSignalLongSymbol" "";
BA_DEF_DEF_ "GenMsgBackgroundColor" "#ffffff";
BA_DEF_DEF_ "GenMsgForegroundColor" "#000000";
BA_DEF_DEF_ "matchingcriteria" 1;
BA_DEF_DEF_ "filterlabeling" 0;
BA_DEF_DEF_ "matchingcriteria" 1;
BA_DEF_DEF_ "filterlabeling" 1;
BA_ "GenMsgCycleTime" BO_ 2297441790 10;
BA_ "GenMsgSendType" BO_ 2297441790 0;
BA_ "VFrameFormat" BO_ 2297441790 3;
BA_ "SystemSignalLongSymbol" SG_ 2297441790 SpprtVrblTrnsRpttnRtFrAcclrtnSns "SpprtVrblTrnsRpttnRtFrAcclrtnSns";
BA_ "VFrameFormat" BO_ 2566712062 3;
BA_ "GenMsgCycleTime" BO_ 2364549630 10;
BA_ "GenMsgSendType" BO_ 2364549630 0;
BA_ "VFrameFormat" BO_ 2364549630 3;
BA_ "VFrameFormat" BO_ 2499614462 3;
BA_ "VFrameFormat" BO_ 2560098046 3;
BA_ "VFrameFormat" BO_ 2560163582 3;
BA_ "GenMsgCycleTime" BO_ 2297441534 50;
BA_ "GenMsgSendType" BO_ 2297441534 0;
BA_ "VFrameFormat" BO_ 2297441534 3;
BA_ "GenMsgCycleTime" BO_ 2566722302 500;
BA_ "GenMsgSendType" BO_ 2566722302 0;
BA_ "VFrameFormat" BO_ 2566722302 3;
BA_ "VFrameFormat" BO_ 2566722558 3;
BA_ "VFrameFormat" BO_ 2560032510 3;
BA_ "GenMsgCycleTime" BO_ 2566717950 500;
BA_ "GenMsgSendType" BO_ 2566717950 0;
BA_ "VFrameFormat" BO_ 2566717950 3;
BA_ "GenMsgCycleTime" BO_ 2499604222 200;
BA_ "GenMsgSendType" BO_ 2499604222 0;
BA_ "VFrameFormat" BO_ 2499604222 3;
BA_ "GenMsgCycleTime" BO_ 2358902526 100;
BA_ "GenMsgSendType" BO_ 2358902526 0;
BA_ "VFrameFormat" BO_ 2358902526 3;
BA_ "GenMsgCycleTime" BO_ 2566711550 500;
BA_ "GenMsgSendType" BO_ 2566711550 0;
BA_ "VFrameFormat" BO_ 2566711550 3;
BA_ "VFrameFormat" BO_ 2633832958 3;
BA_ "GenMsgCycleTime" BO_ 2566719998 1000;
BA_ "GenMsgSendType" BO_ 2566719998 0;
BA_ "VFrameFormat" BO_ 2566719998 3;
BA_ "VFrameFormat" BO_ 2565877502 3;
BA_ "GenMsgCycleTime" BO_ 2566713854 100;
BA_ "GenMsgSendType" BO_ 2566713854 0;
BA_ "VFrameFormat" BO_ 2566713854 3;
BA_ "GenMsgCycleTime" BO_ 2566714366 100;
BA_ "GenMsgSendType" BO_ 2566714366 0;
BA_ "VFrameFormat" BO_ 2566714366 3;
BA_ "SystemSignalLongSymbol" SG_ 2566714366 EngTrbCmprssrBypssActtr2OprtnStt "EngTrbCmprssrBypssActtr2OprtnStt";
BA_ "SystemSignalLongSymbol" SG_ 2566714366 EngTrbCmprssrBypssActtr1OprtnStt "EngTrbCmprssrBypssActtr1OprtnStt";
BA_ "SystemSignalLongSymbol" SG_ 2566714366 EngTrbCmprssrBypssActtr2PrlmnryF "EngTrbCmprssrBypssActtr2PrlmnryF";
BA_ "GenMsgCycleTime" BO_ 2566714110 100;
BA_ "GenMsgSendType" BO_ 2566714110 0;
BA_ "VFrameFormat" BO_ 2566714110 3;
BA_ "GenMsgCycleTime" BO_ 2566717438 1000;
BA_ "GenMsgSendType" BO_ 2566717438 0;
BA_ "VFrameFormat" BO_ 2566717438 3;
BA_ "GenMsgCycleTime" BO_ 2633828606 30000;
BA_ "GenMsgSendType" BO_ 2633828606 0;
BA_ "VFrameFormat" BO_ 2633828606 3;
BA_ "VFrameFormat" BO_ 2499607550 3;
BA_ "SystemSignalLongSymbol" SG_ 2499607550 EngExhstMnfldBnk2FlwBlncVlvActtr "EngExhstMnfldBnk2FlwBlncVlvActtr";
BA_ "SystemSignalLongSymbol" SG_ 2499607550 EngExhstMnfldBnk1FlwBlncVlvActtr "EngExhstMnfldBnk1FlwBlncVlvActtr";
BA_ "VFrameFormat" BO_ 2633825534 3;
BA_ "SystemSignalLongSymbol" SG_ 2633825534 EngExhstMnfldBnk2FlwBlncVlv_0000 "EngExhstMnfldBnk2FlwBlncVlv_0000";
BA_ "SystemSignalLongSymbol" SG_ 2633825534 EngExhstMnfldBnk1FlwBlncVlv_0000 "EngExhstMnfldBnk1FlwBlncVlv_0000";
BA_ "VFrameFormat" BO_ 2365400574 3;
BA_ "SystemSignalLongSymbol" SG_ 2365400574 Jystck9ThtAxsCntrClckwsNgtvPsStt "Jystck9ThtAxsCntrClckwsNgtvPsStt";
BA_ "VFrameFormat" BO_ 2365401086 3;
BA_ "SystemSignalLongSymbol" SG_ 2365401086 Jystck8ThtAxsCntrClckwsNgtvPsStt "Jystck8ThtAxsCntrClckwsNgtvPsStt";
BA_ "VFrameFormat" BO_ 2365401598 3;
BA_ "SystemSignalLongSymbol" SG_ 2365401598 Jystck7ThtAxsCntrClckwsNgtvPsStt "Jystck7ThtAxsCntrClckwsNgtvPsStt";
BA_ "VFrameFormat" BO_ 2365402110 3;
BA_ "SystemSignalLongSymbol" SG_ 2365402110 Jystck6ThtAxsCntrClckwsNgtvPsStt "Jystck6ThtAxsCntrClckwsNgtvPsStt";
BA_ "VFrameFormat" BO_ 2365402622 3;
BA_ "SystemSignalLongSymbol" SG_ 2365402622 Jystck5ThtAxsCntrClckwsNgtvPsStt "Jystck5ThtAxsCntrClckwsNgtvPsStt";
BA_ "VFrameFormat" BO_ 2365403134 3;
BA_ "SystemSignalLongSymbol" SG_ 2365403134 Jystck4ThtAxsCntrClckwsNgtvPsStt "Jystck4ThtAxsCntrClckwsNgtvPsStt";
BA_ "VFrameFormat" BO_ 2365400062 3;
BA_ "SystemSignalLongSymbol" SG_ 2365400062 Jystck10ThtAxsCntrClckwsNgtvPsSt "Jystck10ThtAxsCntrClckwsNgtvPsSt";
BA_ "SystemSignalLongSymbol" SG_ 2365400062 Jystck10GrpYAxsLvrFrwrdPstvPsStt "Jystck10GrpYAxsLvrFrwrdPstvPsStt";
BA_ "GenMsgCycleTime" BO_ 2566713598 500;
BA_ "GenMsgSendType" BO_ 2566713598 0;
BA_ "VFrameFormat" BO_ 2566713598 3;
BA_ "GenMsgCycleTime" BO_ 2499604478 500;
BA_ "GenMsgSendType" BO_ 2499604478 0;
BA_ "VFrameFormat" BO_ 2499604478 3;
BA_ "GenMsgCycleTime" BO_ 2499608830 500;
BA_ "GenMsgSendType" BO_ 2499608830 0;
BA_ "VFrameFormat" BO_ 2499608830 3;
BA_ "GenMsgCycleTime" BO_ 2432499198 100;
BA_ "GenMsgSendType" BO_ 2432499198 0;
BA_ "VFrameFormat" BO_ 2432499198 3;
BA_ "VFrameFormat" BO_ 2633825022 3;
BA_ "VFrameFormat" BO_ 2633826046 3;
BA_ "SystemSignalLongSymbol" SG_ 2633826046 EngExhstGsRcrcltn2ClrIntkGsAbsPr "EngExhstGsRcrcltn2ClrIntkGsAbsPr";
BA_ "VFrameFormat" BO_ 2566711294 3;
BA_ "VFrameFormat" BO_ 2566749438 3;
BA_ "SystemSignalLongSymbol" SG_ 2566749438 DslPrtcltFltrAtmtcActvRgnrtnIntt "DslPrtcltFltrAtmtcActvRgnrtnIntt";
BA_ "SystemSignalLongSymbol" SG_ 2566749438 DslPrtcltFltrActvRgnrtnInhbtdDTV "DslPrtcltFltrActvRgnrtnInhbtdDTV";
BA_ "SystemSignalLongSymbol" SG_ 2566749438 DslPrtcltFltrActvRgnrtnInhbtdDTE "DslPrtcltFltrActvRgnrtnInhbtdDTE";
BA_ "SystemSignalLongSymbol" SG_ 2566749438 DslPrtcltFltrActvRgnrtnInhbtdDTP "DslPrtcltFltrActvRgnrtnInhbtdDTP";
BA_ "SystemSignalLongSymbol" SG_ 2566749438 DslPrtcltFltrActvRgnrtnInhbtdDTT "DslPrtcltFltrActvRgnrtnInhbtdDTT";
BA_ "SystemSignalLongSymbol" SG_ 2566749438 DslPrtcltFltrActvRgnrtnInhbtdDTS "DslPrtcltFltrActvRgnrtnInhbtdDTS";
BA_ "SystemSignalLongSymbol" SG_ 2566749438 DslPrtcltFltrActvRgnrtnInhb_0000 "DslPrtcltFltrActvRgnrtnInhb_0000";
BA_ "SystemSignalLongSymbol" SG_ 2566749438 DslPrtcltFltrActvRgnrtnInhbtdDTL "DslPrtcltFltrActvRgnrtnInhbtdDTL";
BA_ "SystemSignalLongSymbol" SG_ 2566749438 DslPrtcltFltrActvRgnrtnInhb_0001 "DslPrtcltFltrActvRgnrtnInhb_0001";
BA_ "SystemSignalLongSymbol" SG_ 2566749438 DslPrtcltFltrActvRgnrtnInhb_0002 "DslPrtcltFltrActvRgnrtnInhb_0002";
BA_ "SystemSignalLongSymbol" SG_ 2566749438 DslPrtcltFltrActvRgnrtnInhbtdDTO "DslPrtcltFltrActvRgnrtnInhbtdDTO";
BA_ "SystemSignalLongSymbol" SG_ 2566749438 DslPrtcltFltrActvRgnrtnInhbtdDTA "DslPrtcltFltrActvRgnrtnInhbtdDTA";
BA_ "SystemSignalLongSymbol" SG_ 2566749438 DslPrtcltFltrActvRgnrtnInhb_0003 "DslPrtcltFltrActvRgnrtnInhb_0003";
BA_ "SystemSignalLongSymbol" SG_ 2566749438 DslPrtcltFltrActvRgnrtnInhb_0004 "DslPrtcltFltrActvRgnrtnInhb_0004";
BA_ "SystemSignalLongSymbol" SG_ 2566749438 DslPrtcltFltrActvRgnrtnInhbtdDTC "DslPrtcltFltrActvRgnrtnInhbtdDTC";
BA_ "SystemSignalLongSymbol" SG_ 2566749438 DslPrtcltFltrActvRgnrtnInhbtdDTI "DslPrtcltFltrActvRgnrtnInhbtdDTI";
BA_ "SystemSignalLongSymbol" SG_ 2566749438 DslPrtcltFltrActvRgnrtnInhbtdStt "DslPrtcltFltrActvRgnrtnInhbtdStt";
BA_ "GenMsgCycleTime" BO_ 2566715646 1000;
BA_ "GenMsgSendType" BO_ 2566715646 0;
BA_ "VFrameFormat" BO_ 2566715646 3;
BA_ "GenMsgCycleTime" BO_ 2566724606 1000;
BA_ "GenMsgSendType" BO_ 2566724606 0;
BA_ "VFrameFormat" BO_ 2566724606 3;
BA_ "GenMsgCycleTime" BO_ 2566715902 1000;
BA_ "GenMsgSendType" BO_ 2566715902 0;
BA_ "VFrameFormat" BO_ 2566715902 3;
BA_ "GenMsgCycleTime" BO_ 2566724862 1000;
BA_ "GenMsgSendType" BO_ 2566724862 0;
BA_ "VFrameFormat" BO_ 2566724862 3;
BA_ "GenMsgCycleTime" BO_ 2566718718 1000;
BA_ "GenMsgSendType" BO_ 2566718718 0;
BA_ "VFrameFormat" BO_ 2566718718 3;
BA_ "GenMsgCycleTime" BO_ 2566718974 1000;
BA_ "GenMsgSendType" BO_ 2566718974 0;
BA_ "VFrameFormat" BO_ 2566718974 3;
BA_ "VFrameFormat" BO_ 2566719230 3;
BA_ "VFrameFormat" BO_ 2560818942 3;
BA_ "VFrameFormat" BO_ 2561212158 3;
BA_ "GenMsgCycleTime" BO_ 2566746366 1000;
BA_ "VFrameFormat" BO_ 2566746366 3;
BA_ "VFrameFormat" BO_ 2566750206 3;
BA_ "GenMsgCycleTime" BO_ 2566755582 100;
BA_ "GenMsgSendType" BO_ 2566755582 0;
BA_ "VFrameFormat" BO_ 2566755582 3;
BA_ "VFrameFormat" BO_ 2566746110 3;
BA_ "SystemSignalLongSymbol" SG_ 2566746110 EngExhstGsRcrcltn1ClrIntkGsAbsPr "EngExhstGsRcrcltn1ClrIntkGsAbsPr";
BA_ "GenMsgCycleTime" BO_ 2566752510 500;
BA_ "GenMsgSendType" BO_ 2566752510 0;
BA_ "VFrameFormat" BO_ 2566752510 3;
BA_ "GenMsgCycleTime" BO_ 2566752254 500;
BA_ "GenMsgSendType" BO_ 2566752254 0;
BA_ "VFrameFormat" BO_ 2566752254 3;
BA_ "GenMsgCycleTime" BO_ 2566751998 500;
BA_ "GenMsgSendType" BO_ 2566751998 0;
BA_ "VFrameFormat" BO_ 2566751998 3;
BA_ "GenMsgCycleTime" BO_ 2566751742 500;
BA_ "GenMsgSendType" BO_ 2566751742 0;
BA_ "VFrameFormat" BO_ 2566751742 3;
BA_ "GenMsgCycleTime" BO_ 2566751486 500;
BA_ "GenMsgSendType" BO_ 2566751486 0;
BA_ "VFrameFormat" BO_ 2566751486 3;
BA_ "GenMsgCycleTime" BO_ 2499641854 500;
BA_ "GenMsgSendType" BO_ 2499641854 0;
BA_ "VFrameFormat" BO_ 2499641854 3;
BA_ "VFrameFormat" BO_ 2566748158 3;
BA_ "VFrameFormat" BO_ 2566747902 3;
BA_ "VFrameFormat" BO_ 2566747646 3;
BA_ "VFrameFormat" BO_ 2566747390 3;
BA_ "VFrameFormat" BO_ 2566747134 3;
BA_ "VFrameFormat" BO_ 2566746878 3;
BA_ "VFrameFormat" BO_ 2561277694 3;
BA_ "VFrameFormat" BO_ 2633861886 3;
BA_ "GenMsgCycleTime" BO_ 2565873150 10;
BA_ "GenMsgSendType" BO_ 2565873150 0;
BA_ "VFrameFormat" BO_ 2565873150 3;
BA_ "VFrameFormat" BO_ 2566745854 3;
BA_ "SystemSignalLongSymbol" SG_ 2566745854 Aftrtrtmnt1SCRCtlystCnvrsnEffcnc "Aftrtrtmnt1SCRCtlystCnvrsnEffcnc";
BA_ "SystemSignalLongSymbol" SG_ 2566745854 Aftrtrtmnt1SCRCmddCtlystRgntCnsm "Aftrtrtmnt1SCRCmddCtlystRgntCnsm";
BA_ "SystemSignalLongSymbol" SG_ 2566745854 Aftrtrtmnt1SCRAvrgCtlystRgntCnsm "Aftrtrtmnt1SCRAvrgCtlystRgntCnsm";
BA_ "SystemSignalLongSymbol" SG_ 2566745854 Aftrtrtmnt1DslExhstFldTnkLwLvlIn "Aftrtrtmnt1DslExhstFldTnkLwLvlIn";
BA_ "GenMsgCycleTime" BO_ 2566751230 1000;
BA_ "GenMsgSendType" BO_ 2566751230 0;
BA_ "VFrameFormat" BO_ 2566751230 3;
BA_ "GenMsgCycleTime" BO_ 2566755838 1000;
BA_ "GenMsgSendType" BO_ 2566755838 0;
BA_ "VFrameFormat" BO_ 2566755838 3;
BA_ "VFrameFormat" BO_ 2566752766 3;
BA_ "GenMsgSendType" BO_ 2633938942 8;
BA_ "VFrameFormat" BO_ 2633938942 3;
BA_ "GenMsgSendType" BO_ 2566799614 8;
BA_ "VFrameFormat" BO_ 2566799614 3;
BA_ "GenMsgSendType" BO_ 2365473278 8;
BA_ "VFrameFormat" BO_ 2365473278 3;
BA_ "GenMsgCycleTime" BO_ 2365485822 50;
BA_ "GenMsgSendType" BO_ 2365485822 0;
BA_ "VFrameFormat" BO_ 2365485822 3;
BA_ "GenMsgSendType" BO_ 2633926654 8;
BA_ "VFrameFormat" BO_ 2633926654 3;
BA_ "GenMsgSendType" BO_ 2633926398 8;
BA_ "VFrameFormat" BO_ 2633926398 3;
BA_ "GenMsgSendType" BO_ 2633926142 8;
BA_ "VFrameFormat" BO_ 2633926142 3;
BA_ "GenMsgSendType" BO_ 2633925886 8;
BA_ "VFrameFormat" BO_ 2633925886 3;
BA_ "GenMsgSendType" BO_ 2633925630 8;
BA_ "VFrameFormat" BO_ 2633925630 3;
BA_ "GenMsgSendType" BO_ 2633925374 8;
BA_ "VFrameFormat" BO_ 2633925374 3;
BA_ "GenMsgSendType" BO_ 2633927422 8;
BA_ "VFrameFormat" BO_ 2633927422 3;
BA_ "GenMsgSendType" BO_ 2633927166 8;
BA_ "VFrameFormat" BO_ 2633927166 3;
BA_ "GenMsgSendType" BO_ 2633926910 8;
BA_ "VFrameFormat" BO_ 2633926910 3;
BA_ "GenMsgCycleTime" BO_ 2566768894 1000;
BA_ "GenMsgSendType" BO_ 2566768894 0;
BA_ "VFrameFormat" BO_ 2566768894 3;
BA_ "GenMsgCycleTime" BO_ 2566769406 1000;
BA_ "GenMsgSendType" BO_ 2566769406 0;
BA_ "VFrameFormat" BO_ 2566769406 3;
BA_ "GenMsgSendType" BO_ 2566839550 8;
BA_ "VFrameFormat" BO_ 2566839550 3;
BA_ "GenMsgCycleTime" BO_ 2633934334 1000;
BA_ "GenMsgSendType" BO_ 2633934334 0;
BA_ "VFrameFormat" BO_ 2633934334 3;
BA_ "GenMsgCycleTime" BO_ 2566825726 500;
BA_ "GenMsgSendType" BO_ 2566825726 0;
BA_ "VFrameFormat" BO_ 2566825726 3;
BA_ "GenMsgCycleTime" BO_ 2566770942 500;
BA_ "GenMsgSendType" BO_ 2566770942 0;
BA_ "VFrameFormat" BO_ 2566770942 3;
BA_ "GenMsgCycleTime" BO_ 2566846206 500;
BA_ "GenMsgSendType" BO_ 2566846206 0;
BA_ "VFrameFormat" BO_ 2566846206 3;
BA_ "GenMsgCycleTime" BO_ 2566811134 1000;
BA_ "GenMsgSendType" BO_ 2566811134 0;
BA_ "VFrameFormat" BO_ 2566811134 3;
BA_ "GenMsgCycleTime" BO_ 2298375934 20;
BA_ "GenMsgSendType" BO_ 2298375934 0;
BA_ "VFrameFormat" BO_ 2298375934 3;
BA_ "GenMsgCycleTime" BO_ 2565867774 50;
BA_ "GenMsgSendType" BO_ 2565867774 0;
BA_ "VFrameFormat" BO_ 2565867774 3;
BA_ "GenMsgSendType" BO_ 2566841854 8;
BA_ "VFrameFormat" BO_ 2566841854 3;
BA_ "GenMsgCycleTime" BO_ 2365449982 100;
BA_ "GenMsgSendType" BO_ 2365449982 0;
BA_ "VFrameFormat" BO_ 2365449982 3;
BA_ "GenMsgSendType" BO_ 2633939198 8;
BA_ "VFrameFormat" BO_ 2633939198 3;
BA_ "GenMsgSendType" BO_ 2633927678 8;
BA_ "VFrameFormat" BO_ 2633927678 3;
BA_ "GenMsgSendType" BO_ 2633925118 8;
BA_ "VFrameFormat" BO_ 2633925118 3;
BA_ "GenMsgSendType" BO_ 2633937662 8;
BA_ "VFrameFormat" BO_ 2633937662 3;
BA_ "GenMsgSendType" BO_ 2566804990 8;
BA_ "VFrameFormat" BO_ 2566804990 3;
BA_ "GenMsgSendType" BO_ 2633936894 8;
BA_ "VFrameFormat" BO_ 2633936894 3;
BA_ "GenMsgCycleTime" BO_ 2566757630 1000;
BA_ "GenMsgSendType" BO_ 2566757630 0;
BA_ "VFrameFormat" BO_ 2566757630 3;
BA_ "GenMsgCycleTime" BO_ 2566757886 1000;
BA_ "GenMsgSendType" BO_ 2566757886 0;
BA_ "VFrameFormat" BO_ 2566757886 3;
BA_ "GenMsgCycleTime" BO_ 2566759678 100;
BA_ "GenMsgSendType" BO_ 2566759678 0;
BA_ "VFrameFormat" BO_ 2566759678 3;
BA_ "GenMsgCycleTime" BO_ 2432541438 500;
BA_ "GenMsgSendType" BO_ 2432541438 0;
BA_ "VFrameFormat" BO_ 2432541438 3;
BA_ "GenMsgCycleTime" BO_ 2566761214 500;
BA_ "GenMsgSendType" BO_ 2566761214 0;
BA_ "VFrameFormat" BO_ 2566761214 3;
BA_ "GenMsgCycleTime" BO_ 2432541694 100;
BA_ "GenMsgSendType" BO_ 2432541694 0;
BA_ "VFrameFormat" BO_ 2432541694 3;
BA_ "SystemSignalLongSymbol" SG_ 2432541694 EngTrbCmprssrBypssActtr1PrlmnryF "EngTrbCmprssrBypssActtr1PrlmnryF";
BA_ "GenMsgCycleTime" BO_ 2566759934 100;
BA_ "GenMsgSendType" BO_ 2566759934 0;
BA_ "VFrameFormat" BO_ 2566759934 3;
BA_ "GenMsgCycleTime" BO_ 2566757374 1000;
BA_ "GenMsgSendType" BO_ 2566757374 0;
BA_ "VFrameFormat" BO_ 2566757374 3;
BA_ "SystemSignalLongSymbol" SG_ 2566757374 Aftrtrtmnt1SCRCtlystRgntTmp2Prlm "Aftrtrtmnt1SCRCtlystRgntTmp2Prlm";
BA_ "SystemSignalLongSymbol" SG_ 2566757374 Aftrtrtmnt1SCRCtlystRgntPrprtsPr "Aftrtrtmnt1SCRCtlystRgntPrprtsPr";
BA_ "GenMsgCycleTime" BO_ 2364546302 100;
BA_ "GenMsgSendType" BO_ 2364546302 0;
BA_ "VFrameFormat" BO_ 2364546302 3;
BA_ "GenMsgCycleTime" BO_ 2431654654 50;
BA_ "GenMsgSendType" BO_ 2431654654 0;
BA_ "VFrameFormat" BO_ 2431654654 3;
BA_ "GenMsgCycleTime" BO_ 2364545534 5000;
BA_ "GenMsgSendType" BO_ 2364545534 0;
BA_ "VFrameFormat" BO_ 2364545534 3;
BA_ "GenMsgCycleTime" BO_ 2364545278 5000;
BA_ "GenMsgSendType" BO_ 2364545278 0;
BA_ "VFrameFormat" BO_ 2364545278 3;
BA_ "GenMsgCycleTime" BO_ 2364545022 5000;
BA_ "GenMsgSendType" BO_ 2364545022 0;
BA_ "VFrameFormat" BO_ 2364545022 3;
BA_ "GenMsgCycleTime" BO_ 2364544766 5000;
BA_ "GenMsgSendType" BO_ 2364544766 0;
BA_ "VFrameFormat" BO_ 2364544766 3;
BA_ "GenMsgCycleTime" BO_ 2364544510 100;
BA_ "GenMsgSendType" BO_ 2364544510 0;
BA_ "VFrameFormat" BO_ 2364544510 3;
BA_ "GenMsgCycleTime" BO_ 2364544254 50;
BA_ "GenMsgSendType" BO_ 2364544254 0;
BA_ "VFrameFormat" BO_ 2364544254 3;
BA_ "SystemSignalLongSymbol" SG_ 2364544254 RltvBldHghtAndBldRttnAnglMsrmntL "RltvBldHghtAndBldRttnAnglMsrmntL";
BA_ "GenMsgCycleTime" BO_ 2349006590 10;
BA_ "GenMsgSendType" BO_ 2349006590 0;
BA_ "VFrameFormat" BO_ 2349006590 3;
BA_ "GenMsgCycleTime" BO_ 2566834686 100;
BA_ "GenMsgSendType" BO_ 2566834686 0;
BA_ "VFrameFormat" BO_ 2566834686 3;
BA_ "GenMsgCycleTime" BO_ 2550398718 10;
BA_ "GenMsgSendType" BO_ 2550398718 0;
BA_ "VFrameFormat" BO_ 2550398718 3;
BA_ "GenMsgCycleTime" BO_ 2566833406 100;
BA_ "GenMsgSendType" BO_ 2566833406 0;
BA_ "VFrameFormat" BO_ 2566833406 3;
BA_ "GenMsgCycleTime" BO_ 2365507326 100;
BA_ "GenMsgSendType" BO_ 2365507326 0;
BA_ "VFrameFormat" BO_ 2365507326 3;
BA_ "GenMsgCycleTime" BO_ 2565013246 100;
BA_ "GenMsgSendType" BO_ 2565013246 0;
BA_ "VFrameFormat" BO_ 2565013246 3;
BA_ "GenMsgCycleTime" BO_ 2566807038 500;
BA_ "GenMsgSendType" BO_ 2566807038 0;
BA_ "VFrameFormat" BO_ 2566807038 3;
BA_ "GenMsgCycleTime" BO_ 2365480958 50;
BA_ "GenMsgSendType" BO_ 2365480958 0;
BA_ "VFrameFormat" BO_ 2365480958 3;
BA_ "GenMsgCycleTime" BO_ 2566808062 100;
BA_ "GenMsgSendType" BO_ 2566808062 0;
BA_ "VFrameFormat" BO_ 2566808062 3;
BA_ "GenMsgCycleTime" BO_ 2566808574 1000;
BA_ "GenMsgSendType" BO_ 2566808574 0;
BA_ "VFrameFormat" BO_ 2566808574 3;
BA_ "GenMsgCycleTime" BO_ 2566809086 100;
BA_ "GenMsgSendType" BO_ 2566809086 0;
BA_ "VFrameFormat" BO_ 2566809086 3;
BA_ "GenMsgCycleTime" BO_ 2564947710 100;
BA_ "GenMsgSendType" BO_ 2564947710 0;
BA_ "VFrameFormat" BO_ 2564947710 3;
BA_ "GenMsgCycleTime" BO_ 2566834430 100;
BA_ "GenMsgSendType" BO_ 2566834430 0;
BA_ "VFrameFormat" BO_ 2566834430 3;
BA_ "GenMsgCycleTime" BO_ 2365481214 100;
BA_ "GenMsgSendType" BO_ 2365481214 0;
BA_ "VFrameFormat" BO_ 2365481214 3;
BA_ "GenMsgCycleTime" BO_ 2566808318 100;
BA_ "GenMsgSendType" BO_ 2566808318 0;
BA_ "VFrameFormat" BO_ 2566808318 3;
BA_ "GenMsgCycleTime" BO_ 2566808830 100;
BA_ "GenMsgSendType" BO_ 2566808830 0;
BA_ "VFrameFormat" BO_ 2566808830 3;
BA_ "GenMsgSendType" BO_ 2564554494 8;
BA_ "VFrameFormat" BO_ 2564554494 3;
BA_ "GenMsgSendType" BO_ 2564488958 8;
BA_ "VFrameFormat" BO_ 2564488958 3;
BA_ "GenMsgSendType" BO_ 2565734142 8;
BA_ "VFrameFormat" BO_ 2565734142 3;
VAL_ 2566896298 TirePressThresholdDetection 7 "NotAvailable" 6 "ErrorIndicator" 5 "NotDefined" 4 "ExtrmUndrPrssTrPrssrIsAtALvlWhr" 3 "UndrPrssTrPrssrIsLwrThnThPrssrD" 2 "NWrnngPrssTrPrssrIsWthnThThrshl" 1 "OvrPrssTrPrssrIsHghrThnThPrssrD" 0 "ExtrmOvrPrssTrPrssrIsAtALvlWhrT";
VAL_ 2566896298 CTIWheelEndElectricalFault 3 "NotSupported" 2 "Error" 1 "NotDefined" 0 "Ok";
VAL_ 2566896298 CTITireStatus 3 "NotSupported" 2 "Error" 1 "TireLeakDetected" 0 "Ok";
VAL_ 2566896298 CTIWheelSensorStatus 3 "NotSupported" 2 "NotDefined" 1 "On" 0 "Off_IsolatedFromCTIPressCtrl";
VAL_ 2566896298 SteerEngaged 0 "Steer_Disabled" 1 "Steer_Enabled" 0 "No Description";
VAL_ 2566896298 SteerEngage 0 "Disabled" 1 "Enabled";
VAL_ 2297441790 SpprtVrblTrnsRpttnRtFrAcclrtnSns 1 "MsTransRate";
VAL_ 2297441790 VrtclAcclrtnExRngeFigureOfMerit 3 "NotAvailable" 2 "Error" 1 "VrtclcclrtnIsDgrddDtIsSspctDTEn" 0 "VrtclAcclrtnIsFllyFnctnlDtIsWth";
VAL_ 2297441790 LngtdnlAcclrtnExRngFgureOfMerit 3 "NotAvailable" 2 "Error" 1 "LngtdnlAcclrtnIsDgrddDtIsSspctD" 0 "LngtdnlAcclrtnIsFllyFnctnlDtIsW";
VAL_ 2297441790 LtrlAcclrtnExRangeFigureOfMerit 3 "NotAvailable" 2 "Error" 1 "LtrlAcclrtnIsDgrddDtIsSspctDTEn" 0 "LtrlAcclrtnIsFllyFnctnlDtIsWthn";
VAL_ 2364549630 RollAngleExRangeFigureOfMerit 3 "NotAvailable" 2 "Error" 1 "RllRtDgrddDtIsSspctDTEnvrnmntlC" 0 "RllRtFllyFnctnlDtIsWthnSnsrSpcf";
VAL_ 2364549630 RollAngleExRangeCompensation 3 "NotAvailable" 2 "Error" 1 "Off" 0 "On";
VAL_ 2364549630 PitchAngleExRangeFigureOfMerit 3 "NotAvailable" 2 "Error" 1 "PtchRtDgrddDtIsSspctDTEnvrnmntl" 0 "PtchRtFllyFnctnlDtIsWthnSnsrSpc";
VAL_ 2364549630 PitchAngleExRangeCompensation 3 "NotAvailable" 2 "Error" 1 "Off" 0 "On";
VAL_ 2499614462 OccpntClssfcationSystem10Status 3 "NotAvailable" 2 "ErrrClssfctonCannotBeDetermined" 1 "Occupied" 0 "Empty";
VAL_ 2499614462 OccpntClssficationSystem9Status 3 "NotAvailable" 2 "ErrrClssfctonCannotBeDetermined" 1 "Occupied" 0 "Empty";
VAL_ 2499614462 OccpntClssficationSystem8Status 3 "NotAvailable" 2 "ErrrClssfctonCannotBeDetermined" 1 "Occupied" 0 "Empty";
VAL_ 2499614462 OccpntClssficationSystem7Status 3 "NotAvailable" 2 "ErrrClssfctonCannotBeDetermined" 1 "Occupied" 0 "Empty";
VAL_ 2499614462 OccpntClssficationSystem6Status 3 "NotAvailable" 2 "ErrrClssfctonCannotBeDetermined" 1 "Occupied" 0 "Empty";
VAL_ 2499614462 OccpntClssficationSystem5Status 3 "NotAvailable" 2 "ErrrClssfctonCannotBeDetermined" 1 "Occupied" 0 "Empty";
VAL_ 2499614462 OccpntClssficationSystem4Status 3 "NotAvailable" 2 "ErrrClssfctonCannotBeDetermined" 1 "Occupied" 0 "Empty";
VAL_ 2499614462 OccpntClssficationSystem3Status 3 "NotAvailable" 2 "ErrrClssfctonCannotBeDetermined" 1 "Occupied" 0 "Empty";
VAL_ 2499614462 PssngrOccpntClssfctnSystmStatus 7 "NotAvailable" 5 "ErrrClssfctnOfOccpntCnntBDtrmnd" 3 "Adult" 4 "LargeAdult" 2 "SmallAdult" 1 "Child" 0 "Empty";
VAL_ 2499614462 DrvrOccpntClssfctonSystemStatus 7 "NotAvailable" 6 "ErrrClssfctnOfOccpntCnntBDtrmnd" 5 "Reserved" 4 "LargeAdult" 3 "Adult" 2 "SmallAdult" 1 "Child" 0 "Empty";
VAL_ 2560098046 CabNoiseCtrlTuningStatus 15 "NotAvailable_NotTuning_NotRqed" 14 "TuningModeError" 10 "AutomaticTuningModeSavingData" 9 "AutomaticTuningModeCmdComplete" 8 "AutomaticTuningMode" 7 "MnlTnngDndRqrsScrtyVerification" 13 "Reserved" 2 "ManualTuningModeSavingData" 1 "ManualTuningModeCmdComplete" 0 "ManualTuningMode";
VAL_ 2560098046 CabNoiseCtrlStatus 3 "NotAvailable_NotRqed" 2 "ErrorIndicator" 1 "CabNoiseCtrlSystemOFFLine" 0 "CabNoiseCtrlSystemONLine";
VAL_ 2560163582 CabNoiseCtrlTuningState 7 "DontCareNOTCmded" 6 "Reserved" 5 "ExitTuningSavingParameters" 4 "ExitTuningNotSavingParameters" 3 "RmnInTningSaveCurrentParameters" 2 "ActvtAtmtcTnngSttSvngPrmtrsExtO" 1 "ActvtAtmtcTnngWtFrSvAndExitCmds" 0 "ActvtMnlTnngWtFrSaveAndExitCmds";
VAL_ 2560163582 CabNoiseCtrlState 3 "DontCare_NotCmded" 2 "Reserved" 1 "BringCabNoiseCtrlSystemOnLine" 0 "TakeCabNoiseCtrlSystemOffLine";
VAL_ 2297441534 DropRelayCtrl 3 "TakeNoAction" 2 "Reserved" 1 "OnEnableDropRelayRq" 0 "OffDisableDropRelayRq";
VAL_ 2297441534 LiftRelayCtrl 3 "TakeNoAction" 2 "Reserved" 1 "OnEnableLiftRelayRq" 0 "OffDisableLiftRelayRq";
VAL_ 2297441534 MaterialDropActiveStatus 3 "NotAvailable" 2 "Error" 1 "On" 0 "Off";
VAL_ 2297441534 MaterialLiftActiveStatus 3 "NotAvailable" 2 "Error" 1 "On" 0 "Off";
VAL_ 2297441534 GnratorCurrentBoostActiveStatus 3 "NotAvailable" 2 "Error" 1 "On" 0 "Off";
VAL_ 2297441534 MaterialDropSwitch 3 "NotAvailable" 2 "Error" 1 "Drop" 0 "DontDrop";
VAL_ 2297441534 MaterialLiftSwitch 3 "NotAvailable" 2 "Error" 1 "Lift" 0 "DontLift";
VAL_ 2566722302 GneratorDutyCycleExceededStatus 3 "NotAvaiable" 2 "Error" 1 "DutyCycleExceed" 0 "DutyCycleNotExceed";
VAL_ 2566722302 VoltageMonitorActiveStatus 3 "NotAvailable" 2 "Error" 1 "MonitorIsOn" 0 "MonitorIsOff";
VAL_ 2566722302 GensetEnableActiveStatus 3 "NotAvaialble" 2 "Error" 1 "Enabled" 0 "NotEnabled";
VAL_ 2566722302 ReverseCurrentRangeSetting 31 "NotAvailable" 30 "Error" 16 "11101NotUsed" 15 "16" 14 "15" 13 "14" 12 "13" 11 "12" 10 "11" 9 "10" 8 "9" 7 "8" 6 "7" 5 "6" 4 "5" 3 "4" 2 "3" 1 "2" 0 "1";
VAL_ 2566722302 GensetSoftstartActiveStatus 3 "NotAvailable" 2 "Error" 1 "On" 0 "Off";
VAL_ 2566722302 Grapple_MagnetSelectionSwitch 3 "NotAvailable" 2 "Error" 1 "MagnetSelected" 0 "GrappleSelected";
VAL_ 2566722302 GnstSystmOtptVoltageRangeStatus 3 "NotAvailable" 2 "Error" 1 "InRange" 0 "OutOfRange";
VAL_ 2566722302 GeneratorOverheatStatus 3 "NotAvailable" 2 "Error" 1 "Overheat" 0 "NotOverheat";
VAL_ 2560032510 LwVltgDscnnctDsredOperatingMode 15 "NoChange" 6 "1110Reserved" 5 "ManualConnect" 4 "ManualDisconnect" 1 "0011Reserved" 0 "Automatic";
VAL_ 2566717950 LwVltgDisconnectVoutOutputState 15 "NotAvailableNotInstalled" 14 "OutputFault" 5 "1101Reserved" 4 "ConnectPendingAlarmActive" 3 "DisconnectPendingAlarmActive" 2 "DscnnctAlrmExprdOtptOffDscnnctd" 1 "OutputOnConnected" 0 "OutputOffDisconnected";
VAL_ 2566717950 LwVoltageDisconnectOutput1State 15 "NotAvailableNotInstalled" 14 "OutputFault" 5 "1101Reserved" 4 "ConnectPendingAlarmActive" 3 "DisconnectPendingAlarmActive" 2 "DscnnctAlrmExprdOtptOffDscnnctd" 1 "OutputOnConnected" 0 "OutputOffDisconnected";
VAL_ 2566717950 LwVoltageDisconnectOutput2State 15 "NotAvailableNotInstalled" 14 "OutputFault" 5 "1101Reserved" 4 "ConnectPendingAlarmActive" 3 "DisconnectPendingAlarmActive" 2 "DscnnctAlrmExprdOtptOffDscnnctd" 1 "OutputOnConnected" 0 "OutputOffDisconnected";
VAL_ 2566717950 LwVoltageDisconnectOutput3State 15 "NotAvailableNotInstalled" 14 "OutputFault" 5 "1101Reserved" 4 "ConnectPendingAlarmActive" 3 "DisconnectPendingAlarmActive" 2 "DscnnctAlrmExprdOtptOffDscnnctd" 1 "OutputOnConnected" 0 "OutputOffDisconnected";
VAL_ 2566717950 LwVltgDscnnctCrrntOperatingMode 15 "NotAvailable" 10 "1110Reserved" 9 "ManualConnectViaHardwiredInput" 8 "MnalDisconnectViaHardwiredInput" 6 "0111Reserved" 5 "ManualConnectViaJ1939Rq" 4 "ManualDisconnectViaJ1939Rq" 1 "0011Reserved" 0 "Automatic";
VAL_ 2566717950 LwVltgDscnnctManualConnectState 3 "NotInstalled" 2 "Error" 1 "InputOn" 0 "InputOff";
VAL_ 2566717950 LwVltgDscnnctMnlDisconnectState 3 "NotInstalled" 2 "Error" 1 "InputOn" 0 "InputOff";
VAL_ 2358902526 Joystick3Lamp10Cmd 3 "NotAvailableNotInstalled" 2 "Blinking" 1 "On" 0 "Off";
VAL_ 2358902526 Joystick3Lamp9Cmd 3 "NotAvailableNotInstalled" 2 "Blinking" 1 "On" 0 "Off";
VAL_ 2358902526 Joystick3Lamp8Cmd 3 "NotAvailableNotInstalled" 2 "Blinking" 1 "On" 0 "Off";
VAL_ 2358902526 Joystick3Lamp7Cmd 3 "NotAvailableNotInstalled" 2 "Blinking" 1 "On" 0 "Off";
VAL_ 2358902526 Joystick3Lamp6Cmd 3 "NotAvailableNotInstalled" 2 "Blinking" 1 "On" 0 "Off";
VAL_ 2358902526 Joystick3Lamp5Cmd 3 "NotAvailableNotInstalled" 2 "Blinking" 1 "On" 0 "Off";
VAL_ 2358902526 Joystick3Lamp4Cmd 3 "NotAvailableNotInstalled" 2 "Blinking" 1 "On" 0 "Off";
VAL_ 2358902526 Joystick3Lamp3Cmd 3 "NotAvailableNotInstalled" 2 "Blinking" 1 "On" 0 "Off";
VAL_ 2358902526 Joystick3Lamp2Cmd 3 "NotAvailableNotInstalled" 2 "Blinking" 1 "On" 0 "Off";
VAL_ 2358902526 Joystick3Lamp1Cmd 3 "NotAvailableNotInstalled" 2 "Blinking" 1 "On" 0 "Off";
VAL_ 2358902526 Joystick2Lamp10Cmd 3 "NotAvailableNotInstalled" 2 "Blinking" 1 "On" 0 "Off";
VAL_ 2358902526 Joystick2Lamp9Cmd 3 "NotAvailableNotInstalled" 2 "Blinking" 1 "On" 0 "Off";
VAL_ 2358902526 Joystick2Lamp8Cmd 3 "NotAvailableNotInstalled" 2 "Blinking" 1 "On" 0 "Off";
VAL_ 2358902526 Joystick2Lamp7Cmd 3 "NotAvailableNotInstalled" 2 "Blinking" 1 "On" 0 "Off";
VAL_ 2358902526 Joystick2Lamp6Cmd 3 "NotAvailableNotInstalled" 2 "Blinking" 1 "On" 0 "Off";
VAL_ 2358902526 Joystick2Lamp5Cmd 3 "NotAvailableNotInstalled" 2 "Blinking" 1 "On" 0 "Off";
VAL_ 2358902526 Joystick2Lamp4Cmd 3 "NotAvailableNotInstalled" 2 "Blinking" 1 "On" 0 "Off";
VAL_ 2358902526 Joystick2Lamp3Cmd 3 "NotAvailableNotInstalled" 2 "Blinking" 1 "On" 0 "Off";
VAL_ 2358902526 Joystick2Lamp2Cmd 3 "NotAvailableNotInstalled" 2 "Blinking" 1 "On" 0 "Off";
VAL_ 2358902526 Joystick2Lamp1Cmd 3 "NotAvailableNotInstalled" 2 "Blinking" 1 "On" 0 "Off";
VAL_ 2358902526 Joystick1Lamp10Cmd 3 "NotAvailableNotInstalled" 2 "Blinking" 1 "On" 0 "Off";
VAL_ 2358902526 Joystick1Lamp9Cmd 3 "NotAvailableNotInstalled" 2 "Blinking" 1 "On" 0 "Off";
VAL_ 2358902526 Joystick1Lamp8Cmd 3 "NotAvailableNotInstalled" 2 "Blinking" 1 "On" 0 "Off";
VAL_ 2358902526 Joystick1Lamp7Cmd 3 "NotAvailableNotInstalled" 2 "Blinking" 1 "On" 0 "Off";
VAL_ 2358902526 Joystick1Lamp6Cmd 3 "NotAvailableNotInstalled" 2 "Blinking" 1 "On" 0 "Off";
VAL_ 2358902526 Joystick1Lamp5Cmd 3 "NotAvailableNotInstalled" 2 "Blinking" 1 "On" 0 "Off";
VAL_ 2358902526 Joystick1Lamp4Cmd 3 "NotAvailableNotInstalled" 2 "Blinking" 1 "On" 0 "Off";
VAL_ 2358902526 Joystick1Lamp3Cmd 3 "NotAvailableNotInstalled" 2 "Blinking" 1 "On" 0 "Off";
VAL_ 2358902526 Joystick1Lamp2Cmd 3 "NotAvailableNotInstalled" 2 "Blinking" 1 "On" 0 "Off";
VAL_ 2358902526 Joystick1Lamp1Cmd 3 "NotAvailableNotInstalled" 2 "Blinking" 1 "On" 0 "Off";
VAL_ 2566711550 IntkVlvActtnSystmOlPrss2SlndCtrl 3 "notAvailable" 2 "reservedForSAEAssignment" 1 "on" 0 "off";
VAL_ 2566711550 IntkVlvActtnSystmOlPrss1SlndCtrl 3 "notAvailable" 2 "reservedForSAEAssignment" 1 "on" 0 "off";
VAL_ 2566713854 EngTrbWstgtActtr2OprationStatus 14 "Error" 6 "1101ReservedForFutureAssignment" 5 "UnCtrlledShutdownActive" 4 "CtrlledShutdownActive" 3 "DerateActive" 2 "AlarmHighSeverity" 1 "Alarm" 0 "Normal";
VAL_ 2566713854 EngTrbWstgtActtr1OprationStatus 14 "Error" 6 "1101ReservedForFutureAssignment" 5 "UnCtrlledShutdownActive" 4 "CtrlledShutdownActive" 3 "DerateActive" 2 "AlarmHighSeverity" 1 "Alarm" 0 "Normal";
VAL_ 2566713854 EngTrbWstgteActuator2TempStatus 7 "NotAvailable" 6 "Error" 5 "NotDefined" 4 "LowMostSevere" 3 "LowLeastSevere" 2 "InRange" 1 "HighLeastSevere" 0 "HighMostSevere";
VAL_ 2566714366 EngTrbCmprssrBypssActtr2OprtnStt 14 "Error" 6 "1101ReservedForFutureAssignment" 5 "UnCtrlledShutdownActive" 4 "CtrlledShutdownActive" 3 "DerateActive" 2 "AlarmHighSeverity" 1 "Alarm" 0 "Normal";
VAL_ 2566714366 EngTrbCmprssrBypssActtr1OprtnStt 14 "Error" 6 "1101ReservedForFutureAssignment" 5 "UnCtrlledShutdownActive" 4 "CtrlledShutdownActive" 3 "DerateActive" 2 "AlarmHighSeverity" 1 "Alarm" 0 "Normal";
VAL_ 2566714366 EngTrbCmprssrBypssActtr2TmpStts 7 "NotAvailable" 6 "Error" 5 "NotDefined" 4 "LowMostSevere" 3 "LowLeastSevere" 2 "InRange" 1 "HighLeastSevere" 0 "HighMostSevere";
VAL_ 2566714366 EngTrbCmprssrBypassActuator2Pos 4 "RprsntsBypssFllyOpnTypcllyCmprs";
VAL_ 2566714110 EngFuelValve2OperationStatus 14 "Error" 6 "1101ReservedForFutureAssignment" 5 "UnCtrlledShutdownActive" 4 "CtrlledShutdownActive" 3 "DerateActive" 2 "AlarmHighSeverity" 1 "Alarm" 0 "Normal";
VAL_ 2566714110 EngFuelValve1OperationStatus 14 "Error" 6 "1101ReservedForFutureAssignment" 5 "UnCtrlledShutdownActive" 4 "CtrlledShutdownActive" 3 "DerateActive" 2 "AlarmHighSeverity" 1 "Alarm" 0 "Normal";
VAL_ 2566714110 EngThrttleValve2OperationStatus 14 "Error" 6 "1101ReservedForFutureAssignment" 5 "UnCtrlledShutdownActive" 4 "CtrlledShutdownActive" 3 "DerateActive" 2 "AlarmHighSeverity" 1 "Alarm" 0 "Normal";
VAL_ 2566714110 EngThrttleValve1OperationStatus 15 "NotAvailable" 14 "Error" 6 "1101ReservedForFutureAssignment" 5 "UnCtrlledShutdownActive" 4 "CtrlledShutdownActive" 3 "DerateActive" 2 "AlarmHighSeverity" 1 "Alarm" 0 "Normal";
VAL_ 2566714110 EngFuelValve2TempStatus 7 "NotAvailable" 6 "Error" 5 "NotDefined" 4 "LowMostSevere" 3 "LowLeastSevere" 2 "InRange" 1 "HighLeastSevere" 0 "HighMostSevere";
VAL_ 2566714110 EngFuelValve1TempStatus 7 "NotAvailable" 6 "Error" 5 "NotDefined" 4 "LowMostSevere" 3 "LowLeastSevere" 2 "InRange" 1 "HighLeastSevere" 0 "HighMostSevere";
VAL_ 2566714110 EngThrottleValve2TempStatus 7 "NotAvailable" 6 "Error" 5 "NotDefined" 4 "LowMostSevere" 3 "LowLeastSevere" 2 "InRange" 1 "HighLeastSevere" 0 "HighMostSevere";
VAL_ 2566714110 EngThrottleValve1TempStatus 7 "NotAvailable" 6 "Error" 5 "NotDefined" 4 "LowMostSevere" 3 "LowLeastSevere" 2 "InRange" 1 "HighLeastSevere" 0 "HighMostSevere";
VAL_ 2499607550 EngExhstMnfldBnk1FlwBlncVlvActtr 4 "MeansMaxValveOpening";
VAL_ 2633825534 EngExhstMnfldBnk2FlwBlncVlv_0000 4 "MeansMaxValveOpening";
VAL_ 2365400574 Jystck9GripXAxisDetentPosStatus 3 "NotAvailable" 2 "ErrorIndicator" 1 "InDetentPos" 0 "NotInDetentPos";
VAL_ 2365400574 Jystck9GripYAxisDetentPosStatus 3 "NotAvailable" 2 "ErrorIndicator" 1 "InDetentPos" 0 "NotInDetentPos";
VAL_ 2365400574 Jystck9ThetaAxisDetentPosStatus 3 "NotAvailable" 2 "ErrorIndicator" 1 "InDetentPos" 0 "NotInDetentPos";
VAL_ 2365400574 Jystck9ThtAxsClckwsPstvPsStatus 3 "NotAvailable" 2 "ErrorIndicator" 1 "OnPositiveSideOfNeutral" 0 "NotOnPositiveSideOfNeutral";
VAL_ 2365400574 Jystck9ThtAxsCntrClckwsNgtvPsStt 3 "NotAvailable" 2 "ErrorIndicator" 1 "OnNegativeSideOfNeutral" 0 "NotOnNegativeSideOfNeutral";
VAL_ 2365400574 Jystck9ThtaAxisNeutralPosStatus 3 "NotAvailable" 2 "ErrorIndicator" 1 "InNeutralPos" 0 "NotInNeutralPos";
VAL_ 2365400574 Jystck9GrpYAxsLvrFrwrdPstvPsStts 3 "NotAvailable" 2 "ErrorIndicator" 1 "OnPositiveSideOfNeutral" 0 "NotOnPositiveSideOfNeutral";
VAL_ 2365400574 Jystck9GrpYAxsLvrBckNgtvPsSttus 3 "NotAvailable" 2 "ErrorIndicator" 1 "OnNegativeSideOfNeutral" 0 "NotOnNegativeSideOfNeutral";
VAL_ 2365400574 Jystck9GrpYAxisNeutralPosStatus 3 "NotAvailable" 2 "ErrorIndicator" 1 "InNeutralPos" 0 "NotInNeutralPos";
VAL_ 2365400574 Jystck9GrpXAxsLvrRghtPstvPsStts 3 "NotAvailable" 2 "ErrorIndicator" 1 "OnPositiveSideOfNeutral" 0 "NotOnPositiveSideOfNeutral";
VAL_ 2365400574 Jystck9GrpXAxsLvrLftNgtvPsSttus 3 "NotAvailable" 2 "ErrorIndicator" 1 "OnNegativeSideOfNeutral" 0 "NotOnNegativeSideOfNeutral";
VAL_ 2365400574 Jystck9GrpXAxisNeutralPosStatus 3 "NotAvailable" 2 "ErrorIndicator" 1 "InNeutralPos" 0 "NotInNeutralPos";
VAL_ 2365401086 Jystck8GripXAxisDetentPosStatus 3 "NotAvailable" 2 "ErrorIndicator" 1 "InDetentPos" 0 "NotInDetentPos";
VAL_ 2365401086 Jystck8GripYAxisDetentPosStatus 3 "NotAvailable" 2 "ErrorIndicator" 1 "InDetentPos" 0 "NotInDetentPos";
VAL_ 2365401086 Jystck8ThetaAxisDetentPosStatus 3 "NotAvailable" 2 "ErrorIndicator" 1 "InDetentPos" 0 "NotInDetentPos";
VAL_ 2365401086 Jystck8ThtAxsClckwsPstvPsStatus 3 "NotAvailable" 2 "ErrorIndicator" 1 "OnPositiveSideOfNeutral" 0 "NotOnPositiveSideOfNeutral";
VAL_ 2365401086 Jystck8ThtAxsCntrClckwsNgtvPsStt 3 "NotAvailable" 2 "ErrorIndicator" 1 "OnNegativeSideOfNeutral" 0 "NotOnNegativeSideOfNeutral";
VAL_ 2365401086 Jystck8ThtaAxisNeutralPosStatus 3 "NotAvailable" 2 "ErrorIndicator" 1 "InNeutralPos" 0 "NotInNeutralPos";
VAL_ 2365401086 Jystck8GrpYAxsLvrFrwrdPstvPsStts 3 "NotAvailable" 2 "ErrorIndicator" 1 "OnPositiveSideOfNeutral" 0 "NotOnPositiveSideOfNeutral";
VAL_ 2365401086 Jystck8GrpYAxsLvrBckNgtvPsSttus 3 "NotAvailable" 2 "ErrorIndicator" 1 "OnNegativeSideOfNeutral" 0 "NotOnNegativeSideOfNeutral";
VAL_ 2365401086 Jystck8GrpYAxisNeutralPosStatus 3 "NotAvailable" 2 "ErrorIndicator" 1 "InNeutralPos" 0 "NotInNeutralPos";
VAL_ 2365401086 Jystck8GrpXAxsLvrRghtPstvPsStts 3 "NotAvailable" 2 "ErrorIndicator" 1 "OnPositiveSideOfNeutral" 0 "NotOnPositiveSideOfNeutral";
VAL_ 2365401086 Jystck8GrpXAxsLvrLftNgtvPsSttus 3 "NotAvailable" 2 "ErrorIndicator" 1 "OnNegativeSideOfNeutral" 0 "NotOnNegativeSideOfNeutral";
VAL_ 2365401086 Jystck8GrpXAxisNeutralPosStatus 3 "NotAvailable" 2 "ErrorIndicator" 1 "InNeutralPos" 0 "NotInNeutralPos";
VAL_ 2365401598 Jystck7GripXAxisDetentPosStatus 3 "NotAvailable" 2 "ErrorIndicator" 1 "InDetentPos" 0 "NotInDetentPos";
VAL_ 2365401598 Jystck7GripYAxisDetentPosStatus 3 "NotAvailable" 2 "ErrorIndicator" 1 "InDetentPos" 0 "NotInDetentPos";
VAL_ 2365401598 Jystck7ThetaAxisDetentPosStatus 3 "NotAvailable" 2 "ErrorIndicator" 1 "InDetentPos" 0 "NotInDetentPos";
VAL_ 2365401598 Jystck7ThtAxsClckwsPstvPsStatus 3 "NotAvailable" 2 "ErrorIndicator" 1 "OnPositiveSideOfNeutral" 0 "NotOnPositiveSideOfNeutral";
VAL_ 2365401598 Jystck7ThtAxsCntrClckwsNgtvPsStt 3 "NotAvailable" 2 "ErrorIndicator" 1 "OnNegativeSideOfNeutral" 0 "NotOnNegativeSideOfNeutral";
VAL_ 2365401598 Jystck7ThtaAxisNeutralPosStatus 3 "NotAvailable" 2 "ErrorIndicator" 1 "InNeutralPos" 0 "NotInNeutralPos";
VAL_ 2365401598 Jystck7GrpYAxsLvrFrwrdPstvPsStts 3 "NotAvailable" 2 "ErrorIndicator" 1 "OnPositiveSideOfNeutral" 0 "NotOnPositiveSideOfNeutral";
VAL_ 2365401598 Jystck7GrpYAxsLvrBckNgtvPsSttus 3 "NotAvailable" 2 "ErrorIndicator" 1 "OnNegativeSideOfNeutral" 0 "NotOnNegativeSideOfNeutral";
VAL_ 2365401598 Jystck7GrpYAxisNeutralPosStatus 3 "NotAvailable" 2 "ErrorIndicator" 1 "InNeutralPos" 0 "NotInNeutralPos";
VAL_ 2365401598 Jystck7GrpXAxsLvrRghtPstvPsStts 3 "NotAvailable" 2 "ErrorIndicator" 1 "OnPositiveSideOfNeutral" 0 "NotOnPositiveSideOfNeutral";
VAL_ 2365401598 Jystck7GrpXAxsLvrLftNgtvPsSttus 3 "NotAvailable" 2 "ErrorIndicator" 1 "OnNegativeSideOfNeutral" 0 "NotOnNegativeSideOfNeutral";
VAL_ 2365401598 Jystck7GrpXAxisNeutralPosStatus 3 "NotAvailable" 2 "ErrorIndicator" 1 "InNeutralPos" 0 "NotInNeutralPos";
VAL_ 2365402110 Jystck6GripXAxisDetentPosStatus 3 "NotAvailable" 2 "ErrorIndicator" 1 "InDetentPos" 0 "NotInDetentPos";
VAL_ 2365402110 Jystck6GripYAxisDetentPosStatus 3 "NotAvailable" 2 "ErrorIndicator" 1 "InDetentPos" 0 "NotInDetentPos";
VAL_ 2365402110 Jystck6ThetaAxisDetentPosStatus 3 "NotAvailable" 2 "ErrorIndicator" 1 "InDetentPos" 0 "NotInDetentPos";
VAL_ 2365402110 Jystck6ThtAxsClckwsPstvPsStatus 3 "NotAvailable" 2 "ErrorIndicator" 1 "OnPositiveSideOfNeutral" 0 "NotOnPositiveSideOfNeutral";
VAL_ 2365402110 Jystck6ThtAxsCntrClckwsNgtvPsStt 3 "NotAvailable" 2 "ErrorIndicator" 1 "OnNegativeSideOfNeutral" 0 "NotOnNegativeSideOfNeutral";
VAL_ 2365402110 Jystck6ThtaAxisNeutralPosStatus 3 "NotAvailable" 2 "ErrorIndicator" 1 "InNeutralPos" 0 "NotInNeutralPos";
VAL_ 2365402110 Jystck6GrpYAxsLvrFrwrdPstvPsStts 3 "NotAvailable" 2 "ErrorIndicator" 1 "OnPositiveSideOfNeutral" 0 "NotOnPositiveSideOfNeutral";
VAL_ 2365402110 Jystck6GrpYAxsLvrBckNgtvPsSttus 3 "NotAvailable" 2 "ErrorIndicator" 1 "OnNegativeSideOfNeutral" 0 "NotOnNegativeSideOfNeutral";
VAL_ 2365402110 Jystck6GrpYAxisNeutralPosStatus 3 "NotAvailable" 2 "ErrorIndicator" 1 "InNeutralPos" 0 "NotInNeutralPos";
VAL_ 2365402110 Jystck6GrpXAxsLvrRghtPstvPsStts 3 "NotAvailable" 2 "ErrorIndicator" 1 "OnPositiveSideOfNeutral" 0 "NotOnPositiveSideOfNeutral";
VAL_ 2365402110 Jystck6GrpXAxsLvrLftNgtvPsSttus 3 "NotAvailable" 2 "ErrorIndicator" 1 "OnNegativeSideOfNeutral" 0 "NotOnNegativeSideOfNeutral";
VAL_ 2365402110 Jystck6GrpXAxisNeutralPosStatus 3 "NotAvailable" 2 "ErrorIndicator" 1 "InNeutralPos" 0 "NotInNeutralPos";
VAL_ 2365402622 Jystck5GripXAxisDetentPosStatus 3 "NotAvailable" 2 "ErrorIndicator" 1 "InDetentPos" 0 "NotInDetentPos";
VAL_ 2365402622 Jystck5GripYAxisDetentPosStatus 3 "NotAvailable" 2 "ErrorIndicator" 1 "InDetentPos" 0 "NotInDetentPos";
VAL_ 2365402622 Jystck5ThetaAxisDetentPosStatus 3 "NotAvailable" 2 "ErrorIndicator" 1 "InDetentPos" 0 "NotInDetentPos";
VAL_ 2365402622 Jystck5ThtAxsClckwsPstvPsStatus 3 "NotAvailable" 2 "ErrorIndicator" 1 "OnPositiveSideOfNeutral" 0 "NotOnPositiveSideOfNeutral";
VAL_ 2365402622 Jystck5ThtAxsCntrClckwsNgtvPsStt 3 "NotAvailable" 2 "ErrorIndicator" 1 "OnNegativeSideOfNeutral" 0 "NotOnNegativeSideOfNeutral";
VAL_ 2365402622 Jystck5ThtaAxisNeutralPosStatus 3 "NotAvailable" 2 "ErrorIndicator" 1 "InNeutralPos" 0 "NotInNeutralPos";
VAL_ 2365402622 Jystck5GrpYAxsLvrFrwrdPstvPsStts 3 "NotAvailable" 2 "ErrorIndicator" 1 "OnPositiveSideOfNeutral" 0 "NotOnPositiveSideOfNeutral";
VAL_ 2365402622 Jystck5GrpYAxsLvrBckNgtvPsSttus 3 "NotAvailable" 2 "ErrorIndicator" 1 "OnNegativeSideOfNeutral" 0 "NotOnNegativeSideOfNeutral";
VAL_ 2365402622 Jystck5GrpYAxisNeutralPosStatus 3 "NotAvailable" 2 "ErrorIndicator" 1 "InNeutralPos" 0 "NotInNeutralPos";
VAL_ 2365402622 Jystck5GrpXAxsLvrRghtPstvPsStts 3 "NotAvailable" 2 "ErrorIndicator" 1 "OnPositiveSideOfNeutral" 0 "NotOnPositiveSideOfNeutral";
VAL_ 2365402622 Jystck5GrpXAxsLvrLftNgtvPsSttus 3 "NotAvailable" 2 "ErrorIndicator" 1 "OnNegativeSideOfNeutral" 0 "NotOnNegativeSideOfNeutral";
VAL_ 2365402622 Jystck5GrpXAxisNeutralPosStatus 3 "NotAvailable" 2 "ErrorIndicator" 1 "InNeutralPos" 0 "NotInNeutralPos";
VAL_ 2365403134 Jystck4GripXAxisDetentPosStatus 3 "NotAvailable" 2 "ErrorIndicator" 1 "InDetentPos" 0 "NotInDetentPos";
VAL_ 2365403134 Jystck4GripYAxisDetentPosStatus 3 "NotAvailable" 2 "ErrorIndicator" 1 "InDetentPos" 0 "NotInDetentPos";
VAL_ 2365403134 Jystck4ThetaAxisDetentPosStatus 3 "NotAvailable" 2 "ErrorIndicator" 1 "InDetentPos" 0 "NotInDetentPos";
VAL_ 2365403134 Jystck4ThtAxsClckwsPstvPsStatus 3 "NotAvailable" 2 "ErrorIndicator" 1 "OnPositiveSideOfNeutral" 0 "NotOnPositiveSideOfNeutral";
VAL_ 2365403134 Jystck4ThtAxsCntrClckwsNgtvPsStt 3 "NotAvailable" 2 "ErrorIndicator" 1 "OnNegativeSideOfNeutral" 0 "NotOnNegativeSideOfNeutral";
VAL_ 2365403134 Jystck4ThtaAxisNeutralPosStatus 3 "NotAvailable" 2 "ErrorIndicator" 1 "InNeutralPos" 0 "NotInNeutralPos";
VAL_ 2365403134 Jystck4GrpYAxsLvrFrwrdPstvPsStts 3 "NotAvailable" 2 "ErrorIndicator" 1 "OnPositiveSideOfNeutral" 0 "NotOnPositiveSideOfNeutral";
VAL_ 2365403134 Jystck4GrpYAxsLvrBckNgtvPsSttus 3 "NotAvailable" 2 "ErrorIndicator" 1 "OnNegativeSideOfNeutral" 0 "NotOnNegativeSideOfNeutral";
VAL_ 2365403134 Jystck4GrpYAxisNeutralPosStatus 3 "NotAvailable" 2 "ErrorIndicator" 1 "InNeutralPos" 0 "NotInNeutralPos";
VAL_ 2365403134 Jystck4GrpXAxsLvrRghtPstvPsStts 3 "NotAvailable" 2 "ErrorIndicator" 1 "OnPositiveSideOfNeutral" 0 "NotOnPositiveSideOfNeutral";
VAL_ 2365403134 Jystck4GrpXAxsLvrLftNgtvPsSttus 3 "NotAvailable" 2 "ErrorIndicator" 1 "OnNegativeSideOfNeutral" 0 "NotOnNegativeSideOfNeutral";
VAL_ 2365403134 Jystck4GrpXAxisNeutralPosStatus 3 "NotAvailable" 2 "ErrorIndicator" 1 "InNeutralPos" 0 "NotInNeutralPos";
VAL_ 2365400062 Jystck10GrpXAxisDetentPosStatus 3 "NotAvailable" 2 "ErrorIndicator" 1 "InDetentPos" 0 "NotInDetentPos";
VAL_ 2365400062 Jystck10GrpYAxisDetentPosStatus 3 "NotAvailable" 2 "ErrorIndicator" 1 "InDetentPos" 0 "NotInDetentPos";
VAL_ 2365400062 Jystck10ThtaAxisDetentPosStatus 3 "NotAvailable" 2 "ErrorIndicator" 1 "InDetentPos" 0 "NotInDetentPos";
VAL_ 2365400062 Jystck10ThtAxsClckwsPstvPsSttus 3 "NotAvailable" 2 "ErrorIndicator" 1 "OnPositiveSideOfNeutral" 0 "NotOnPositiveSideOfNeutral";
VAL_ 2365400062 Jystck10ThtAxsCntrClckwsNgtvPsSt 3 "NotAvailable" 2 "ErrorIndicator" 1 "OnNegativeSideOfNeutral" 0 "NotOnNegativeSideOfNeutral";
VAL_ 2365400062 Jystck10ThtAxisNeutralPosStatus 3 "NotAvailable" 2 "ErrorIndicator" 1 "InNeutralPos" 0 "NotInNeutralPos";
VAL_ 2365400062 Jystck10GrpYAxsLvrFrwrdPstvPsStt 3 "NotAvailable" 2 "ErrorIndicator" 1 "OnPositiveSideOfNeutral" 0 "NotOnPositiveSideOfNeutral";
VAL_ 2365400062 Jystck10GrpYAxsLvrBckNgtvPsStts 3 "NotAvailable" 2 "ErrorIndicator" 1 "OnNegativeSideOfNeutral" 0 "NotOnNegativeSideOfNeutral";
VAL_ 2365400062 Jystck10GrpYAxsNeutralPosStatus 3 "NotAvailable" 2 "ErrorIndicator" 1 "InNeutralPos" 0 "NotInNeutralPos";
VAL_ 2365400062 Jystck10GrpXAxsLvrRghtPstvPsStts 3 "NotAvailable" 2 "ErrorIndicator" 1 "OnPositiveSideOfNeutral" 0 "NotOnPositiveSideOfNeutral";
VAL_ 2365400062 Jystck10GrpXAxsLvrLftNgtvPsStts 3 "NotAvailable" 2 "ErrorIndicator" 1 "OnNegativeSideOfNeutral" 0 "NotOnNegativeSideOfNeutral";
VAL_ 2365400062 Jystck10GrpXAxsNeutralPosStatus 3 "NotAvailable" 2 "ErrorIndicator" 1 "InNeutralPos" 0 "NotInNeutralPos";
VAL_ 2633825022 EngExhstGsRcrclation2Valve2Ctrl 4 "MeansMaxOpening";
VAL_ 2633825022 EngExhstGsRcrculation2ValveCtrl 4 "MeansMaxOpening";
VAL_ 2566749438 DslPrtcltFltrActvRgnrtnFrcdStts 7 "notAvailable" 6 "ReservedForSAEAssignment" 2 "ActiveForcedByServiceTool" 1 "ActiveForcedBySwitch" 0 "NotActive";
VAL_ 2566749438 ExhaustSystemHighTempLampCmd 7 "notAvailable" 6 "reservedForSAEAssignment" 1 "OnSolid" 0 "Off";
VAL_ 2566749438 DslPrtcltFltrAtmtcActvRgnrtnIntt 3 "notAvailable" 2 "reservedForSAEAssignment" 1 "enabled" 0 "notEnabled";
VAL_ 2566749438 DslPrtcltFltrActvRgnrtnInhbtdDTV 3 "notAvailable" 2 "reservedForSAEAssignment" 1 "inhibited" 0 "notInhibited";
VAL_ 2566749438 DslPrtcltFltrActvRgnrtnInhbtdDTE 3 "notAvailable" 2 "reservedForSAEAssignment" 1 "inhibited" 0 "notInhibited";
VAL_ 2566749438 DslPrtcltFltrActvRgnrtnInhbtdDTP 3 "notAvailable" 2 "reservedForSAEAssignment" 1 "inhibited" 0 "notInhibited";
VAL_ 2566749438 DslPrtcltFltrActvRgnrtnInhbtdDTT 3 "notAvailable" 2 "reservedForSAEAssignment" 1 "inhibited" 0 "notInhibited";
VAL_ 2566749438 DslPrtcltFltrActvRgnrtnInhbtdDTS 3 "notAvailable" 2 "reservedForSAEAssignment" 1 "inhibited" 0 "notInhibited";
VAL_ 2566749438 DslPrtcltFltrActvRgnrtnInhb_0000 3 "notAvailable" 2 "reservedForSAEAssignment" 1 "inhibited" 0 "notInhibited";
VAL_ 2566749438 DslPrtcltFltrActvRgnrtnInhbtdDTL 3 "notAvailable" 2 "reservedForSAEAssignment" 1 "inhibited" 0 "notInhibited";
VAL_ 2566749438 DslPrtcltFltrActvRgnrtnInhb_0001 3 "notAvailable" 2 "reservedForSAEAssignment" 1 "inhibited" 0 "notInhibited";
VAL_ 2566749438 DslPrtcltFltrActvRgnrtnInhb_0002 3 "notAvailable" 2 "reservedForSAEAssignment" 1 "inhibited" 0 "notInhibited";
VAL_ 2566749438 DslPrtcltFltrActvRgnrtnInhbtdDTO 3 "notAvailable" 2 "reservedForSAEAssignment" 1 "inhibited" 0 "notInhibited";
VAL_ 2566749438 DslPrtcltFltrActvRgnrtnInhbtdDTA 3 "notAvailable" 2 "reservedForSAEAssignment" 1 "inhibited" 0 "notInhibited";
VAL_ 2566749438 DslPrtcltFltrActvRgnrtnInhb_0003 3 "notAvailable" 2 "reservedForSAEAssignment" 1 "inhibited" 0 "notInhibited";
VAL_ 2566749438 DslPrtcltFltrActvRgnrtnInhb_0004 3 "notAvailable" 2 "reservedForSAEAssignment" 1 "inhibited" 0 "notInhibited";
VAL_ 2566749438 DslPrtcltFltrActvRgnrtnInhbtdDTC 3 "notAvailable" 2 "reservedForSAEAssignment" 1 "inhibited" 0 "notInhibited";
VAL_ 2566749438 DslPrtcltFltrActvRgnrtnInhbtdDTI 3 "notAvailable" 2 "reservedForSAEAssignment" 1 "inhibited" 0 "notInhibited";
VAL_ 2566749438 DslPrtcltFltrActvRgnrtnInhbtdStt 3 "notAvailable" 2 "reservedForSAEAssignment" 1 "inhibited" 0 "notInhibited";
VAL_ 2566749438 DieselParticulateFilterStatus 7 "notAvailable" 6 "reservedForSAEAssignment" 3 "RegenerationNeededHighestLevel" 2 "RegenerationNeededModerateLevel" 1 "RegenerationNeededLowestLevel" 0 "RegenerationNotNeeded";
VAL_ 2566749438 DslPrtcltFltrActvRgnrtionStatus 3 "notAvailable" 2 "rgnrtnNddAtmtcllyInttdActvRgnrt" 1 "active" 0 "notActive";
VAL_ 2566749438 DslPrtcltFltrPssvRgnrtionStatus 3 "notAvailable" 2 "reservedForSAEAssignment" 1 "active" 0 "notActive";
VAL_ 2566749438 DieselParticulateFilterLampCmd 7 "notAvailable" 4 "OnFastBlink" 6 "reservedForSAEAssignment" 1 "OnSolid" 0 "Off";
VAL_ 2566718718 VehicleBatteryChargingLampData 3 "NotAvailable" 2 "Error" 1 "LampActivated" 0 "LampDeactivated";
VAL_ 2566718718 VhicleHVACRecirculationLampData 3 "NotAvailable" 2 "Error" 1 "LampActivated" 0 "LampDeactivated";
VAL_ 2566718718 VehicleAirPressLowLampData 3 "NotAvailable" 2 "Error" 1 "LampActivated" 0 "LampDeactivated";
VAL_ 2566718718 VehicleFuelLevelLowLampData 3 "NotAvailable" 2 "Error" 1 "LampActivated" 0 "LampDeactivated";
VAL_ 2566718718 VhicleBatteryVoltageLowLampData 3 "NotAvailable" 2 "Error" 1 "LampActivated" 0 "LampDeactivated";
VAL_ 2566718974 EngWaitToStartLampData 3 "NotAvailable" 2 "Error" 1 "LampActive" 0 "LampDeactive";
VAL_ 2566718974 EngFuelFilterRestrictedLampData 3 "NotAvailable" 2 "Error" 1 "LampActivated" 0 "LampDeactivated";
VAL_ 2566718974 EngAirFilterRestrictionLampData 3 "NotAvailable" 2 "Error" 1 "LampActivated" 0 "LampDeactivated";
VAL_ 2566718974 EngIdleManagementActiveLampData 3 "NotAvailable" 2 "Error" 1 "LampActivated" 0 "LampDeactivated";
VAL_ 2566718974 EngCoolantLevelLowLampData 3 "NotAvailable" 2 "Error" 1 "LampActivated" 0 "LampDeactivated";
VAL_ 2566718974 EngCoolantTempHighLampData 3 "NotAvailable" 2 "Error" 1 "LampActivated" 0 "LampDeactivated";
VAL_ 2566718974 EngOilPressLowLampData 3 "NotAvailable" 2 "Error" 1 "LampActivated" 0 "LampDeactivated";
VAL_ 2566718974 CmprssnBrkEnblSwtchIndctrLmpDta 3 "NotAvailable" 2 "Error" 1 "LampActivated" 0 "LampDeactivated";
VAL_ 2566718974 EngBrakeActiveLampData 3 "NotAvailable" 2 "Error" 1 "LampActivated" 0 "LampDeactivated";
VAL_ 2566718974 OBDMalfunctionIndicatorLampData 3 "NotAvailable" 2 "Error" 1 "LampActivated" 0 "LampDeactivated";
VAL_ 2566718974 EngRedStopLampData 3 "NotAvailable" 2 "Error" 1 "LampActivated" 0 "LampDeactivated";
VAL_ 2566718974 EngAmberWarningLampData 3 "NotAvailable" 2 "Error" 1 "LampActivated" 0 "LampDeactivated";
VAL_ 2566718974 EngProtectLampData 3 "NotAvailable" 2 "Error" 1 "LampActivated" 0 "LampDeactivated";
VAL_ 2566719230 VehicleBatteryChargingLampCmd 3 "NotAvailable" 2 "Reserved" 1 "LampOn" 0 "LampOff";
VAL_ 2566719230 VehicleHVACRecirculationLampCmd 3 "NotAvailable" 2 "Reserved" 1 "LampOn" 0 "LampOff";
VAL_ 2566719230 VehicleAirPressLowLampCmd 3 "NotAvailable" 2 "Reserved" 1 "LampOn" 0 "LampOff";
VAL_ 2566719230 VehicleFuelLevelLowLampCmd 3 "NotAvailable" 2 "Reserved" 1 "LampOn" 0 "LampOff";
VAL_ 2566719230 VehicleBatteryVoltageLowLampCmd 3 "NotAvailable" 2 "Reserved" 1 "LampOn" 0 "LampOff";
VAL_ 2560818942 FailureModeIdentifier1 31 "Not available" 19 "Received network data in error" 18 "Below normal (moderately severe)" 17 "Below normal (least severe)" 16 "Above normal (moderately severe)" 15 "Above normal (least severe)" 14 "Special intstructions" 13 "Out of calibration" 12 "Bad intelligent device" 11 "Root cause not known" 10 "Abnormal rate of change" 9 "Abnormal update rate" 8 "Abnormal frequency" 7 "Mechanical system not responding" 6 "Current above normal" 5 "Current below normal" 4 "Voltage below normal" 3 "Voltage above normal" 2 "Data erratic" 1 "Below normal (most severe)" 0 "Above normal (most severe)";
VAL_ 2561212158 TextDisplayInstructions 7 "1110Reserved" 6 "BlinkSubstring" 15 "NotApplicable" 1 "HldDsplyPrsntlyDsplydInfrmtnShl" 0 "ClrDsplyDsplydInfrmtnShldBDltdN" 5 "HighlightSubstring" 4 "OvrwrtSbstrngAPrtnOfPrsntlyDspl" 3 "OvrwrtDsplyPrsntlyDsplydInfrmtn" 2 "AppndAtEndOfDsplyTrnsmttdInfrmt";
VAL_ 2566746366 RetractStatusOfRamp5 2 "error" 1 "rampEx" 0 "rampRetracted" 3 "notAvailable";
VAL_ 2566746366 RetractStatusOfRamp4 3 "notAvailable" 2 "error" 1 "rampEx" 0 "rampRetracted";
VAL_ 2566746366 MovementStatusOfRamp5 3 "notAvailable" 2 "error" 1 "rampBeingMoved" 0 "rampNotBeingMoved";
VAL_ 2566746366 MovementStatusOfRamp4 3 "notAvailable" 2 "error" 1 "rampBeingMoved" 0 "rampNotBeingMoved";
VAL_ 2566746366 EnableStatusOfRamp5 3 "notAvailable" 2 "error" 1 "rampEnabled" 0 "rampDisabled";
VAL_ 2566746366 EnableStatusOfRamp4 3 "notAvailable" 2 "error" 1 "rampEnabled" 0 "rampDisabled";
VAL_ 2566746366 MovementStatusOfRamp3 3 "notAvailable" 2 "error" 1 "rampBeingMoved" 0 "rampNotBeingMoved";
VAL_ 2566746366 EnableStatusOfRamp3 3 "notAvailable" 2 "error" 1 "rampEnabled" 0 "rampDisabled";
VAL_ 2566746366 RetractStatusOfRamp3 3 "notAvailable" 2 "error" 1 "rampEx" 0 "rampRetracted";
VAL_ 2566746366 MovementStatusOfRamp2 3 "notAvailable" 2 "error" 1 "rampBeingMoved" 0 "rampNotBeingMoved";
VAL_ 2566746366 EnableStatusOfRamp2 3 "notAvailable" 2 "error" 1 "rampEnabled" 0 "rampDisabled";
VAL_ 2566746366 RetractStatusOfRamp2 3 "notAvailable" 2 "error" 1 "rampEx" 0 "rampRetracted";
VAL_ 2566746366 MovementStatusOfRamp1 3 "notAvailable" 2 "error" 1 "rampBeingMoved" 0 "rampNotBeingMoved";
VAL_ 2566746366 EnableStatusOfRamp1 3 "notAvailable" 2 "error" 1 "rampEnabled" 0 "rampDisabled";
VAL_ 2566746366 RetractStatusOfRamp1 3 "notAvailable" 2 "error" 1 "rampEx" 0 "rampRetracted";
VAL_ 2566746110 EngExhstGsRcrclation1Valve2Ctrl 4 "MeansMaxValveOpening";
VAL_ 2561277694 LaneDepartureWarningEnableCmd 3 "DonTCare" 2 "Reserved" 1 "EnableLaneDepartureWarning" 0 "DisableLaneDepartureWarning";
VAL_ 2633861886 J2012DTCStatus 1 "DTCIsActive" 0 "DTCIsPreviouslyActive";
VAL_ 2565873150 SteerAngleSensorCalibrated 3 "NotAvailable" 2 "Reserved" 1 "SASCalibrated" 0 "SASNotCalibrated";
VAL_ 2565873150 SteerAngleSensorActiveMode 3 "NotAvailable" 2 "Reserved" 1 "NormalModeActive" 0 "ProgrammingModeActive";
VAL_ 2565873150 SteerWheelAngleRangeCounterType 3 "SignalNotAvailable" 2 "NotDefined" 1 "AbsNumberOfCounts" 0 "RelativeNumberOfCounts";
VAL_ 2566751230 TransferCaseStatus 7 "notAvailable" 6 "error" 5 "TrnsfrCsShftInPrgrssGrNtCnfrmed" 4 "WheelLow" 2 "neutral" 1 "WheelHigh";
VAL_ 2566755838 TransOverheatIndicator 3 "NotAvailable" 2 "TrnsOverheatIndicatorIsFlashing" 1 "TrnsOvrhtIndctrIsOnContinuously" 0 "TransOverheatIndicatorIsOff";
VAL_ 2566755838 TransOilLevelSwitch 3 "NotAvailable" 2 "Error" 1 "FullNotEmpty" 0 "Empty";
VAL_ 2566755838 TransOilFilterRestrictionSwitch 3 "NotAvailable" 2 "Error" 1 "RestrictionExistsOnOilFilter" 0 "NoRestriction";
VAL_ 2566799614 ImplementRearWorkLight 3 "NotAvailable" 2 "FaultDetected" 1 "Activated" 0 "Deactivated";
VAL_ 2566799614 ImplementLeftForwardWorkLight 3 "NotAvailable" 2 "FaultDetected" 1 "Activated" 0 "Deactivated";
VAL_ 2566799614 ImplementRightForwardWorkLight 3 "NotAvailable" 2 "FaultDetected" 1 "Activated" 0 "Deactivated";
VAL_ 2566799614 ImplementLeftFacingWorkLight 3 "NotAvailable" 2 "FaultDetected" 1 "Activate" 0 "Deactivate";
VAL_ 2566799614 ImplementRightFacingWorkLight 3 "NotAvailable" 2 "FaultDetected" 1 "Activated" 0 "Deactivated";
VAL_ 2566799614 ImplementOEMOption1Light 3 "NotAvailable" 2 "FaultDetected" 1 "Activated" 0 "Deactivated";
VAL_ 2566799614 ImplementOEMOption2Light 3 "NotAvailable" 2 "FaultDetected" 1 "Activated" 0 "Deactivated";
VAL_ 2566799614 TrctrFrontHighMountedWorkLights 3 "NotAvailable" 2 "FaultDetected" 1 "Activated" 0 "Deactivated";
VAL_ 2566799614 TrctorFrontLowMountedWorkLights 3 "NotAvailable" 2 "FaultDetected" 1 "Activated" 0 "Deactivated";
VAL_ 2566799614 TrctorSideHighMountedWorkLights 3 "NotAvailable" 2 "FaultDetected" 1 "Activated" 0 "Deactivated";
VAL_ 2566799614 TractorSideLowMountedWorkLights 3 "NotAvailable" 2 "FaultDetected" 1 "Activated" 0 "Deactivated";
VAL_ 2566799614 TrctorRearHighMountedWorkLights 3 "NotAvailable" 2 "FaultDetected" 1 "Activated" 0 "Deactivated";
VAL_ 2566799614 TractorRearLowMountedWorkLights 3 "NotAvailable" 2 "FaultDetected" 1 "Activated" 0 "Deactivated";
VAL_ 2566799614 TrctrUndersideMountedWorkLights 3 "NotAvailable" 2 "FaultDetected" 1 "Activated" 0 "Deactivated";
VAL_ 2566799614 RearFogLights 3 "NotAvailable" 2 "FaultDetected" 1 "Activated" 0 "Deactivated";
VAL_ 2566799614 TractorMarkerLight 3 "NotAvailable" 2 "FaultDetected" 1 "Activated" 0 "Deactivated";
VAL_ 2566799614 ImplementMarkerLight 3 "NotAvailable" 2 "FaultDetected" 1 "Activated" 0 "Deactivated";
VAL_ 2566799614 TractorClearanceLight 3 "NotAvailable" 2 "FaultDetected" 1 "Activated" 0 "Deactivated";
VAL_ 2566799614 ImplementClearanceLight 3 "NotAvailable" 2 "FaultDetected" 1 "Activated" 0 "Deactivated";
VAL_ 2566799614 LeftStopLight 3 "NotAvailable" 2 "FaultDetected" 1 "Activated" 0 "Deactivated";
VAL_ 2566799614 RightStopLight 3 "NotAvailable" 2 "FaultDetected" 1 "Activated" 0 "Deactivated";
VAL_ 2566799614 CenterStopLight 3 "NotAvailable" 2 "FaultDetected" 1 "Activated" 0 "Deactivated";
VAL_ 2566799614 BackUpLightAndAlarmHorn 3 "NotAvailable" 2 "FaultDetected" 1 "Activated" 0 "Deactivated";
VAL_ 2566799614 LeftTurnSignalLights 3 "NotAvailable" 2 "FaultDetected" 1 "Activated" 0 "Deactivated";
VAL_ 2566799614 RightTurnSignalLights 3 "NotAvailable" 2 "FaultDetected" 1 "Activated" 0 "Deactivated";
VAL_ 2566799614 RotatingBeaconLight 3 "NotAvailable" 2 "FaultDetected" 1 "Activated" 0 "Deactivated";
VAL_ 2566799614 TractorFrontFogLights 3 "NotAvailable" 2 "FaultDetected" 1 "Activated" 0 "Deactivated";
VAL_ 2566799614 HighBeamHeadLightData 3 "NotAvailable" 2 "FaultDetected" 1 "Activated" 0 "Deactivated";
VAL_ 2566799614 LowBeamHeadLightData 3 "NotAvailable" 2 "FaultDetected" 1 "Activated" 0 "Deactivated";
VAL_ 2566799614 AltBeamHeadLightData 3 "NotAvailable" 2 "FaultDetected" 1 "Activated" 0 "Deactivated";
VAL_ 2566799614 RunningLight 3 "NotAvailable" 2 "FaultDetected" 1 "Activated" 0 "Deactivated";
VAL_ 2365473278 ImplementRearWorkLightCmd 3 "DonTCare" 2 "Reserved" 1 "Activate" 0 "Deactivate";
VAL_ 2365473278 ImplmentLeftForwardWorkLightCmd 3 "DonTCare" 2 "Reserved" 1 "Activate" 0 "Deactivate";
VAL_ 2365473278 ImplmntRightForwardWorkLightCmd 3 "DonTCare" 2 "Reserved" 1 "Activate" 0 "Deactivate";
VAL_ 2365473278 LightingDataRqCmd 3 "DonTCare" 2 "Reserved" 1 "Activate" 0 "Deactivate";
VAL_ 2365473278 ImplementLeftFacingWorkLightCmd 3 "DonTCare" 2 "Reserved" 1 "Activate" 0 "Deactivate";
VAL_ 2365473278 ImplmentRightFacingWorkLightCmd 3 "DonTCare" 2 "Reserved" 1 "Activate" 0 "Deactivate";
VAL_ 2365473278 ImplementOEMOption1LightCmd 3 "DonTCare" 2 "Reserved" 1 "Activate" 0 "Deactivate";
VAL_ 2365473278 ImplementOEMOption2LightCmd 3 "DonTCare" 2 "Reserved" 1 "Activate" 0 "Deactivate";
VAL_ 2365473278 TrctrFrntHghMuntedWorkLightsCmd 3 "DonTCare" 2 "Reserved" 1 "Activate" 0 "Deactivate";
VAL_ 2365473278 TrctrFrntLwMountedWorkLightsCmd 3 "DonTCare" 2 "Reserved" 1 "Activate" 0 "Deactivate";
VAL_ 2365473278 TrctrSdHighMountedWorkLightsCmd 3 "DonTCare" 2 "Reserved" 1 "Activate" 0 "Deactivate";
VAL_ 2365473278 TrctrSdeLowMountedWorkLightsCmd 3 "DonTCare" 2 "Reserved" 1 "Activate" 0 "Deactivate";
VAL_ 2365473278 TrctrRrHighMountedWorkLightsCmd 3 "DonTCare" 2 "Reserved" 1 "Activate" 0 "Deactivate";
VAL_ 2365473278 TrctrRarLowMountedWorkLightsCmd 3 "DonTCare" 2 "Reserved" 1 "Activate" 0 "Deactivate";
VAL_ 2365473278 TrctrUndrsdMountedWorkLightsCmd 3 "DonTCare" 2 "Reserved" 1 "Activate" 0 "Deactivate";
VAL_ 2365473278 RearFogLightCmd 3 "DonTCare" 2 "Reserved" 1 "Activate" 0 "Deactivate";
VAL_ 2365473278 TractorMarkerLightCmd 3 "DonTCare" 2 "Reserved" 1 "Activate" 0 "Deactivate";
VAL_ 2365473278 ImplementMarkerLightCmd 3 "DonTCare" 2 "Reserved" 1 "Activate" 0 "Deactivate";
VAL_ 2365473278 TractorClearanceLightCmd 3 "DonTCare" 2 "Reserved" 1 "Activate" 0 "Deactivate";
VAL_ 2365473278 ImplementClearanceLightCmd 3 "DonTCare" 2 "Reserved" 1 "Activate" 0 "Deactivate";
VAL_ 2365473278 LeftStopLightCmd 3 "DonTCare" 2 "Reserved" 1 "Activate" 0 "Deactivate";
VAL_ 2365473278 RightStopLightCmd 3 "DonTCare" 2 "Reserved" 1 "Activate" 0 "Deactivate";
VAL_ 2365473278 CenterStopLightCmd 3 "DonTCare" 2 "Reserved" 1 "Activate" 0 "Deactivate";
VAL_ 2365473278 BackUpLightAndAlarmHornCmd 3 "DonTCare" 2 "Reserved" 1 "Activate" 0 "Deactivate";
VAL_ 2365473278 LeftTurnSignalLightsCmd 3 "DonTCare" 2 "Reserved" 1 "Activate" 0 "Deactivate";
VAL_ 2365473278 RightTurnSignalLightsCmd 3 "DonTCare" 2 "Reserved" 1 "Activate" 0 "Deactivate";
VAL_ 2365473278 RotatingBeaconLightCmd 3 "DonTCare" 2 "Reserved" 1 "Activate" 0 "Deactivate";
VAL_ 2365473278 TractorFrontFogLightsCmd 3 "DonTCare" 2 "Reserved" 1 "Activate" 0 "Deactivate";
VAL_ 2365473278 HighBeamHeadLightCmd 3 "DonTCare" 2 "Reserved" 1 "Activate" 0 "Deactivate";
VAL_ 2365473278 LowBeamHeadLightCmd 3 "DonTCare" 2 "Reserved" 1 "Activate" 0 "Deactivate";
VAL_ 2365473278 AltBeamHeadLightCmd 3 "DonTCare" 2 "Reserved" 1 "Activate" 0 "Deactivate";
VAL_ 2365473278 RunningLightCmd 3 "DonTCare" 2 "Reserved" 1 "Activate" 0 "Deactivate";
VAL_ 2365485822 BladeCtrlMode 2 "InactiveAutomaticMode" 1 "AutomaticMode" 0 "ManualMode";
VAL_ 2365485822 LandLevelingSystemEnableStatus 3 "NotAvailable_NotInstalled" 2 "Error" 1 "Enabled" 0 "Disabled";
VAL_ 2365485822 BladeCtrlModeRight 15 "NotAvailable" 14 "Error" 3 "1101Reserved" 2 "InactiveAuto" 1 "Auto" 0 "Manual";
VAL_ 2365485822 BladeCtrlModeLeft 15 "NotAvailable" 14 "Error" 3 "1101Reserved" 2 "InactiveAuto" 1 "Auto" 0 "Manual";
VAL_ 2566768894 EngOprtrPrmryIntrmdtSpdSlctStte 15 "NotAvailable" 14 "SAEReserved" 1 "thr1101CtrlSttIsISCSttng1Thru13" 0 "CtrlSttIsISCFnctnltyIsNtRqdEngO";
VAL_ 2566769406 EngOprtrPrmryIntrmdtSpeedSelect 15 "NotAvailable" 14 "ErrorCondition" 1 "thr1101IndctsThtISCSttng1Thr13I" 0 "IndctsThtISCFnctnltyIsNtRqdEngO";
VAL_ 2566811134 CabHeatingZone 3 "NotAvailable" 2 "Reserved" 1 "CabHeatingZoneOn" 0 "CabHeatingZoneOff";
VAL_ 2566811134 EngHeatingZone 3 "NotAvailable" 2 "Reserved" 1 "EngHeatingZoneOn" 0 "EngHeatingZoneOff";
VAL_ 2566811134 CabVentilation 3 "NotAvailable" 2 "Reserved" 1 "CabIsVentilated" 0 "CabNotVentilated";
VAL_ 2566811134 AuxHeaterMode 15 "NotAvailable" 14 "Error" 4 "1101NotDefined" 3 "NormalMode" 2 "EconomyMode" 1 "OffDTADRPrErpnRgltnsFrTrnsprtOf" 0 "HeaterNotActive";
VAL_ 2566811134 AuxHeaterWaterPumpStatus 3 "NotAvailable" 2 "Reserved" 1 "WaterPumpIsRunning" 0 "WaterPumpIsNotRunning";
VAL_ 2565867774 FireApparatusPumpEngagement 3 "NotAvailableNotInstalled" 2 "Error" 1 "PumpEngaged" 0 "PumpNotEngaged";
VAL_ 2565867774 EngHydPressGovernorSwitch 3 "NotAvailable" 2 "ErrorIndicator" 1 "PressModeActive" 0 "PressModeInactive";
VAL_ 2565867774 EngHydPrssGovernorModeIndicator 3 "NotAvailable" 2 "ErrorIndicator" 1 "Enabled" 0 "Disabled";
VAL_ 2365449982 HydBrakeFluidLevelSwitch 3 "NotAvailable" 2 "ErrorIndicator" 1 "FluidLevelIsSufficient" 0 "FluidLevelIsNotSufficient";
VAL_ 2365449982 HydBrakeSystemAudibleWarningCmd 3 "DontCare" 2 "Reserved" 1 "AudibleWarningOn" 0 "AudibleWarningOff";
VAL_ 2365449982 HydBrkePressSupplyStateCircuit2 3 "NotAvailable" 2 "ErrorIndicator" 1 "SupplyIsReliable" 0 "SupplyIsNotReliable";
VAL_ 2365449982 HydBrkePressSupplyStateCircuit1 3 "NotAvailable" 2 "ErrorIndicator" 1 "SupplyIsReliable" 0 "SupplyIsNotReliable";
VAL_ 2365449982 HydBrkPressWarningStateCircuit2 3 "NotAvailable" 2 "ErrorIndicator" 1 "PressLevelBelowWarningLevel" 0 "PressLevelSufficient";
VAL_ 2365449982 HydBrkPressWarningStateCircuit1 3 "NotAvailable" 2 "ErrorIndicator" 1 "PressLevelBelowWarningLevel" 0 "PressLevelSufficient";
VAL_ 2566759678 EnggmntSttusTransInputShaftPTO1 3 "NotAvailable" 2 "Error" 1 "DriveIsEngaged" 0 "DriveNotEngaged";
VAL_ 2566759678 EnggmntSttusTransInputShaftPTO2 3 "NotAvailable" 2 "Error" 1 "DriveIsEngaged" 0 "DriveNotEngaged";
VAL_ 2566759678 EnggmntSttusTransOutputShaftPTO 3 "NotAvailable" 2 "Error" 1 "DriveIsEngaged" 0 "DriveNotEngaged";
VAL_ 2566759678 EnggmntSttsTrnsfrCsOtptShaftPTO 3 "NotAvailable" 2 "Error" 1 "DriveIsEngaged" 0 "DriveNotEngaged";
VAL_ 2566759678 EnggmntCnsntTransInputShaftPTO1 3 "NotAvailable" 2 "Error" 1 "CnsentGivenPTODriveMayBeEngaged" 0 "CnsntNtGvnPTODrvShldNtBeEngaged";
VAL_ 2566759678 EnggmntCnsntTransInputShaftPTO2 3 "NotAvailable" 2 "Error" 1 "CnsentGivenPTODriveMayBeEngaged" 0 "CnsntNtGvnPTODrvShldNtBeEngaged";
VAL_ 2566759678 EnggmntCnsntTransOutputShaftPTO 3 "NotAvailable" 2 "Error" 1 "CnsentGivenPTODriveMayBeEngaged" 0 "CnsntNtGvnPTODrvShldNtBeEngaged";
VAL_ 2566759678 EnggmntCnsntTrnsfrCsOtptShftPTO 3 "NotAvailable" 2 "Error" 1 "CnsentGivenPTODriveMayBeEngaged" 0 "CnsntNtGvnPTODrvShldNtBeEngaged";
VAL_ 2566759678 EnableSwitchTransInputShaftPTO1 3 "NotAvailable" 2 "Error" 1 "EnblSwtchOffPTOOperationDesired" 0 "EnblSwtchOffPTOOprtonNotDesired";
VAL_ 2566759678 EnableSwitchTransInputShaftPTO2 3 "NotAvailable" 2 "Error" 1 "EnblSwtchOffPTOOperationDesired" 0 "EnblSwtchOffPTOOprtonNotDesired";
VAL_ 2566759678 EnableSwitchTransOutputShaftPTO 3 "NotAvailable" 2 "Error" 1 "EnblSwtchOffPTOOperationDesired" 0 "EnblSwtchOffPTOOprtonNotDesired";
VAL_ 2566759678 EnblSwtchTrnsfrCsOutputShaftPTO 3 "NotAvailable" 2 "Error" 1 "EnblSwtchOffPTOOperationDesired" 0 "EnblSwtchOffPTOOprtonNotDesired";
VAL_ 2566759678 EnggmntSttsPTOEngAccssoryDrive2 3 "NotAvailable" 2 "Error" 1 "DriveEngaged" 0 "DriveNotEngaged";
VAL_ 2566759678 EnggmntSttsPTOEngAccssoryDrive1 3 "NotAvailable" 2 "Error" 1 "DriveEngaged" 0 "DriveNotEngaged";
VAL_ 2566759678 EnggmntCnsntPTOEngAccssryDrive2 3 "NotAvailable" 2 "Error" 1 "CnsentGivenPTODriveMayBeEngaged" 0 "CnsntNtGvnPTODrvMayNotBeEngaged";
VAL_ 2566759678 EnggmntCnsntPTOEngAccssryDrive1 3 "NotAvailable" 2 "Error" 1 "CnsentGivenPTODriveMayBeEngaged" 0 "CnsntNtGvnPTODrvMayNotBeEngaged";
VAL_ 2566759678 EngagementStatusPTOEngFlywheel 3 "NotAvailable" 2 "Error" 1 "DriveEngaged" 0 "DriveNotEngaged";
VAL_ 2566759678 EngagementConsentPTOEngFlywheel 3 "NotAvailable" 2 "Error" 1 "CnsentGivenPTODriveMayBeEngaged" 0 "CnsntNtGvnPTODrvMayNotBeEngaged";
VAL_ 2566759678 EnblSwitchPTOEngAccessoryDrive2 3 "NotAvailable" 2 "Error" 1 "EnblSwitchOnPTOOperationDesired" 0 "EnblSwtchOffPTOOprtonNotDesired";
VAL_ 2566759678 EnblSwitchPTOEngAccessoryDrive1 3 "NotAvailable" 2 "Error" 1 "EnblSwitchOnPTOOperationDesired" 0 "EnblSwtchOffPTOOprtonNotDesired";
VAL_ 2566759678 EnableSwitchPTOEngFlywheel 3 "NotAvailable" 2 "Error" 1 "EnblSwitchOnPTOOperationDesired" 0 "EnblSwtchOffPTOOprtonNotDesired";
VAL_ 2566759678 AtLeastOnePTOEngaged 3 "NotAvailable" 2 "Error" 1 "AtLeastOnePTODriveIsEngaged" 0 "NoPTODriveIsEngaged";
VAL_ 2432541694 EngTrbCmprssrBypssActtr1TmpStts 7 "NotAvailable" 6 "Error" 5 "NotDefined" 4 "LowMostSevere" 3 "LowLeastSevere" 2 "InRange" 1 "HighLeastSevere" 0 "HighMostSevere";
VAL_ 2432541694 EngTrbCmprssrBypassActuator2Cmd 4 "RprsntsFllyOpnTypcllyTrbCmprssr";
VAL_ 2432541694 EngTrbCmprssrBypassActuator1Pos 4 "RprsntsBypssFllyOpnTypcllyCmprs";
VAL_ 2432541694 EngTrbCmprssrBypassActuator1Cmd 4 "RprsntsFllyOpnTypcllyTrbCmprssr";
VAL_ 2566759934 EnableStatusOfDoor10 3 "notAvailable" 2 "error" 1 "doorEnabled" 0 "doorDisabled";
VAL_ 2566759934 OpenStatusOfDoor10 3 "notAvailable" 2 "error" 1 "doorOpened" 0 "doorClosed";
VAL_ 2566759934 LockStatusOfDoor10 3 "notAvailable" 2 "error" 1 "locked" 0 "unlocked";
VAL_ 2566759934 EnableStatusOfDoor9 3 "notAvailable" 2 "error" 1 "doorEnabled" 0 "doorDisabled";
VAL_ 2566759934 OpenStatusOfDoor9 3 "notAvailable" 2 "error" 1 "doorOpened" 0 "doorClosed";
VAL_ 2566759934 LockStatusOfDoor9 3 "notAvailable" 2 "error" 1 "locked" 0 "unlocked";
VAL_ 2566759934 EnableStatusOfDoor8 3 "notAvailable" 2 "error" 1 "doorEnabled" 0 "doorDisabled";
VAL_ 2566759934 OpenStatusOfDoor8 3 "notAvailable" 2 "error" 1 "doorOpened" 0 "doorClosed";
VAL_ 2566759934 LockStatusOfDoor8 3 "notAvailable" 2 "error" 1 "locked" 0 "unlocked";
VAL_ 2566759934 EnableStatusOfDoor7 3 "notAvailable" 2 "error" 1 "doorEnabled" 0 "doorDisabled";
VAL_ 2566759934 OpenStatusOfDoor7 3 "notAvailable" 2 "error" 1 "doorOpened" 0 "doorClosed";
VAL_ 2566759934 LockStatusOfDoor7 3 "notAvailable" 2 "error" 1 "locked" 0 "unlocked";
VAL_ 2566759934 EnableStatusOfDoor6 3 "notAvailable" 2 "error" 1 "doorEnabled" 0 "doorDisabled";
VAL_ 2566759934 OpenStatusOfDoor6 3 "notAvailable" 2 "error" 1 "doorOpened" 0 "doorClosed";
VAL_ 2566759934 LockStatusOfDoor6 3 "notAvailable" 2 "error" 1 "locked" 0 "unlocked";
VAL_ 2566759934 EnableStatusOfDoor5 3 "notAvailable" 2 "error" 1 "doorEnabled" 0 "doorDisabled";
VAL_ 2566759934 OpenStatusOfDoor5 3 "notAvailable" 2 "error" 1 "doorOpened" 0 "doorClosed";
VAL_ 2566759934 LockStatusOfDoor5 3 "notAvailable" 2 "error" 1 "locked" 0 "unlocked";
VAL_ 2566759934 EnableStatusOfDoor4 3 "notAvailable" 2 "error" 1 "doorEnabled" 0 "doorDisabled";
VAL_ 2566759934 OpenStatusOfDoor4 3 "notAvailable" 2 "error" 1 "doorOpened" 0 "doorClosed";
VAL_ 2566759934 LockStatusOfDoor4 3 "notAvailable" 2 "error" 1 "locked" 0 "unlocked";
VAL_ 2566759934 EnableStatusOfDoor3 3 "notAvailable" 2 "error" 1 "doorEnabled" 0 "doorDisabled";
VAL_ 2566759934 OpenStatusOfDoor3 3 "notAvailable" 2 "error" 1 "doorOpened" 0 "doorClosed";
VAL_ 2566759934 LockStatusOfDoor3 3 "notAvailable" 2 "error" 1 "locked" 0 "unlocked";
VAL_ 2566759934 EnableStatusOfDoor2 3 "notAvailable" 2 "error" 1 "doorEnabled" 0 "doorDisabled";
VAL_ 2566759934 OpenStatusOfDoor2 3 "notAvailable" 2 "error" 1 "doorOpened" 0 "doorClosed";
VAL_ 2566759934 LockStatusOfDoor2 3 "notAvailable" 2 "error" 1 "locked" 0 "unlocked";
VAL_ 2566759934 EnableStatusOfDoor1 3 "notAvailable" 2 "error" 1 "doorEnabled" 0 "doorDisabled";
VAL_ 2566759934 OpenStatusOfDoor1 3 "notAvailable" 2 "error" 1 "doorOpened" 0 "doorClosed";
VAL_ 2566759934 LockStatusOfDoor1 3 "notAvailable" 2 "error" 1 "locked" 0 "unlocked";
VAL_ 2566757374 Aftrtrtmnt1SCRCtlystReagentType 15 "NotAvailable" 14 "ErrrDtctdWthUrRgntTypeDetection" 13 "NtAblTDtrmneCatalystReagentType" 5 "to1100ReservedForSAEAssignment" 3 "CatalystReagentIsProperMixture" 2 "CatalystReagentIsDiesel" 1 "CtlystRgntIsUrCncntrationTooLow" 0 "CtlystRgntIsUrCncntrtionTooHigh";
VAL_ 2364544766 EngCyl9CombustionStatus 3 "NotAvailable" 2 "Error" 1 "CombustionExists" 0 "NoCombustion";
VAL_ 2364544766 EngCyl8CombustionStatus 3 "NotAvailable" 2 "Error" 1 "CombustionExists" 0 "NoCombustion";
VAL_ 2364544766 EngCyl7CombustionStatus 3 "NotAvailable" 2 "Error" 1 "CombustionExists" 0 "NoCombustion";
VAL_ 2364544766 EngCyl6CombustionStatus 3 "NotAvailable" 2 "Error" 1 "CombustionExists" 0 "NoCombustion";
VAL_ 2364544766 EngCyl5CombustionStatus 1 "CombustionExists" 0 "NoCombustion" 3 "NotAvailable" 2 "Error";
VAL_ 2364544766 EngCyl4CombustionStatus 3 "NotAvailable" 2 "Error" 1 "CombustionExists" 0 "NoCombustion";
VAL_ 2364544766 EngCyl3CombustionStatus 3 "NotAvailable" 2 "Error" 1 "CombustionExists" 0 "NoCombustion";
VAL_ 2364544766 EngCyl2CombustionStatus 3 "NotAvailable" 2 "Error" 1 "CombustionExists" 0 "NoCombustion";
VAL_ 2364544766 EngCyl24CombustionStatus 3 "NotAvailable" 2 "Error" 1 "CombustionExists" 0 "NoCombustion";
VAL_ 2364544766 EngCyl23CombustionStatus 3 "NotAvailable" 2 "Error" 1 "CombustionExists" 0 "NoCombustion";
VAL_ 2364544766 EngCyl22CombustionStatus 3 "NotAvailable" 2 "Error" 1 "CombustionExists" 0 "NoCombustion";
VAL_ 2364544766 EngCyl21CombustionStatus 3 "NotAvailable" 2 "Error" 1 "CombustionExists" 0 "NoCombustion";
VAL_ 2364544766 EngCyl20CombustionStatus 3 "NotAvailable" 2 "Error" 1 "CombustionExists" 0 "NoCombustion";
VAL_ 2364544766 EngCyl1CombustionStatus 3 "NotAvailable" 2 "Error" 1 "CombustionExists" 0 "NoCombustion";
VAL_ 2364544766 EngCyl19CombustionStatus 3 "NotAvailable" 2 "Error" 1 "CombustionExists" 0 "NoCombustion";
VAL_ 2364544766 EngCyl18CombustionStatus 3 "NotAvailable" 2 "Error" 1 "CombustionExists" 0 "NoCombustion";
VAL_ 2364544766 EngCyl17CombustionStatus 3 "NotAvailable" 2 "Error" 1 "CombustionExists" 0 "NoCombustion";
VAL_ 2364544766 EngCyl16CombustionStatus 3 "NotAvailable" 2 "Error" 1 "CombustionExists" 0 "NoCombustion";
VAL_ 2364544766 EngCyl15CombustionStatus 3 "NotAvailable" 2 "Error" 1 "CombustionExists" 0 "NoCombustion";
VAL_ 2364544766 EngCyl14CombustionStatus 3 "NotAvailable" 2 "Error" 1 "CombustionExists" 0 "NoCombustion";
VAL_ 2364544766 EngCyl13CombustionStatus 3 "NotAvailable" 2 "Error" 1 "CombustionExists" 0 "NoCombustion";
VAL_ 2364544766 EngCyl12CombustionStatus 3 "NotAvailable" 2 "Error" 1 "CombustionExists" 0 "NoCombustion";
VAL_ 2364544766 EngCyl11CombustionStatus 3 "NotAvailable" 2 "Error" 1 "CombustionExists" 0 "NoCombustion";
VAL_ 2364544766 EngCyl10CombustionStatus 3 "NotAvailable" 2 "Error" 1 "CombustionExists" 0 "NoCombustion";
VAL_ 2364544510 RqGenOverallPowerFactorLagging 3 "NotAvailable" 2 "Error" 1 "Lagging" 0 "Leading";
VAL_ 2364544254 RlativeBladeHeightFigureOfMerit 3 "RelativeBladeHeightNotAvailable" 2 "RelativeBladeHeightFailed" 1 "RltvBldHghtDgrddDtIsSspctDTEnvr" 0 "RltvBldHghtFllyFnctnlDtIsWthnSn";
VAL_ 2364544254 BladeRotationAngleFigureOfMerit 3 "BladeRotationAngleNotAvailable" 2 "BldRttnAnglFldRllSnsrFldTOprtCr" 1 "BldRttnAnglDgrddDtIsSspctDTEnvr" 0 "BldRttnAnglFllyFnctnlDtIsWthnSn";
VAL_ 2349006590 VehicleType 1 "Dolly axle" 0 "Towing or towed vehicle";
VAL_ 2349006590 BrakeLightSwitch 1 "Switch on" 0 "Switch off";
VAL_ 2349006590 ASREngineControlActive 3 "NotAvailable" 2 "Reserved" 1 "ASREngineControlActive" 0 "ASREngnCntrlPassiveButInstalled";
VAL_ 2349006590 ASRBreakControlActive 1 "Active" 0 "Passive, but installed";
VAL_ 2349006590 VehicleRetarderCtrlActive 1 "Active" 0 "Passive";
VAL_ 2349006590 VehicleABSActive 1 "Active" 0 "Passiv, but installed";
VAL_ 2566834686 PneumaticControlLine 1 "Towing veh with pn ctrl line" 0 "Towing veh without pn ctrl line";
VAL_ 2566834686 ABSOffroadRequest 1 "ABS off-road switch on" 0 "ABS off-road switch off";
VAL_ 2566834686 TwoElCircuitsBrakeDemand 1 "Two el. circuit brake available" 0 "One el. circuit brake available";
VAL_ 2566834686 VehicleRetarderCtrlActive 1 "Active" 0 "Passive";
VAL_ 2550398718 SupplyLineBrakingRequest 1 "Supply line braking request" 0 "No supply line braking request";
VAL_ 2550398718 VDCActive 1 "Active" 0 "Passive, but installed";
VAL_ 2550398718 AutomTowedVehBreakActive 1 "Active" 0 "Passive";
VAL_ 2550398718 VehicleServiceBrakeActive 1 "Active" 0 "Passive";
VAL_ 2550398718 VehicleRetarderCtrlActive 1 "Active" 0 "Passive";
VAL_ 2550398718 VehicleABSActive 1 "Active" 0 "Passiv, but installed";
VAL_ 2566833406 SupplyLineBrakingRequest 1 "Supply line braking request" 0 "No supply line braking request";
VAL_ 2566833406 LoadingRampApproachAssist 1 "Assistance active" 0 "Assistance not active";
VAL_ 2566833406 SpringBrakeEngaged 1 "Vehicle spring brake is engaged" 0 "Vehicle spring brake is released";
VAL_ 2566833406 ElectrLoadPropFunc 1 "Vehicle with el. load proportion" 0 "Vehicle without el. load proport";
VAL_ 2566833406 SpringBrakeInstalled 1 "Vehicle with spring brakes" 0 "Vehicle without spring brakes";
VAL_ 2566833406 VehicleType 1 "Dolly axle" 0 "Towing or towed vehicle";
VAL_ 2566833406 ElecSupplyOfNonBrakingSys 1 "Supply switched on" 0 "Supply switched off";
VAL_ 2566833406 AmberWarningSignalReq 1 "Towed vehicle failure indicated" 0 "No towed vehicle failure indicat";
VAL_ 2566833406 RedWarningSignalRequest 1 "Towed vehicle failure indicated" 0 "No towed vehicle failure indicat";
VAL_ 2566833406 VehicleElectrSupplySuff 1 "Vehicle el. supply sufficient" 0 "Vehicle el. supply insufficient";
VAL_ 2566833406 AutomTowedVehBreakActive 1 "Active" 0 "Passive";
VAL_ 2566833406 VehicleServiceBrakeActive 1 "Active" 0 "Passive";
VAL_ 2566833406 VehicleRetarderCtrlActive 1 "Active" 0 "Passive";
VAL_ 2566833406 VehicleABSActive 1 "Active" 0 "Passiv, but installed";
VAL_ 2365507326 TyreWheelIdentTemp2 15 "Axle position 15" 14 "Axle position 14" 13 "Axle position 13" 12 "Axle position 12" 11 "Axle position 11" 10 "Axle position 10" 9 "Axle position 9" 8 "Axle position 8" 7 "Axle position 7" 6 "Axle position 6" 5 "Axle position 5" 4 "Axle position 4" 3 "Axle position 3" 2 "Axle position 2" 1 "Axle position 1" 0 "Axle position not identified";
VAL_ 2365507326 TyreWheelIdentTemp1 15 "Wheel position 15" 14 "Wheel position 14" 13 "Wheel position 13" 12 "Wheel position 12" 11 "Wheel position 11" 10 "Wheel position 10" 9 "Wheel position 9" 8 "Wheel position 8" 7 "Wheel position 7" 6 "Wheel position 6" 5 "Wheel position 5" 4 "Wheel position 4" 3 "Wheel position 3" 2 "Wheel position 2" 1 "Wheel position 1" 0 "Wheel position not identified";
VAL_ 2365507326 TyreWheelIdentPressure2 15 "Axle position 15" 14 "Axle position 14" 13 "Axle position 13" 12 "Axle position 12" 11 "Axle position 11" 10 "Axle position 10" 9 "Axle position 9" 8 "Axle position 8" 7 "Axle position 7" 6 "Axle position 6" 5 "Axle position 5" 4 "Axle position 4" 3 "Axle position 3" 2 "Axle position 2" 1 "Axle position 1" 0 "Axle position not identified";
VAL_ 2365507326 TyreWheelIdentPressure1 15 "Wheel position 15" 14 "Wheel position 14" 13 "Wheel position 13" 12 "Wheel position 12" 11 "Wheel position 11" 10 "Wheel position 10" 9 "Wheel position 9" 8 "Wheel position 8" 7 "Wheel position 7" 6 "Wheel position 6" 5 "Wheel position 5" 4 "Wheel position 4" 3 "Wheel position 3" 2 "Wheel position 2" 1 "Wheel position 1" 0 "Wheel position not identified";
VAL_ 2365507326 TyreWheelIdentLining2 15 "Axle position 15" 14 "Axle position 14" 13 "Axle position 13" 12 "Axle position 12" 11 "Axle position 11" 10 "Axle position 10" 9 "Axle position 9" 8 "Axle position 8" 7 "Axle position 7" 6 "Axle position 6" 5 "Axle position 5" 4 "Axle position 4" 3 "Axle position 3" 2 "Axle position 2" 1 "Axle position 1" 0 "Axle position not identified";
VAL_ 2365507326 TyreWheelIdentLining1 15 "Wheel position 15" 14 "Wheel position 14" 13 "Wheel position 13" 12 "Wheel position 12" 11 "Wheel position 11" 10 "Wheel position 10" 9 "Wheel position 9" 8 "Wheel position 8" 7 "Wheel position 7" 6 "Wheel position 6" 5 "Wheel position 5" 4 "Wheel position 4" 3 "Wheel position 3" 2 "Wheel position 2" 1 "Wheel position 1" 0 "Wheel position not identified";
VAL_ 2365507326 VehiclePneumSupplySuff 1 "Pneumatic supply sufficient" 0 "Pneumatic supply insufficient";
VAL_ 2365507326 BrakeTemperatureStatus 1 "Brake temperature normal" 0 "Brake temperature out of range";
VAL_ 2365507326 BrakeLiningSufficient 1 "Brake linings sufficient" 0 "Brake linings insufficient";
VAL_ 2365507326 TyrePressureSufficient 1 "Tyre pressure sufficient" 0 "Tyre pressure insufficient";
VAL_ 2565013246 ODDRequest 3 "Take no action" 1 "ODD on" 0 "ODD off";
VAL_ 2565013246 AntiTheftDeviceReq 3 "Take no action" 1 "Anti-theft device on" 0 "Anti-theft device off";
VAL_ 2565013246 VehicleType 1 "Dolly axle" 0 "Towing or towed vehicle";
VAL_ 2365480958 EngineTorqueMode 15 "Not available" 11 "Remote accelerator" 10 "Braking system" 9 "High speed governor" 8 "Torque limiting" 7 "ABS control" 6 "Transmission control" 5 "ASR control" 4 "Road speed governor" 3 "PTO governor" 2 "Cruise control" 1 "Accelerator pedal/operator selec" 0 "Low idle governor/no request (de";
VAL_ 2365480958 EngineRunning 1 "Engine running" 0 "Engine not running";
VAL_ 2365480958 EngineControlAllowed 1 "Engine control allowed" 0 "Engine control not allowed";
VAL_ 2566808062 ClutchIndptdPTOFeedback 1 "Engaged" 0 "Not engaged";
VAL_ 2566808062 AccelPedalLowIdleSwitch 1 "In low idle condition" 0 "Not in low idle condition";
VAL_ 2566808062 StarterActive 1 "Starter active" 0 "Starter not active";
VAL_ 2566808062 TorqueConvtOilTempWarning 2 "Warning" 1 "Prewarning" 0 "No warning";
VAL_ 2566808062 PTOControlAllowed 1 "PTO control allowed" 0 "PTO control not allowed";
VAL_ 2566808062 SecEngineMtdPTOFeedback 1 "Limits activated" 0 "Limits not activated";
VAL_ 2566808062 FirstEngineMtdPTOFeedback 1 "Limits activated" 0 "Limits not activated";
VAL_ 2566808062 SecClutchDptdPTOFeedback 1 "Engaged" 0 "Not engaged";
VAL_ 2566808062 FirstClutchDpdtPTOFeedback 1 "Engaged" 0 "Not engaged";
VAL_ 2566808574 FuelLevelWarning 1 "Fuel level warning on" 0 "Fuel level warning off";
VAL_ 2566808574 EngineOilPressureWarning 1 "Warning" 0 "No warning";
VAL_ 2566808574 EngineCoolantTempWarning 2 "Warning" 1 "Prewarning" 0 "No warning";
VAL_ 2564947710 VehicleType 1 "Dolly axle" 0 "Towing or towed vehicle";
VAL_ 2566834430 AntiTheftDeviceStatus 1 "Anti-theft device on" 0 "Anti-theft device off";
VAL_ 2566834430 ODDStatus 1 "ODD active" 0 "ODD inactive";
VAL_ 2566808318 SecEngineMtdPTOSwitch 1 "Switched on" 0 "Switched off";
VAL_ 2566808318 SecClutchDpdtPTOSwitch 1 "Switched on" 0 "Switched off";
VAL_ 2566808318 FirstClutchDpdtPTOSwitch 1 "Switched on" 0 "Switched off";
VAL_ 2566808318 OperatingPanelActive 1 "Operating panel active" 0 "Operating panel not active";
VAL_ 2566808318 RefusePackerStepSwitch 1 "Switched on" 0 "Switched off";
VAL_ 2566808318 EngineStopSwitch 1 "Switched on" 0 "Switched off";
VAL_ 2566808318 EngineStartSwitch 1 "Switched on" 0 "Switched off";
VAL_ 2566808318 StarterLockoutSwitch 1 "Switched on" 0 "Switched off";
VAL_ 2566808318 FirstEngineMtdPTOSwitch 1 "Switched on" 0 "Switched off";
VAL_ 2566808318 ClutchIndpdtPTOSwitch 1 "Switched on" 0 "Switched off";
VAL_ 2566808830 TrailerLeftSideMarkerLight 1 "Lamp(s) lit" 0 "Lamp(s) not lit";
VAL_ 2566808830 TrailerLeftReversingLight 1 "Lamp(s) lit" 0 "Lamp(s) not lit";
VAL_ 2566808830 TrailerLeftRearWidIndLight 1 "Lamp(s) lit" 0 "Lamp(s) not lit";
VAL_ 2566808830 TrailerLeftRearRegPltLight 1 "Lamp(s) lit" 0 "Lamp(s) not lit";
VAL_ 2566808830 TrailerLeftRearLight 1 "Lamp(s) lit" 0 "Lamp(s) not lit";
VAL_ 2566808830 TrailerLeftRearFogLight 1 "Lamp(s) lit" 0 "Lamp(s) not lit";
VAL_ 2566808830 TrailerLeftDirIndLight 1 "Lamp(s) lit" 0 "Lamp(s) not lit";
VAL_ 2566808830 TrailerLeftCrnMarkerLight 1 "Lamp(s) lit" 0 "Lamp(s) not lit";
VAL_ 2566808830 TrailerInteriorLight 1 "Lamp(s) lit" 0 "Lamp(s) not lit";
VAL_ 2566808830 TrailerWorkLamp 1 "Lamp(s) lit" 0 "Lamp(s) not lit";
VAL_ 2566808830 TrailerRotatingIdentLight 1 "Lamp(s) lit" 0 "Lamp(s) not lit";
VAL_ 2566808830 TrailerRightStopLight 1 "Lamp(s) lit" 0 "Lamp(s) not lit";
VAL_ 2566808830 TrailerRightSideMrkLight 1 "Lamp(s) lit" 0 "Lamp(s) not lit";
VAL_ 2566808830 TrailerRightReversingLight 1 "Lamp(s) lit" 0 "Lamp(s) not lit";
VAL_ 2566808830 TrailRightRearWidIndLight 1 "Lamp(s) lit" 0 "Lamp(s) not lit";
VAL_ 2566808830 TrailerRightRearRegPltLight 1 "Lamp(s) lit" 0 "Lamp(s) not lit";
VAL_ 2566808830 TrailerRightRearLight 1 "Lamp(s) lit" 0 "Lamp(s) not lit";
VAL_ 2566808830 TrailerRightRearFogLight 1 "Lamp(s) lit" 0 "Lamp(s) not lit";
VAL_ 2566808830 TrailerRightDirIndLight 1 "Lamp(s) lit" 0 "Lamp(s) not lit";
VAL_ 2566808830 TrailerRightCrnMarkerLight 1 "Lamp(s) lit" 0 "Lamp(s) not lit";
VAL_ 2566808830 TrailerRearWarningLight 1 "Lamp(s) lit" 0 "Lamp(s) not lit";
VAL_ 2566808830 TrailerLeftStopLight 1 "Lamp(s) lit" 0 "Lamp(s) not lit";
VAL_ 2564554494 FlowStatus 2 "Overflow" 1 "Wait " 0 "Continue To Send";
VAL_ 2564554494 ProtocolCtrlInformation 3 "Flow control " 2 "Consecutive frame" 1 "First frame" 0 "Single frame";
VAL_ 2564488958 FlowStatus 2 "Overflow" 1 "Wait " 0 "Continue To Send";
VAL_ 2564488958 ProtocolCtrlInformation 3 "Flow control " 2 "Consecutive frame" 1 "First frame" 0 "Single frame";
VAL_ 2565734142 ControlByte 6 "MFDB_CreateEntry" 5 "MFDB_SetMode" 4 "MFDB_Clear" 3 "MFDB_Delete" 2 "MFDB_Add" 1 "MFDB_Response" 0 "MFDB_Request";
VAL_ 2565734142 FilterMode 1 "PassSpecificPGNs" 0 "BlockSpecificPGNs";
